[part 2 of 4: package /PATAC/MSM/ComponentTypes]
AUTOSAR XML (schema 4-0-3)
package /PATAC/MSM/ComponentTypes  (continued)
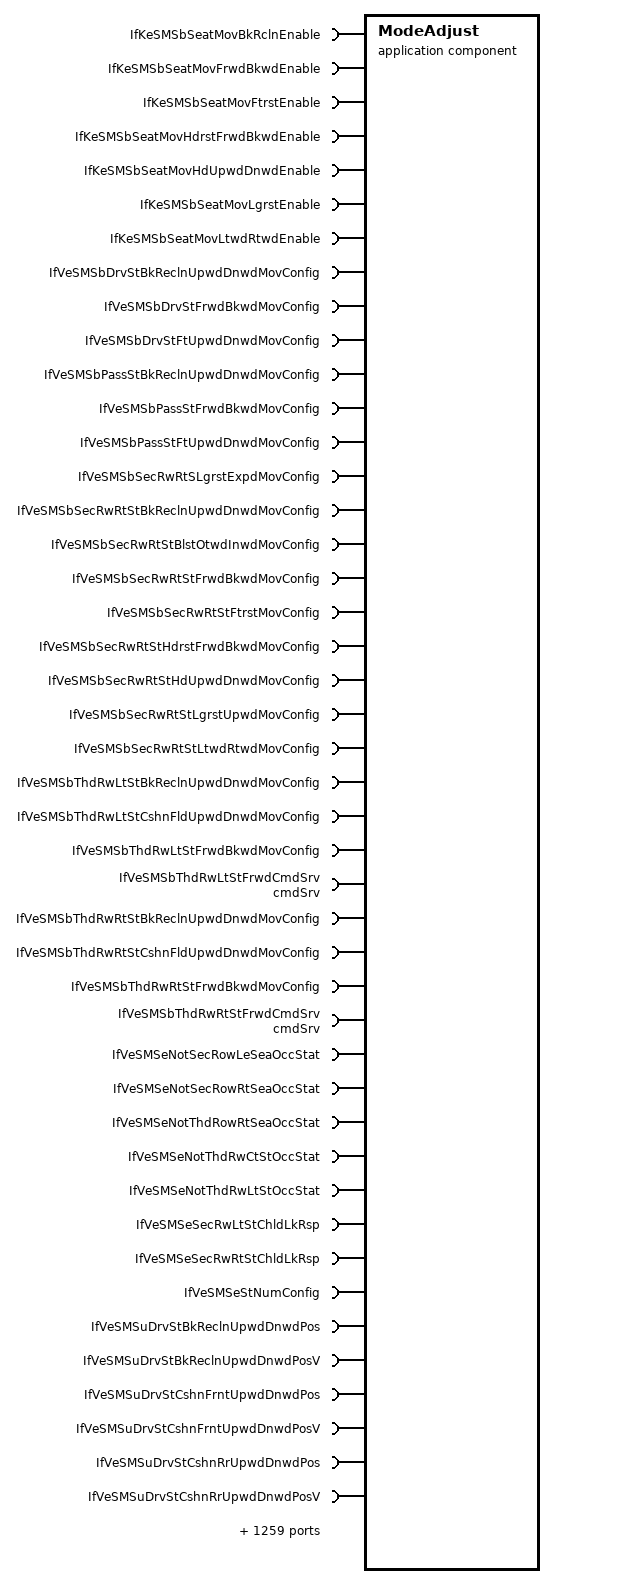
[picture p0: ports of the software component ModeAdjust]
  application sw component type ModeAdjust  (continued)
    1303 x require port:
      IfKeSMSbSeatMovBkRclnEnable: parameter-require-com-spec{init-value=1, parameter=IfKeSMSbSeatMovBkRclnEnable/Val}, required-interface=IfKeSMSbSeatMovBkRclnEnable
      IfKeSMSbSeatMovFrwdBkwdEnable: parameter-require-com-spec{init-value=1, parameter=IfKeSMSbSeatMovFrwdBkwdEnable/Val}, required-interface=IfKeSMSbSeatMovFrwdBkwdEnable
      IfKeSMSbSeatMovFtrstEnable: parameter-require-com-spec{init-value=1, parameter=IfKeSMSbSeatMovFtrstEnable/Val}, required-interface=IfKeSMSbSeatMovFtrstEnable
      IfKeSMSbSeatMovHdrstFrwdBkwdEnable: parameter-require-com-spec{init-value=1, parameter=IfKeSMSbSeatMovHdrstFrwdBkwdEnable/Val}, required-interface=IfKeSMSbSeatMovHdrstFrwdBkwdEnable
      IfKeSMSbSeatMovHdUpwdDnwdEnable: parameter-require-com-spec{init-value=1, parameter=IfKeSMSbSeatMovHdUpwdDnwdEnable/Val}, required-interface=IfKeSMSbSeatMovHdUpwdDnwdEnable
      IfKeSMSbSeatMovLgrstEnable: parameter-require-com-spec{init-value=1, parameter=IfKeSMSbSeatMovLgrstEnable/Val}, required-interface=IfKeSMSbSeatMovLgrstEnable
      IfKeSMSbSeatMovLtwdRtwdEnable: parameter-require-com-spec{init-value=1, parameter=IfKeSMSbSeatMovLtwdRtwdEnable/Val}, required-interface=IfKeSMSbSeatMovLtwdRtwdEnable
      IfVeSMSbDrvStBkReclnUpwdDnwdMovConfig: nonqueued-receiver-com-spec{data-element=IfVeSMSbDrvStBkReclnUpwdDnwdMovConfig/Val, filter=data-filter-type=ALWAYS, init-value=0}, required-interface=IfVeSMSbDrvStBkReclnUpwdDnwdMovConfig
      IfVeSMSbDrvStFrwdBkwdMovConfig: nonqueued-receiver-com-spec{data-element=IfVeSMSbDrvStFrwdBkwdMovConfig/Val, filter=data-filter-type=ALWAYS, init-value=0}, required-interface=IfVeSMSbDrvStFrwdBkwdMovConfig
      IfVeSMSbDrvStFtUpwdDnwdMovConfig: nonqueued-receiver-com-spec{data-element=IfVeSMSbDrvStFtUpwdDnwdMovConfig/Val, filter=data-filter-type=ALWAYS, init-value=0}, required-interface=IfVeSMSbDrvStFtUpwdDnwdMovConfig
      IfVeSMSbPassStBkReclnUpwdDnwdMovConfig: nonqueued-receiver-com-spec{data-element=IfVeSMSbPassStBkReclnUpwdDnwdMovConfig/Val, filter=data-filter-type=ALWAYS, init-value=0}, required-interface=IfVeSMSbPassStBkReclnUpwdDnwdMovConfig
      IfVeSMSbPassStFrwdBkwdMovConfig: nonqueued-receiver-com-spec{data-element=IfVeSMSbPassStFrwdBkwdMovConfig/Val, filter=data-filter-type=ALWAYS, init-value=0}, required-interface=IfVeSMSbPassStFrwdBkwdMovConfig
      IfVeSMSbPassStFtUpwdDnwdMovConfig: nonqueued-receiver-com-spec{data-element=IfVeSMSbPassStFtUpwdDnwdMovConfig/Val, filter=data-filter-type=ALWAYS, init-value=0}, required-interface=IfVeSMSbPassStFtUpwdDnwdMovConfig
      IfVeSMSbSecRwRtSLgrstExpdMovConfig: nonqueued-receiver-com-spec{data-element=IfVeSMSbSecRwRtSLgrstExpdMovConfig/Val, filter=data-filter-type=ALWAYS, init-value=0}, required-interface=IfVeSMSbSecRwRtSLgrstExpdMovConfig
      IfVeSMSbSecRwRtStBkReclnUpwdDnwdMovConfig: nonqueued-receiver-com-spec{data-element=IfVeSMSbSecRwRtStBkReclnUpwdDnwdMovConfig/Val, filter=data-filter-type=ALWAYS, init-value=0}, required-interface=IfVeSMSbSecRwRtStBkReclnUpwdDnwdMovConfig
      IfVeSMSbSecRwRtStBlstOtwdInwdMovConfig: nonqueued-receiver-com-spec{data-element=IfVeSMSbSecRwRtStBlstOtwdInwdMovConfig/Val, filter=data-filter-type=ALWAYS, init-value=0}, required-interface=IfVeSMSbSecRwRtStBlstOtwdInwdMovConfig
      IfVeSMSbSecRwRtStFrwdBkwdMovConfig: nonqueued-receiver-com-spec{data-element=IfVeSMSbSecRwRtStFrwdBkwdMovConfig/Val, filter=data-filter-type=ALWAYS, init-value=0}, required-interface=IfVeSMSbSecRwRtStFrwdBkwdMovConfig
      IfVeSMSbSecRwRtStFtrstMovConfig: nonqueued-receiver-com-spec{data-element=IfVeSMSbSecRwRtStFtrstMovConfig/Val, filter=data-filter-type=ALWAYS, init-value=0}, required-interface=IfVeSMSbSecRwRtStFtrstMovConfig
      IfVeSMSbSecRwRtStHdrstFrwdBkwdMovConfig: nonqueued-receiver-com-spec{data-element=IfVeSMSbSecRwRtStHdrstFrwdBkwdMovConfig/Val, filter=data-filter-type=ALWAYS, init-value=0}, required-interface=IfVeSMSbSecRwRtStHdrstFrwdBkwdMovConfig
      IfVeSMSbSecRwRtStHdUpwdDnwdMovConfig: nonqueued-receiver-com-spec{data-element=IfVeSMSbSecRwRtStHdUpwdDnwdMovConfig/Val, filter=data-filter-type=ALWAYS, init-value=0}, required-interface=IfVeSMSbSecRwRtStHdUpwdDnwdMovConfig
      IfVeSMSbSecRwRtStLgrstUpwdMovConfig: nonqueued-receiver-com-spec{data-element=IfVeSMSbSecRwRtStLgrstUpwdMovConfig/Val, filter=data-filter-type=ALWAYS, init-value=0}, required-interface=IfVeSMSbSecRwRtStLgrstUpwdMovConfig
      IfVeSMSbSecRwRtStLtwdRtwdMovConfig: nonqueued-receiver-com-spec{data-element=IfVeSMSbSecRwRtStLtwdRtwdMovConfig/Val, filter=data-filter-type=ALWAYS, init-value=0}, required-interface=IfVeSMSbSecRwRtStLtwdRtwdMovConfig
      IfVeSMSbThdRwLtStBkReclnUpwdDnwdMovConfig: nonqueued-receiver-com-spec{data-element=IfVeSMSbThdRwLtStBkReclnUpwdDnwdMovConfig/Val, filter=data-filter-type=ALWAYS, init-value=0}, required-interface=IfVeSMSbThdRwLtStBkReclnUpwdDnwdMovConfig
      IfVeSMSbThdRwLtStCshnFldUpwdDnwdMovConfig: nonqueued-receiver-com-spec{data-element=IfVeSMSbThdRwLtStCshnFldUpwdDnwdMovConfig/Val, filter=data-filter-type=ALWAYS, init-value=0}, required-interface=IfVeSMSbThdRwLtStCshnFldUpwdDnwdMovConfig
      IfVeSMSbThdRwLtStFrwdBkwdMovConfig: nonqueued-receiver-com-spec{data-element=IfVeSMSbThdRwLtStFrwdBkwdMovConfig/Val, filter=data-filter-type=ALWAYS, init-value=0}, required-interface=IfVeSMSbThdRwLtStFrwdBkwdMovConfig
      IfVeSMSbThdRwLtStFrwdCmdSrv: nonqueued-receiver-com-spec{data-element=cmdSrv/Val, filter=data-filter-type=ALWAYS, init-value=1}, required-interface=cmdSrv
      IfVeSMSbThdRwRtStBkReclnUpwdDnwdMovConfig: nonqueued-receiver-com-spec{data-element=IfVeSMSbThdRwRtStBkReclnUpwdDnwdMovConfig/Val, filter=data-filter-type=ALWAYS, init-value=0}, required-interface=IfVeSMSbThdRwRtStBkReclnUpwdDnwdMovConfig
      IfVeSMSbThdRwRtStCshnFldUpwdDnwdMovConfig: nonqueued-receiver-com-spec{data-element=IfVeSMSbThdRwRtStCshnFldUpwdDnwdMovConfig/Val, filter=data-filter-type=ALWAYS, init-value=0}, required-interface=IfVeSMSbThdRwRtStCshnFldUpwdDnwdMovConfig
      IfVeSMSbThdRwRtStFrwdBkwdMovConfig: nonqueued-receiver-com-spec{data-element=IfVeSMSbThdRwRtStFrwdBkwdMovConfig/Val, filter=data-filter-type=ALWAYS, init-value=0}, required-interface=IfVeSMSbThdRwRtStFrwdBkwdMovConfig
      IfVeSMSbThdRwRtStFrwdCmdSrv: nonqueued-receiver-com-spec{data-element=cmdSrv/Val, filter=data-filter-type=ALWAYS, init-value=1}, required-interface=cmdSrv
      IfVeSMSeNotSecRowLeSeaOccStat: nonqueued-receiver-com-spec{data-element=IfVeSMSeNotSecRowLeSeaOccStat/Val, filter=data-filter-type=ALWAYS, init-value=0}, required-interface=IfVeSMSeNotSecRowLeSeaOccStat
      IfVeSMSeNotSecRowRtSeaOccStat: nonqueued-receiver-com-spec{data-element=IfVeSMSeNotSecRowRtSeaOccStat/Val, filter=data-filter-type=ALWAYS, init-value=0}, required-interface=IfVeSMSeNotSecRowRtSeaOccStat
      IfVeSMSeNotThdRowRtSeaOccStat: nonqueued-receiver-com-spec{data-element=IfVeSMSeNotThdRowRtSeaOccStat/Val, filter=data-filter-type=ALWAYS, init-value=0}, required-interface=IfVeSMSeNotThdRowRtSeaOccStat
      IfVeSMSeNotThdRwCtStOccStat: nonqueued-receiver-com-spec{data-element=IfVeSMSeNotThdRwCtStOccStat/Val, filter=data-filter-type=ALWAYS, init-value=0}, required-interface=IfVeSMSeNotThdRwCtStOccStat
      IfVeSMSeNotThdRwLtStOccStat: nonqueued-receiver-com-spec{data-element=IfVeSMSeNotThdRwLtStOccStat/Val, filter=data-filter-type=ALWAYS, init-value=0}, required-interface=IfVeSMSeNotThdRwLtStOccStat
      IfVeSMSeSecRwLtStChldLkRsp: nonqueued-receiver-com-spec{data-element=IfVeSMSeSecRwLtStChldLkRsp/Val, filter=data-filter-type=ALWAYS, init-value=0}, required-interface=IfVeSMSeSecRwLtStChldLkRsp
      IfVeSMSeSecRwRtStChldLkRsp: nonqueued-receiver-com-spec{data-element=IfVeSMSeSecRwRtStChldLkRsp/Val, filter=data-filter-type=ALWAYS, init-value=0}, required-interface=IfVeSMSeSecRwRtStChldLkRsp
      IfVeSMSeStNumConfig: nonqueued-receiver-com-spec{data-element=IfVeSMSeStNumConfig/Val, filter=data-filter-type=ALWAYS, init-value=2}, required-interface=IfVeSMSeStNumConfig
      IfVeSMSuDrvStBkReclnUpwdDnwdPos: nonqueued-receiver-com-spec{data-element=IfVeSMSuDrvStBkReclnUpwdDnwdPos/Val, filter=data-filter-type=ALWAYS, init-value=0}, required-interface=IfVeSMSuDrvStBkReclnUpwdDnwdPos
      IfVeSMSuDrvStBkReclnUpwdDnwdPosV: nonqueued-receiver-com-spec{data-element=IfVeSMSuDrvStBkReclnUpwdDnwdPosV/Val, filter=data-filter-type=ALWAYS, init-value=0}, required-interface=IfVeSMSuDrvStBkReclnUpwdDnwdPosV
      IfVeSMSuDrvStCshnFrntUpwdDnwdPos: nonqueued-receiver-com-spec{data-element=IfVeSMSuDrvStCshnFrntUpwdDnwdPos/Val, filter=data-filter-type=ALWAYS, init-value=0}, required-interface=IfVeSMSuDrvStCshnFrntUpwdDnwdPos
      IfVeSMSuDrvStCshnFrntUpwdDnwdPosV: nonqueued-receiver-com-spec{data-element=IfVeSMSuDrvStCshnFrntUpwdDnwdPosV/Val, filter=data-filter-type=ALWAYS, init-value=0}, required-interface=IfVeSMSuDrvStCshnFrntUpwdDnwdPosV
      IfVeSMSuDrvStCshnRrUpwdDnwdPos: nonqueued-receiver-com-spec{data-element=IfVeSMSuDrvStCshnRrUpwdDnwdPos/Val, filter=data-filter-type=ALWAYS, init-value=0}, required-interface=IfVeSMSuDrvStCshnRrUpwdDnwdPos
      IfVeSMSuDrvStCshnRrUpwdDnwdPosV: nonqueued-receiver-com-spec{data-element=IfVeSMSuDrvStCshnRrUpwdDnwdPosV/Val, filter=data-filter-type=ALWAYS, init-value=0}, required-interface=IfVeSMSuDrvStCshnRrUpwdDnwdPosV
      IfVeSMSuDrvStFrwdBkwdPos: nonqueued-receiver-com-spec{data-element=IfVeSMSuDrvStFrwdBkwdPos/Val, filter=data-filter-type=ALWAYS, init-value=0}, required-interface=IfVeSMSuDrvStFrwdBkwdPos
      IfVeSMSuDrvStFrwdBkwdPosV: nonqueued-receiver-com-spec{data-element=IfVeSMSuDrvStFrwdBkwdPosV/Val, filter=data-filter-type=ALWAYS, init-value=0}, required-interface=IfVeSMSuDrvStFrwdBkwdPosV
      IfVeSMSuDrvStFtUpwdDnwdPos: nonqueued-receiver-com-spec{data-element=IfVeSMSuDrvStFtUpwdDnwdPos/Val, filter=data-filter-type=ALWAYS, init-value=0}, required-interface=IfVeSMSuDrvStFtUpwdDnwdPos
      IfVeSMSuDrvStFtUpwdDnwdPosV: nonqueued-receiver-com-spec{data-element=IfVeSMSuDrvStFtUpwdDnwdPosV/Val, filter=data-filter-type=ALWAYS, init-value=0}, required-interface=IfVeSMSuDrvStFtUpwdDnwdPosV
      IfVeSMSuPassStBkReclnUpwdDnwdPos: nonqueued-receiver-com-spec{data-element=IfVeSMSuPassStBkReclnUpwdDnwdPos/Val, filter=data-filter-type=ALWAYS, init-value=0}, required-interface=IfVeSMSuPassStBkReclnUpwdDnwdPos
      IfVeSMSuPassStBkReclnUpwdDnwdPosV: nonqueued-receiver-com-spec{data-element=IfVeSMSuPassStBkReclnUpwdDnwdPosV/Val, filter=data-filter-type=ALWAYS, init-value=0}, required-interface=IfVeSMSuPassStBkReclnUpwdDnwdPosV
      IfVeSMSuPassStCshnFrntUpwdDnwdPos: nonqueued-receiver-com-spec{data-element=IfVeSMSuPassStCshnFrntUpwdDnwdPos/Val, filter=data-filter-type=ALWAYS, init-value=0}, required-interface=IfVeSMSuPassStCshnFrntUpwdDnwdPos
      IfVeSMSuPassStCshnFrntUpwdDnwdPosV: nonqueued-receiver-com-spec{data-element=IfVeSMSuPassStCshnFrntUpwdDnwdPosV/Val, filter=data-filter-type=ALWAYS, init-value=0}, required-interface=IfVeSMSuPassStCshnFrntUpwdDnwdPosV
      IfVeSMSuPassStCshnRrUpwdDnwdPos: nonqueued-receiver-com-spec{data-element=IfVeSMSuPassStCshnRrUpwdDnwdPos/Val, filter=data-filter-type=ALWAYS, init-value=0}, required-interface=IfVeSMSuPassStCshnRrUpwdDnwdPos
      IfVeSMSuPassStCshnRrUpwdDnwdPosV: nonqueued-receiver-com-spec{data-element=IfVeSMSuPassStCshnRrUpwdDnwdPosV/Val, filter=data-filter-type=ALWAYS, init-value=0}, required-interface=IfVeSMSuPassStCshnRrUpwdDnwdPosV
      IfVeSMSuPassStFrwdBkwdPos: nonqueued-receiver-com-spec{data-element=IfVeSMSuPassStFrwdBkwdPos/Val, filter=data-filter-type=ALWAYS, init-value=0}, required-interface=IfVeSMSuPassStFrwdBkwdPos
      IfVeSMSuPassStFrwdBkwdPosV: nonqueued-receiver-com-spec{data-element=IfVeSMSuPassStFrwdBkwdPosV/Val, filter=data-filter-type=ALWAYS, init-value=0}, required-interface=IfVeSMSuPassStFrwdBkwdPosV
      IfVeSMSuPassStFtUpwdDnwdPos: nonqueued-receiver-com-spec{data-element=IfVeSMSuPassStFtUpwdDnwdPos/Val, filter=data-filter-type=ALWAYS, init-value=0}, required-interface=IfVeSMSuPassStFtUpwdDnwdPos
      IfVeSMSuPassStFtUpwdDnwdPosV: nonqueued-receiver-com-spec{data-element=IfVeSMSuPassStFtUpwdDnwdPosV/Val, filter=data-filter-type=ALWAYS, init-value=0}, required-interface=IfVeSMSuPassStFtUpwdDnwdPosV
      IfVeSMSuRrLtStFtUpwdDnwdPos: nonqueued-receiver-com-spec{data-element=IfVeSMSuRrLtStFtUpwdDnwdPos/Val, filter=data-filter-type=ALWAYS, init-value=0}, required-interface=IfVeSMSuRrLtStFtUpwdDnwdPos
      IfVeSMSuRrLtStFtUpwdDnwdPosV: nonqueued-receiver-com-spec{data-element=IfVeSMSuRrLtStFtUpwdDnwdPosV/Val, filter=data-filter-type=ALWAYS, init-value=0}, required-interface=IfVeSMSuRrLtStFtUpwdDnwdPosV
      IfVeSMSuRrRtStFtUpwdDnwdPos: nonqueued-receiver-com-spec{data-element=IfVeSMSuRrRtStFtUpwdDnwdPos/Val, filter=data-filter-type=ALWAYS, init-value=0}, required-interface=IfVeSMSuRrRtStFtUpwdDnwdPos
      IfVeSMSuRrRtStFtUpwdDnwdPosV: nonqueued-receiver-com-spec{data-element=IfVeSMSuRrRtStFtUpwdDnwdPosV/Val, filter=data-filter-type=ALWAYS, init-value=0}, required-interface=IfVeSMSuRrRtStFtUpwdDnwdPosV
      IfVeSMSuSecRwLtStArmScrnPos: nonqueued-receiver-com-spec{data-element=PercPos/Val, filter=data-filter-type=ALWAYS, init-value=0}, required-interface=PercPos
      IfVeSMSuSecRwLtStArmScrnPosV: nonqueued-receiver-com-spec{data-element=PercPosV/Val, filter=data-filter-type=ALWAYS, init-value=0}, required-interface=PercPosV
      IfVeSMSuSecRwLtStBkReclnUpwdDnwdPos: nonqueued-receiver-com-spec{data-element=IfVeSMSuSecRwLtStBkReclnUpwdDnwdPos/Val, filter=data-filter-type=ALWAYS, init-value=0}, required-interface=IfVeSMSuSecRwLtStBkReclnUpwdDnwdPos
      IfVeSMSuSecRwLtStBkReclnUpwdDnwdPosV: nonqueued-receiver-com-spec{data-element=IfVeSMSuSecRwLtStBkReclnUpwdDnwdPosV/Val, filter=data-filter-type=ALWAYS, init-value=0}, required-interface=IfVeSMSuSecRwLtStBkReclnUpwdDnwdPosV
      IfVeSMSuSecRwLtStFrwdBkwdPos: nonqueued-receiver-com-spec{data-element=IfVeSMSuSecRwLtStFrwdBkwdPos/Val, filter=data-filter-type=ALWAYS, init-value=0}, required-interface=IfVeSMSuSecRwLtStFrwdBkwdPos
      IfVeSMSuSecRwLtStFrwdBkwdPosV: nonqueued-receiver-com-spec{data-element=IfVeSMSuSecRwLtStFrwdBkwdPosV/Val, filter=data-filter-type=ALWAYS, init-value=0}, required-interface=IfVeSMSuSecRwLtStFrwdBkwdPosV
      IfVeSMSuSecRwLtStHdrstFrwdBkwdPos: nonqueued-receiver-com-spec{data-element=IfVeSMSuSecRwLtStHdrstFrwdBkwdPos/Val, filter=data-filter-type=ALWAYS, init-value=0}, required-interface=IfVeSMSuSecRwLtStHdrstFrwdBkwdPos
      IfVeSMSuSecRwLtStHdrstFrwdBkwdPosV: nonqueued-receiver-com-spec{data-element=IfVeSMSuSecRwLtStHdrstFrwdBkwdPosV/Val, filter=data-filter-type=ALWAYS, init-value=0}, required-interface=IfVeSMSuSecRwLtStHdrstFrwdBkwdPosV
      IfVeSMSuSecRwLtStHdrstUpwdDnwdPos: nonqueued-receiver-com-spec{data-element=IfVeSMSuSecRwLtStHdrstUpwdDnwdPos/Val, filter=data-filter-type=ALWAYS, init-value=0}, required-interface=IfVeSMSuSecRwLtStHdrstUpwdDnwdPos
      IfVeSMSuSecRwLtStHdrstUpwdDnwdPosV: nonqueued-receiver-com-spec{data-element=IfVeSMSuSecRwLtStHdrstUpwdDnwdPosV/Val, filter=data-filter-type=ALWAYS, init-value=0}, required-interface=IfVeSMSuSecRwLtStHdrstUpwdDnwdPosV
      IfVeSMSuSecRwLtStLgrstOtwdInwdPos: nonqueued-receiver-com-spec{data-element=IfVeSMSuSecRwLtStLgrstOtwdInwdPos/Val, filter=data-filter-type=ALWAYS, init-value=0}, required-interface=IfVeSMSuSecRwLtStLgrstOtwdInwdPos
      IfVeSMSuSecRwLtStLgrstOtwdInwdPosV: nonqueued-receiver-com-spec{data-element=IfVeSMSuSecRwLtStLgrstOtwdInwdPosV/Val, filter=data-filter-type=ALWAYS, init-value=0}, required-interface=IfVeSMSuSecRwLtStLgrstOtwdInwdPosV
      IfVeSMSuSecRwLtStLgrstUpwdDnwdPos: nonqueued-receiver-com-spec{data-element=IfVeSMSuSecRwLtStLgrstUpwdDnwdPos/Val, filter=data-filter-type=ALWAYS, init-value=0}, required-interface=IfVeSMSuSecRwLtStLgrstUpwdDnwdPos
      IfVeSMSuSecRwLtStLgrstUpwdDnwdPosV: nonqueued-receiver-com-spec{data-element=IfVeSMSuSecRwLtStLgrstUpwdDnwdPosV/Val, filter=data-filter-type=ALWAYS, init-value=0}, required-interface=IfVeSMSuSecRwLtStLgrstUpwdDnwdPosV
      IfVeSMSuSecRwLtStLtwdRtwdPos: nonqueued-receiver-com-spec{data-element=IfVeSMSuSecRwLtStLtwdRtwdPos/Val, filter=data-filter-type=ALWAYS, init-value=0}, required-interface=IfVeSMSuSecRwLtStLtwdRtwdPos
      IfVeSMSuSecRwLtStLtwdRtwdPosV: nonqueued-receiver-com-spec{data-element=IfVeSMSuSecRwLtStLtwdRtwdPosV/Val, filter=data-filter-type=ALWAYS, init-value=0}, required-interface=IfVeSMSuSecRwLtStLtwdRtwdPosV
      IfVeSMSuSecRwRtStArmScrnPos: nonqueued-receiver-com-spec{data-element=PercPos/Val, filter=data-filter-type=ALWAYS, init-value=0}, required-interface=PercPos
      IfVeSMSuSecRwRtStArmScrnPosV: nonqueued-receiver-com-spec{data-element=PercPosV/Val, filter=data-filter-type=ALWAYS, init-value=0}, required-interface=PercPosV
      IfVeSMSuSecRwRtStBkReclnUpwdDnwdPos: nonqueued-receiver-com-spec{data-element=IfVeSMSuSecRwRtStBkReclnUpwdDnwdPos/Val, filter=data-filter-type=ALWAYS, init-value=0}, required-interface=IfVeSMSuSecRwRtStBkReclnUpwdDnwdPos
      IfVeSMSuSecRwRtStBkReclnUpwdDnwdPosV: nonqueued-receiver-com-spec{data-element=IfVeSMSuSecRwRtStBkReclnUpwdDnwdPosV/Val, filter=data-filter-type=ALWAYS, init-value=0}, required-interface=IfVeSMSuSecRwRtStBkReclnUpwdDnwdPosV
      IfVeSMSuSecRwRtStFrwdBkwdPos: nonqueued-receiver-com-spec{data-element=PercPos/Val, filter=data-filter-type=ALWAYS, init-value=0}, required-interface=PercPos
      IfVeSMSuSecRwRtStFrwdBkwdPosV: nonqueued-receiver-com-spec{data-element=IfVeSMSuSecRwRtStFrwdBkwdPosV/Val, filter=data-filter-type=ALWAYS, init-value=0}, required-interface=IfVeSMSuSecRwRtStFrwdBkwdPosV
      IfVeSMSuSecRwRtStHdrstFrwdBkwdPos: nonqueued-receiver-com-spec{data-element=IfVeSMSuSecRwRtStHdrstFrwdBkwdPos/Val, filter=data-filter-type=ALWAYS, init-value=0}, required-interface=IfVeSMSuSecRwRtStHdrstFrwdBkwdPos
      IfVeSMSuSecRwRtStHdrstFrwdBkwdPosV: nonqueued-receiver-com-spec{data-element=IfVeSMSuSecRwRtStHdrstFrwdBkwdPosV/Val, filter=data-filter-type=ALWAYS, init-value=0}, required-interface=IfVeSMSuSecRwRtStHdrstFrwdBkwdPosV
      IfVeSMSuSecRwRtStHdrstUpwdDnwdPos: nonqueued-receiver-com-spec{data-element=IfVeSMSuSecRwRtStHdrstUpwdDnwdPos/Val, filter=data-filter-type=ALWAYS, init-value=0}, required-interface=IfVeSMSuSecRwRtStHdrstUpwdDnwdPos
      IfVeSMSuSecRwRtStHPassStUpwdDnwdPosV: nonqueued-receiver-com-spec{data-element=IfVeSMSuSecRwRtStHPassStUpwdDnwdPosV/Val, filter=data-filter-type=ALWAYS, init-value=0}, required-interface=IfVeSMSuSecRwRtStHPassStUpwdDnwdPosV
      IfVeSMSuSecRwRtStLgrstOtwdInwdPos: nonqueued-receiver-com-spec{data-element=IfVeSMSuSecRwRtStLgrstOtwdInwdPos/Val, filter=data-filter-type=ALWAYS, init-value=0}, required-interface=IfVeSMSuSecRwRtStLgrstOtwdInwdPos
      IfVeSMSuSecRwRtStLgrstOtwdInwdPosV: nonqueued-receiver-com-spec{data-element=IfVeSMSuSecRwRtStLgrstOtwdInwdPosV/Val, filter=data-filter-type=ALWAYS, init-value=0}, required-interface=IfVeSMSuSecRwRtStLgrstOtwdInwdPosV
      IfVeSMSuSecRwRtStLgrstUpwdDnwdPos: nonqueued-receiver-com-spec{data-element=IfVeSMSuSecRwRtStLgrstUpwdDnwdPos/Val, filter=data-filter-type=ALWAYS, init-value=0}, required-interface=IfVeSMSuSecRwRtStLgrstUpwdDnwdPos
      IfVeSMSuSecRwRtStLgrstUpwdDnwdPosV: nonqueued-receiver-com-spec{data-element=IfVeSMSuSecRwRtStLgrstUpwdDnwdPosV/Val, filter=data-filter-type=ALWAYS, init-value=0}, required-interface=IfVeSMSuSecRwRtStLgrstUpwdDnwdPosV
      IfVeSMSuSecRwRtStLtwdRtwdPos: nonqueued-receiver-com-spec{data-element=IfVeSMSuSecRwRtStLtwdRtwdPos/Val, filter=data-filter-type=ALWAYS, init-value=0}, required-interface=IfVeSMSuSecRwRtStLtwdRtwdPos
      IfVeSMSuSecRwRtStLtwdRtwdPosV: nonqueued-receiver-com-spec{data-element=IfVeSMSuSecRwRtStLtwdRtwdPosV/Val, filter=data-filter-type=ALWAYS, init-value=0}, required-interface=IfVeSMSuSecRwRtStLtwdRtwdPosV
      IfVeSMSuThdRwLtStBkReclnUpwdDnwdPos: nonqueued-receiver-com-spec{data-element=IfVeSMSuThdRwLtStBkReclnUpwdDnwdPos/Val, filter=data-filter-type=ALWAYS, init-value=0}, required-interface=IfVeSMSuThdRwLtStBkReclnUpwdDnwdPos
      IfVeSMSuThdRwLtStBkReclnUpwdDnwdPosV: nonqueued-receiver-com-spec{data-element=IfVeSMSuThdRwLtStBkReclnUpwdDnwdPosV/Val, filter=data-filter-type=ALWAYS, init-value=0}, required-interface=IfVeSMSuThdRwLtStBkReclnUpwdDnwdPosV
      IfVeSMSuThdRwLtStCshnFldUpwdDnwdPos: nonqueued-receiver-com-spec{data-element=IfVeSMSuThdRwLtStCshnFldUpwdDnwdPos/Val, filter=data-filter-type=ALWAYS, init-value=0}, required-interface=IfVeSMSuThdRwLtStCshnFldUpwdDnwdPos
      IfVeSMSuThdRwLtStCshnFldUpwdDnwdPosV: nonqueued-receiver-com-spec{data-element=IfVeSMSuThdRwLtStCshnFldUpwdDnwdPosV/Val, filter=data-filter-type=ALWAYS, init-value=0}, required-interface=IfVeSMSuThdRwLtStCshnFldUpwdDnwdPosV
      IfVeSMSuThdRwLtStFrwdBkwdPos: nonqueued-receiver-com-spec{data-element=IfVeSMSuThdRwLtStFrwdBkwdPos/Val, filter=data-filter-type=ALWAYS, init-value=0}, required-interface=IfVeSMSuThdRwLtStFrwdBkwdPos
      IfVeSMSuThdRwLtStFrwdBkwdPosV: nonqueued-receiver-com-spec{data-element=IfVeSMSuThdRwLtStFrwdBkwdPosV/Val, filter=data-filter-type=ALWAYS, init-value=0}, required-interface=IfVeSMSuThdRwLtStFrwdBkwdPosV
      IfVeSMSuThdRwRStFrwdBkwdPos: nonqueued-receiver-com-spec{data-element=IfVeSMSuThdRwRStFrwdBkwdPos/Val, filter=data-filter-type=ALWAYS, init-value=0}, required-interface=IfVeSMSuThdRwRStFrwdBkwdPos
      IfVeSMSuThdRwRtStBkReclnUpwdDnwdPos: nonqueued-receiver-com-spec{data-element=IfVeSMSuThdRwRtStBkReclnUpwdDnwdPos/Val, filter=data-filter-type=ALWAYS, init-value=0}, required-interface=IfVeSMSuThdRwRtStBkReclnUpwdDnwdPos
      IfVeSMSuThdRwRtStBkReclnUpwdDnwdPosV: nonqueued-receiver-com-spec{data-element=IfVeSMSuThdRwRtStBkReclnUpwdDnwdPosV/Val, filter=data-filter-type=ALWAYS, init-value=0}, required-interface=IfVeSMSuThdRwRtStBkReclnUpwdDnwdPosV
      IfVeSMSuThdRwRtStCshnFldUpwdDnwdPos: nonqueued-receiver-com-spec{data-element=IfVeSMSuThdRwRtStCshnFldUpwdDnwdPos/Val, filter=data-filter-type=ALWAYS, init-value=0}, required-interface=IfVeSMSuThdRwRtStCshnFldUpwdDnwdPos
      IfVeSMSuThdRwRtStCshnFldUpwdDnwdPosV: nonqueued-receiver-com-spec{data-element=IfVeSMSuThdRwRtStCshnFldUpwdDnwdPosV/Val, filter=data-filter-type=ALWAYS, init-value=0}, required-interface=IfVeSMSuThdRwRtStCshnFldUpwdDnwdPosV
      IfVeSMSuThdRwRtStFrwdBkwdPosV: nonqueued-receiver-com-spec{data-element=IfVeSMSuThdRwRtStFrwdBkwdPosV/Val, filter=data-filter-type=ALWAYS, init-value=0}, required-interface=IfVeSMSuThdRwRtStFrwdBkwdPosV
      KeSMSbArmscreenMovEnable: parameter-require-com-spec{init-value=1, parameter=KeSMSbArmscreenMovEnable/Val}, required-interface=KeSMSbArmscreenMovEnable
      KeSMSbSeatMovLgrstExpdEnable: parameter-require-com-spec{init-value=0, parameter=KeSMSbSeatMovLgrstExpdEnable/Val}, required-interface=KeSMSbSeatMovLgrstExpdEnable
      KeSMSuFirstRwStBackPosDelta: parameter-require-com-spec{init-value=150, parameter=MdPosDelta/Val}, required-interface=MdPosDelta
      KeSMSuFirstRwStBackPosTolr: parameter-require-com-spec{init-value=150, parameter=MdPosDelta/Val}, required-interface=MdPosDelta
      KeSMSuFirstRwStCushFrntPosDelta: parameter-require-com-spec{init-value=150, parameter=MdPosDelta/Val}, required-interface=MdPosDelta
      KeSMSuFirstRwStCushFrntPosTolr: parameter-require-com-spec{init-value=150, parameter=MdPosDelta/Val}, required-interface=MdPosDelta
      KeSMSuFirstRwStCushRePosDelta: parameter-require-com-spec{init-value=150, parameter=MdPosDelta/Val}, required-interface=MdPosDelta
      KeSMSuFirstRwStCushRePosTolr: parameter-require-com-spec{init-value=150, parameter=MdPosDelta/Val}, required-interface=MdPosDelta
      KeSMSuFirstRwStFootrestPosDelta: parameter-require-com-spec{init-value=150, parameter=MdPosDelta/Val}, required-interface=MdPosDelta
      KeSMSuFirstRwStFootrestPosTolr: parameter-require-com-spec{init-value=150, parameter=MdPosDelta/Val}, required-interface=MdPosDelta
      KeSMSuFirstRwStFwdBkwdPosDelta: parameter-require-com-spec{init-value=150, parameter=MdPosDelta/Val}, required-interface=MdPosDelta
      KeSMSuFirstRwStFwdBkwdPosTolr: parameter-require-com-spec{init-value=150, parameter=MdPosDelta/Val}, required-interface=MdPosDelta
      KeSMSuMdMotFinshdTm: parameter-require-com-spec{init-value=100, parameter=KeSMSuMdMotFinshdTm/Val}, required-interface=KeSMSuMdMotFinshdTm
      KeSMSuMdRetryTm1: parameter-require-com-spec{init-value=20, parameter=KeSMSuMdRetryTm1/Val}, required-interface=KeSMSuMdRetryTm1
      KeSMSuModeReqDurgTm: parameter-require-com-spec{init-value=300, parameter=KeSMSuModeReqDurgTm/Val}, required-interface=KeSMSuModeReqDurgTm
      KeSMSuSecRwStArmTochPosDelta: parameter-require-com-spec{init-value=150, parameter=MdPosDelta/Val}, required-interface=MdPosDelta
      KeSMSuSecRwStArmTochPosTolr: parameter-require-com-spec{init-value=150, parameter=MdPosDelta/Val}, required-interface=MdPosDelta
      KeSMSuSecRwStBackPosDelta: parameter-require-com-spec{init-value=150, parameter=MdPosDelta/Val}, required-interface=MdPosDelta
      KeSMSuSecRwStBackPosTolr: parameter-require-com-spec{init-value=150, parameter=MdPosDelta/Val}, required-interface=MdPosDelta
      KeSMSuSecRwStFtrstUpwdDnwdPosDelta: parameter-require-com-spec{init-value=150, parameter=MdPosDelta/Val}, required-interface=MdPosDelta
      KeSMSuSecRwStFtrstUpwdDnwdPosTolr: parameter-require-com-spec{init-value=150, parameter=MdPosDelta/Val}, required-interface=MdPosDelta
      KeSMSuSecRwStFwdBkwdPosDelta: parameter-require-com-spec{init-value=300, parameter=MdPosDelta/Val}, required-interface=MdPosDelta
      KeSMSuSecRwStFwdBkwdPosTolr: parameter-require-com-spec{init-value=300, parameter=MdPosDelta/Val}, required-interface=MdPosDelta
      KeSMSuSecRwStHeadrestFwdBkwdPosDelta: parameter-require-com-spec{init-value=150, parameter=MdPosDelta/Val}, required-interface=MdPosDelta
      KeSMSuSecRwStHeadrestFwdBkwdPosTolr: parameter-require-com-spec{init-value=150, parameter=MdPosDelta/Val}, required-interface=MdPosDelta
      KeSMSuSecRwStHeadrestUpwdDwnwdPosDelta: parameter-require-com-spec{init-value=150, parameter=MdPosDelta/Val}, required-interface=MdPosDelta
      KeSMSuSecRwStHeadrestUpwdDwnwdPosTolr: parameter-require-com-spec{init-value=150, parameter=MdPosDelta/Val}, required-interface=MdPosDelta
      KeSMSuSecRwStLegrestInOutPosDelta: parameter-require-com-spec{init-value=150, parameter=MdPosDelta/Val}, required-interface=MdPosDelta
      KeSMSuSecRwStLegrestInOutPosTolr: parameter-require-com-spec{init-value=150, parameter=MdPosDelta/Val}, required-interface=MdPosDelta
      KeSMSuSecRwStLegrestUpwdDwnwdPosDelta: parameter-require-com-spec{init-value=150, parameter=MdPosDelta/Val}, required-interface=MdPosDelta
      KeSMSuSecRwStLegrestUpwdDwnwdPosTolr: parameter-require-com-spec{init-value=150, parameter=MdPosDelta/Val}, required-interface=MdPosDelta
      KeSMSuSecRwStLwdRwdPosDelta: parameter-require-com-spec{init-value=150, parameter=MdPosDelta/Val}, required-interface=MdPosDelta
      KeSMSuSecRwStLwdRwdPosTolr: parameter-require-com-spec{init-value=150, parameter=MdPosDelta/Val}, required-interface=MdPosDelta
      KeSMSuSecRwStVIPFtrstRefAngle: parameter-require-com-spec{init-value=110, parameter=KeSMSuSecRwStVIPFtrstRefAngle/Val}, required-interface=KeSMSuSecRwStVIPFtrstRefAngle
      KeSMSuThirdRwStFwdBkwdPosDelta: parameter-require-com-spec{init-value=150, parameter=MdPosDelta/Val}, required-interface=MdPosDelta
      KeSMSuThirdRwStFwdBkwdPosTolr: parameter-require-com-spec{init-value=150, parameter=MdPosDelta/Val}, required-interface=MdPosDelta
      KeSMSuThrdRwCushFoldPosDelta: parameter-require-com-spec{init-value=150, parameter=MdPosDelta/Val}, required-interface=MdPosDelta
      KeSMSuThrdRwCushFoldPosTolr: parameter-require-com-spec{init-value=150, parameter=MdPosDelta/Val}, required-interface=MdPosDelta
      KeSMSuThrdRwStBackPosDelta: parameter-require-com-spec{init-value=150, parameter=MdPosDelta/Val}, required-interface=MdPosDelta
      KeSMSuThrdRwStBackPosTolr: parameter-require-com-spec{init-value=150, parameter=MdPosDelta/Val}, required-interface=MdPosDelta
      KeSMSw4SAdpnHdrstUpwdDnwdPos1: parameter-require-com-spec{init-value=[0, 2136, 2528, 2924, 3276, 3592, 3876], parameter=AdpnHdrstUpwdDnwdPosTable/Val}, required-interface=AdpnHdrstUpwdDnwdPosTable
      KeSMSw4SAdpnHdrstUpwdDnwdPos2: parameter-require-com-spec{init-value=[0, 1744, 2136, 2528, 2924, 3276, 3592], parameter=AdpnHdrstUpwdDnwdPosTable/Val}, required-interface=AdpnHdrstUpwdDnwdPosTable
      KeSMSw4SAdpnHdrstUpwdDnwdPos3: parameter-require-com-spec{init-value=[0, 1524, 1744, 2136, 2528, 2924, 3276], parameter=AdpnHdrstUpwdDnwdPosTable/Val}, required-interface=AdpnHdrstUpwdDnwdPosTable
      KeSMSw4SAdpnHdrstUpwdDnwdPos4: parameter-require-com-spec{init-value=[0, 1232, 1524, 1744, 2136, 2528, 2924], parameter=AdpnHdrstUpwdDnwdPosTable/Val}, required-interface=AdpnHdrstUpwdDnwdPosTable
      KeSMSw4SAdpnHdrstUpwdDnwdPos5: parameter-require-com-spec{init-value=[0, 926, 1232, 1524, 1744, 2136, 2528], parameter=AdpnHdrstUpwdDnwdPosTable/Val}, required-interface=AdpnHdrstUpwdDnwdPosTable
      KeSMSw4SAdpnHdrstUpwdDnwdPos6: parameter-require-com-spec{init-value=[0, 648, 964, 1232, 1524, 1744, 2136], parameter=AdpnHdrstUpwdDnwdPosTable/Val}, required-interface=AdpnHdrstUpwdDnwdPosTable
      KeSMSw4SAdpnHdrstUpwdDnwdPos7: parameter-require-com-spec{init-value=[0, 80, 160, 240, 320, 400, 600], parameter=AdpnHdrstUpwdDnwdPosTable/Val}, required-interface=AdpnHdrstUpwdDnwdPosTable
      KeSMSw4SAdpnReclnUpwdDnwdPos: parameter-require-com-spec{init-value=[1360, 1640, 1916, 2196, 2472, 2752, 3280], parameter=AdpnReclnUpwdDnwdPosTable/Val}, required-interface=AdpnReclnUpwdDnwdPosTable
      KeSMSw4SLegrstCloseMdSecRwLtStFtrstUpwdDnwdPos: parameter-require-com-spec{init-value=0, parameter=Pos/Val}, required-interface=Pos
      KeSMSw4SLegrstCloseMdSecRwLtStFtrstUpwdDnwdPosMax: parameter-require-com-spec{init-value=0, parameter=Pos/Val}, required-interface=Pos
      KeSMSw4SLegrstCloseMdSecRwLtStFtrstUpwdDnwdPosMin: parameter-require-com-spec{init-value=0, parameter=Pos/Val}, required-interface=Pos
      KeSMSw4SLegrstCloseMdSecRwLtStLgrstOtwdInwdPos: parameter-require-com-spec{init-value=0, parameter=Pos/Val}, required-interface=Pos
      KeSMSw4SLegrstCloseMdSecRwLtStLgrstOtwdInwdPosMax: parameter-require-com-spec{init-value=0, parameter=Pos/Val}, required-interface=Pos
      KeSMSw4SLegrstCloseMdSecRwLtStLgrstOtwdInwdPosMin: parameter-require-com-spec{init-value=0, parameter=Pos/Val}, required-interface=Pos
      KeSMSw4SLegrstCloseMdSecRwLtStLgrstUpwdDnwdPos: parameter-require-com-spec{init-value=0, parameter=Pos/Val}, required-interface=Pos
      KeSMSw4SLegrstCloseMdSecRwLtStLgrstUpwdDnwdPosMax: parameter-require-com-spec{init-value=0, parameter=Pos/Val}, required-interface=Pos
      KeSMSw4SLegrstCloseMdSecRwLtStLgrstUpwdDnwdPosMin: parameter-require-com-spec{init-value=0, parameter=Pos/Val}, required-interface=Pos
      KeSMSw4SLegrstCloseMdSecRwRtStFtrstUpwdDnwdPos: parameter-require-com-spec{init-value=0, parameter=Pos/Val}, required-interface=Pos
      KeSMSw4SLegrstCloseMdSecRwRtStFtrstUpwdDnwdPosMax: parameter-require-com-spec{init-value=0, parameter=Pos/Val}, required-interface=Pos
      KeSMSw4SLegrstCloseMdSecRwRtStFtrstUpwdDnwdPosMin: parameter-require-com-spec{init-value=0, parameter=Pos/Val}, required-interface=Pos
      KeSMSw4SLegrstCloseMdSecRwRtStLgrstOtwdInwdPos: parameter-require-com-spec{init-value=0, parameter=Pos/Val}, required-interface=Pos
      KeSMSw4SLegrstCloseMdSecRwRtStLgrstOtwdInwdPosMax: parameter-require-com-spec{init-value=0, parameter=Pos/Val}, required-interface=Pos
      KeSMSw4SLegrstCloseMdSecRwRtStLgrstOtwdInwdPosMin: parameter-require-com-spec{init-value=0, parameter=Pos/Val}, required-interface=Pos
      KeSMSw4SLegrstCloseMdSecRwRtStLgrstUpwdDnwdPos: parameter-require-com-spec{init-value=0, parameter=Pos/Val}, required-interface=Pos
      KeSMSw4SLegrstCloseMdSecRwRtStLgrstUpwdDnwdPosMax: parameter-require-com-spec{init-value=0, parameter=Pos/Val}, required-interface=Pos
      KeSMSw4SLegrstCloseMdSecRwRtStLgrstUpwdDnwdPosMin: parameter-require-com-spec{init-value=0, parameter=Pos/Val}, required-interface=Pos
      KeSMSw4SLegrstOpenMdSecRwLtStFtrstUpwdDnwdPos: parameter-require-com-spec{init-value=0, parameter=Pos/Val}, required-interface=Pos
      KeSMSw4SLegrstOpenMdSecRwLtStFtrstUpwdDnwdPosMax: parameter-require-com-spec{init-value=0, parameter=Pos/Val}, required-interface=Pos
      KeSMSw4SLegrstOpenMdSecRwLtStFtrstUpwdDnwdPosMin: parameter-require-com-spec{init-value=0, parameter=Pos/Val}, required-interface=Pos
      KeSMSw4SLegrstOpenMdSecRwLtStLgrstOtwdInwdPos: parameter-require-com-spec{init-value=0, parameter=Pos/Val}, required-interface=Pos
      KeSMSw4SLegrstOpenMdSecRwLtStLgrstOtwdInwdPosMax: parameter-require-com-spec{init-value=0, parameter=Pos/Val}, required-interface=Pos
      KeSMSw4SLegrstOpenMdSecRwLtStLgrstOtwdInwdPosMin: parameter-require-com-spec{init-value=0, parameter=Pos/Val}, required-interface=Pos
      KeSMSw4SLegrstOpenMdSecRwLtStLgrstUpwdDnwdPos: parameter-require-com-spec{init-value=0, parameter=Pos/Val}, required-interface=Pos
      KeSMSw4SLegrstOpenMdSecRwLtStLgrstUpwdDnwdPosMax: parameter-require-com-spec{init-value=0, parameter=Pos/Val}, required-interface=Pos
      KeSMSw4SLegrstOpenMdSecRwLtStLgrstUpwdDnwdPosMin: parameter-require-com-spec{init-value=0, parameter=Pos/Val}, required-interface=Pos
      KeSMSw4SLegrstOpenMdSecRwRtStFtrstUpwdDnwdPos: parameter-require-com-spec{init-value=0, parameter=Pos/Val}, required-interface=Pos
      KeSMSw4SLegrstOpenMdSecRwRtStFtrstUpwdDnwdPosMax: parameter-require-com-spec{init-value=0, parameter=Pos/Val}, required-interface=Pos
      KeSMSw4SLegrstOpenMdSecRwRtStFtrstUpwdDnwdPosMin: parameter-require-com-spec{init-value=0, parameter=Pos/Val}, required-interface=Pos
      KeSMSw4SLegrstOpenMdSecRwRtStLgrstOtwdInwdPos: parameter-require-com-spec{init-value=0, parameter=Pos/Val}, required-interface=Pos
      KeSMSw4SLegrstOpenMdSecRwRtStLgrstOtwdInwdPosMax: parameter-require-com-spec{init-value=0, parameter=Pos/Val}, required-interface=Pos
      KeSMSw4SLegrstOpenMdSecRwRtStLgrstOtwdInwdPosMin: parameter-require-com-spec{init-value=0, parameter=Pos/Val}, required-interface=Pos
      KeSMSw4SLegrstOpenMdSecRwRtStLgrstUpwdDnwdPos: parameter-require-com-spec{init-value=0, parameter=Pos/Val}, required-interface=Pos
      KeSMSw4SLegrstOpenMdSecRwRtStLgrstUpwdDnwdPosMax: parameter-require-com-spec{init-value=0, parameter=Pos/Val}, required-interface=Pos
      KeSMSw4SLegrstOpenMdSecRwRtStLgrstUpwdDnwdPosMin: parameter-require-com-spec{init-value=0, parameter=Pos/Val}, required-interface=Pos
      KeSMSw4sLyingMDSecRwLtStBkReclnUpwdDnwdPos: parameter-require-com-spec{init-value=0, parameter=Pos/Val}, required-interface=Pos
      KeSMSw4sLyingMDSecRwLtStBkReclnUpwdDnwdPosMax: parameter-require-com-spec{init-value=0, parameter=Pos/Val}, required-interface=Pos
      KeSMSw4sLyingMDSecRwLtStBkReclnUpwdDnwdPosMin: parameter-require-com-spec{init-value=0, parameter=Pos/Val}, required-interface=Pos
      KeSMSw4sLyingMDSecRwLtStFtrstUpwdDnwdPos: parameter-require-com-spec{init-value=0, parameter=Pos/Val}, required-interface=Pos
      KeSMSw4sLyingMDSecRwLtStFtrstUpwdDnwdPosMax: parameter-require-com-spec{init-value=0, parameter=Pos/Val}, required-interface=Pos
      KeSMSw4sLyingMDSecRwLtStFtrstUpwdDnwdPosMin: parameter-require-com-spec{init-value=0, parameter=Pos/Val}, required-interface=Pos
      KeSMSw4sLyingMDSecRwLtStHdrstFrwdBkwdnwdPos: parameter-require-com-spec{init-value=0, parameter=Pos/Val}, required-interface=Pos
      KeSMSw4sLyingMDSecRwLtStHdrstFrwdBkwdnwdPos_160: parameter-require-com-spec{init-value=0, parameter=Pos/Val}, required-interface=Pos
      KeSMSw4sLyingMDSecRwLtStHdrstFrwdBkwdnwdPos_165: parameter-require-com-spec{init-value=0, parameter=Pos/Val}, required-interface=Pos
      KeSMSw4sLyingMDSecRwLtStHdrstFrwdBkwdnwdPos_170: parameter-require-com-spec{init-value=0, parameter=Pos/Val}, required-interface=Pos
      KeSMSw4sLyingMDSecRwLtStHdrstFrwdBkwdnwdPos_175: parameter-require-com-spec{init-value=0, parameter=Pos/Val}, required-interface=Pos
      KeSMSw4sLyingMDSecRwLtStHdrstFrwdBkwdnwdPos_180: parameter-require-com-spec{init-value=0, parameter=Pos/Val}, required-interface=Pos
      KeSMSw4sLyingMDSecRwLtStHdrstFrwdBkwdnwdPos_Below160: parameter-require-com-spec{init-value=0, parameter=Pos/Val}, required-interface=Pos
      KeSMSw4sLyingMDSecRwLtStHdrstFrwdBkwdnwdPos_Over180: parameter-require-com-spec{init-value=0, parameter=Pos/Val}, required-interface=Pos
      KeSMSw4sLyingMDSecRwLtStHdrstFrwdBkwdnwdPosMax: parameter-require-com-spec{init-value=0, parameter=Pos/Val}, required-interface=Pos
      KeSMSw4sLyingMDSecRwLtStHdrstFrwdBkwdnwdPosMax_160: parameter-require-com-spec{init-value=0, parameter=Pos/Val}, required-interface=Pos
      KeSMSw4sLyingMDSecRwLtStHdrstFrwdBkwdnwdPosMax_165: parameter-require-com-spec{init-value=0, parameter=Pos/Val}, required-interface=Pos
      KeSMSw4sLyingMDSecRwLtStHdrstFrwdBkwdnwdPosMax_170: parameter-require-com-spec{init-value=0, parameter=Pos/Val}, required-interface=Pos
      KeSMSw4sLyingMDSecRwLtStHdrstFrwdBkwdnwdPosMax_175: parameter-require-com-spec{init-value=0, parameter=Pos/Val}, required-interface=Pos
      KeSMSw4sLyingMDSecRwLtStHdrstFrwdBkwdnwdPosMax_180: parameter-require-com-spec{init-value=0, parameter=Pos/Val}, required-interface=Pos
      KeSMSw4sLyingMDSecRwLtStHdrstFrwdBkwdnwdPosMax_Below160: parameter-require-com-spec{init-value=0, parameter=Pos/Val}, required-interface=Pos
      KeSMSw4sLyingMDSecRwLtStHdrstFrwdBkwdnwdPosMax_Over180: parameter-require-com-spec{init-value=0, parameter=Pos/Val}, required-interface=Pos
      KeSMSw4sLyingMDSecRwLtStHdrstFrwdBkwdnwdPosMin: parameter-require-com-spec{init-value=0, parameter=Pos/Val}, required-interface=Pos
      KeSMSw4sLyingMDSecRwLtStHdrstFrwdBkwdnwdPosMin_160: parameter-require-com-spec{init-value=0, parameter=Pos/Val}, required-interface=Pos
      KeSMSw4sLyingMDSecRwLtStHdrstFrwdBkwdnwdPosMin_165: parameter-require-com-spec{init-value=0, parameter=Pos/Val}, required-interface=Pos
      KeSMSw4sLyingMDSecRwLtStHdrstFrwdBkwdnwdPosMin_170: parameter-require-com-spec{init-value=0, parameter=Pos/Val}, required-interface=Pos
      KeSMSw4sLyingMDSecRwLtStHdrstFrwdBkwdnwdPosMin_175: parameter-require-com-spec{init-value=0, parameter=Pos/Val}, required-interface=Pos
      KeSMSw4sLyingMDSecRwLtStHdrstFrwdBkwdnwdPosMin_180: parameter-require-com-spec{init-value=0, parameter=Pos/Val}, required-interface=Pos
      KeSMSw4sLyingMDSecRwLtStHdrstFrwdBkwdnwdPosMin_Below160: parameter-require-com-spec{init-value=0, parameter=Pos/Val}, required-interface=Pos
      KeSMSw4sLyingMDSecRwLtStHdrstFrwdBkwdnwdPosMin_Over180: parameter-require-com-spec{init-value=0, parameter=Pos/Val}, required-interface=Pos
      KeSMSw4sLyingMDSecRwLtStHdrstUpwdDnwdPos: parameter-require-com-spec{init-value=0, parameter=Pos/Val}, required-interface=Pos
      KeSMSw4sLyingMDSecRwLtStHdrstUpwdDnwdPos_160: parameter-require-com-spec{init-value=0, parameter=Pos/Val}, required-interface=Pos
      KeSMSw4sLyingMDSecRwLtStHdrstUpwdDnwdPos_165: parameter-require-com-spec{init-value=0, parameter=Pos/Val}, required-interface=Pos
      KeSMSw4sLyingMDSecRwLtStHdrstUpwdDnwdPos_170: parameter-require-com-spec{init-value=0, parameter=Pos/Val}, required-interface=Pos
      KeSMSw4sLyingMDSecRwLtStHdrstUpwdDnwdPos_175: parameter-require-com-spec{init-value=0, parameter=Pos/Val}, required-interface=Pos
      KeSMSw4sLyingMDSecRwLtStHdrstUpwdDnwdPos_180: parameter-require-com-spec{init-value=0, parameter=Pos/Val}, required-interface=Pos
      KeSMSw4sLyingMDSecRwLtStHdrstUpwdDnwdPos_Below160: parameter-require-com-spec{init-value=0, parameter=Pos/Val}, required-interface=Pos
      KeSMSw4sLyingMDSecRwLtStHdrstUpwdDnwdPos_Over180: parameter-require-com-spec{init-value=0, parameter=Pos/Val}, required-interface=Pos
      KeSMSw4sLyingMDSecRwLtStHdrstUpwdDnwdPosMax: parameter-require-com-spec{init-value=0, parameter=Pos/Val}, required-interface=Pos
      KeSMSw4sLyingMDSecRwLtStHdrstUpwdDnwdPosMax_160: parameter-require-com-spec{init-value=0, parameter=Pos/Val}, required-interface=Pos
      KeSMSw4sLyingMDSecRwLtStHdrstUpwdDnwdPosMax_165: parameter-require-com-spec{init-value=0, parameter=Pos/Val}, required-interface=Pos
      KeSMSw4sLyingMDSecRwLtStHdrstUpwdDnwdPosMax_170: parameter-require-com-spec{init-value=0, parameter=Pos/Val}, required-interface=Pos
      KeSMSw4sLyingMDSecRwLtStHdrstUpwdDnwdPosMax_175: parameter-require-com-spec{init-value=0, parameter=Pos/Val}, required-interface=Pos
      KeSMSw4sLyingMDSecRwLtStHdrstUpwdDnwdPosMax_180: parameter-require-com-spec{init-value=0, parameter=Pos/Val}, required-interface=Pos
      KeSMSw4sLyingMDSecRwLtStHdrstUpwdDnwdPosMax_Below160: parameter-require-com-spec{init-value=0, parameter=Pos/Val}, required-interface=Pos
      KeSMSw4sLyingMDSecRwLtStHdrstUpwdDnwdPosMax_Over180: parameter-require-com-spec{init-value=0, parameter=Pos/Val}, required-interface=Pos
      KeSMSw4sLyingMDSecRwLtStHdrstUpwdDnwdPosMin: parameter-require-com-spec{init-value=0, parameter=Pos/Val}, required-interface=Pos
      KeSMSw4sLyingMDSecRwLtStHdrstUpwdDnwdPosMin_160: parameter-require-com-spec{init-value=0, parameter=Pos/Val}, required-interface=Pos
      KeSMSw4sLyingMDSecRwLtStHdrstUpwdDnwdPosMin_165: parameter-require-com-spec{init-value=0, parameter=Pos/Val}, required-interface=Pos
      KeSMSw4sLyingMDSecRwLtStHdrstUpwdDnwdPosMin_170: parameter-require-com-spec{init-value=0, parameter=Pos/Val}, required-interface=Pos
      KeSMSw4sLyingMDSecRwLtStHdrstUpwdDnwdPosMin_175: parameter-require-com-spec{init-value=0, parameter=Pos/Val}, required-interface=Pos
      KeSMSw4sLyingMDSecRwLtStHdrstUpwdDnwdPosMin_180: parameter-require-com-spec{init-value=0, parameter=Pos/Val}, required-interface=Pos
      KeSMSw4sLyingMDSecRwLtStHdrstUpwdDnwdPosMin_Below160: parameter-require-com-spec{init-value=0, parameter=Pos/Val}, required-interface=Pos
      KeSMSw4sLyingMDSecRwLtStHdrstUpwdDnwdPosMin_Over180: parameter-require-com-spec{init-value=0, parameter=Pos/Val}, required-interface=Pos
      KeSMSw4sLyingMDSecRwLtStLgrstOtwdInwdPos: parameter-require-com-spec{init-value=0, parameter=Pos/Val}, required-interface=Pos
      KeSMSw4sLyingMDSecRwLtStLgrstOtwdInwdPos_160: parameter-require-com-spec{init-value=0, parameter=Pos/Val}, required-interface=Pos
      KeSMSw4sLyingMDSecRwLtStLgrstOtwdInwdPos_165: parameter-require-com-spec{init-value=0, parameter=Pos/Val}, required-interface=Pos
      KeSMSw4sLyingMDSecRwLtStLgrstOtwdInwdPos_170: parameter-require-com-spec{init-value=0, parameter=Pos/Val}, required-interface=Pos
      KeSMSw4sLyingMDSecRwLtStLgrstOtwdInwdPos_175: parameter-require-com-spec{init-value=0, parameter=Pos/Val}, required-interface=Pos
      KeSMSw4sLyingMDSecRwLtStLgrstOtwdInwdPos_180: parameter-require-com-spec{init-value=0, parameter=Pos/Val}, required-interface=Pos
      KeSMSw4sLyingMDSecRwLtStLgrstOtwdInwdPos_Below160: parameter-require-com-spec{init-value=0, parameter=Pos/Val}, required-interface=Pos
      KeSMSw4sLyingMDSecRwLtStLgrstOtwdInwdPos_Over180: parameter-require-com-spec{init-value=0, parameter=Pos/Val}, required-interface=Pos
      KeSMSw4sLyingMDSecRwLtStLgrstOtwdInwdPosMax: parameter-require-com-spec{init-value=0, parameter=Pos/Val}, required-interface=Pos
      KeSMSw4sLyingMDSecRwLtStLgrstOtwdInwdPosMax_160: parameter-require-com-spec{init-value=0, parameter=Pos/Val}, required-interface=Pos
      KeSMSw4sLyingMDSecRwLtStLgrstOtwdInwdPosMax_165: parameter-require-com-spec{init-value=0, parameter=Pos/Val}, required-interface=Pos
      KeSMSw4sLyingMDSecRwLtStLgrstOtwdInwdPosMax_170: parameter-require-com-spec{init-value=0, parameter=Pos/Val}, required-interface=Pos
      KeSMSw4sLyingMDSecRwLtStLgrstOtwdInwdPosMax_175: parameter-require-com-spec{init-value=0, parameter=Pos/Val}, required-interface=Pos
      KeSMSw4sLyingMDSecRwLtStLgrstOtwdInwdPosMax_180: parameter-require-com-spec{init-value=0, parameter=Pos/Val}, required-interface=Pos
      KeSMSw4sLyingMDSecRwLtStLgrstOtwdInwdPosMax_Below160: parameter-require-com-spec{init-value=0, parameter=Pos/Val}, required-interface=Pos
      KeSMSw4sLyingMDSecRwLtStLgrstOtwdInwdPosMax_Over180: parameter-require-com-spec{init-value=0, parameter=Pos/Val}, required-interface=Pos
      KeSMSw4sLyingMDSecRwLtStLgrstOtwdInwdPosMin: parameter-require-com-spec{init-value=0, parameter=Pos/Val}, required-interface=Pos
      KeSMSw4sLyingMDSecRwLtStLgrstOtwdInwdPosMin_160: parameter-require-com-spec{init-value=0, parameter=Pos/Val}, required-interface=Pos
      KeSMSw4sLyingMDSecRwLtStLgrstOtwdInwdPosMin_165: parameter-require-com-spec{init-value=0, parameter=Pos/Val}, required-interface=Pos
      KeSMSw4sLyingMDSecRwLtStLgrstOtwdInwdPosMin_170: parameter-require-com-spec{init-value=0, parameter=Pos/Val}, required-interface=Pos
      KeSMSw4sLyingMDSecRwLtStLgrstOtwdInwdPosMin_175: parameter-require-com-spec{init-value=0, parameter=Pos/Val}, required-interface=Pos
      KeSMSw4sLyingMDSecRwLtStLgrstOtwdInwdPosMin_180: parameter-require-com-spec{init-value=0, parameter=Pos/Val}, required-interface=Pos
      KeSMSw4sLyingMDSecRwLtStLgrstOtwdInwdPosMin_Below160: parameter-require-com-spec{init-value=0, parameter=Pos/Val}, required-interface=Pos
      KeSMSw4sLyingMDSecRwLtStLgrstOtwdInwdPosMin_Over180: parameter-require-com-spec{init-value=0, parameter=Pos/Val}, required-interface=Pos
      KeSMSw4sLyingMDSecRwLtStLgrstUpwdDnwdPos: parameter-require-com-spec{init-value=0, parameter=Pos/Val}, required-interface=Pos
      KeSMSw4sLyingMDSecRwLtStLgrstUpwdDnwdPosMax: parameter-require-com-spec{init-value=0, parameter=Pos/Val}, required-interface=Pos
      KeSMSw4sLyingMDSecRwLtStLgrstUpwdDnwdPosMin: parameter-require-com-spec{init-value=0, parameter=Pos/Val}, required-interface=Pos
      KeSMSw4sLyingMDSecRwRtStBkReclnUpwdDnwdPos: parameter-require-com-spec{init-value=0, parameter=Pos/Val}, required-interface=Pos
      KeSMSw4sLyingMDSecRwRtStBkReclnUpwdDnwdPosMax: parameter-require-com-spec{init-value=0, parameter=Pos/Val}, required-interface=Pos
      KeSMSw4sLyingMDSecRwRtStBkReclnUpwdDnwdPosMin: parameter-require-com-spec{init-value=0, parameter=Pos/Val}, required-interface=Pos
      KeSMSw4sLyingMDSecRwRtStFtrstUpwdDnwdPos: parameter-require-com-spec{init-value=0, parameter=Pos/Val}, required-interface=Pos
      KeSMSw4sLyingMDSecRwRtStFtrstUpwdDnwdPosMax: parameter-require-com-spec{init-value=0, parameter=Pos/Val}, required-interface=Pos
      KeSMSw4sLyingMDSecRwRtStFtrstUpwdDnwdPosMin: parameter-require-com-spec{init-value=0, parameter=Pos/Val}, required-interface=Pos
      KeSMSw4sLyingMDSecRwRtStHdrstFrwdBkwdnwdPos: parameter-require-com-spec{init-value=0, parameter=Pos/Val}, required-interface=Pos
      KeSMSw4sLyingMDSecRwRtStHdrstFrwdBkwdnwdPos_160: parameter-require-com-spec{init-value=0, parameter=Pos/Val}, required-interface=Pos
      KeSMSw4sLyingMDSecRwRtStHdrstFrwdBkwdnwdPos_165: parameter-require-com-spec{init-value=0, parameter=Pos/Val}, required-interface=Pos
      KeSMSw4sLyingMDSecRwRtStHdrstFrwdBkwdnwdPos_170: parameter-require-com-spec{init-value=0, parameter=Pos/Val}, required-interface=Pos
      KeSMSw4sLyingMDSecRwRtStHdrstFrwdBkwdnwdPos_175: parameter-require-com-spec{init-value=0, parameter=Pos/Val}, required-interface=Pos
      KeSMSw4sLyingMDSecRwRtStHdrstFrwdBkwdnwdPos_180: parameter-require-com-spec{init-value=0, parameter=Pos/Val}, required-interface=Pos
      KeSMSw4sLyingMDSecRwRtStHdrstFrwdBkwdnwdPos_Below160: parameter-require-com-spec{init-value=0, parameter=Pos/Val}, required-interface=Pos
      KeSMSw4sLyingMDSecRwRtStHdrstFrwdBkwdnwdPos_Over180: parameter-require-com-spec{init-value=0, parameter=Pos/Val}, required-interface=Pos
      KeSMSw4sLyingMDSecRwRtStHdrstFrwdBkwdnwdPosMax: parameter-require-com-spec{init-value=0, parameter=Pos/Val}, required-interface=Pos
      KeSMSw4sLyingMDSecRwRtStHdrstFrwdBkwdnwdPosMax_160: parameter-require-com-spec{init-value=0, parameter=Pos/Val}, required-interface=Pos
      KeSMSw4sLyingMDSecRwRtStHdrstFrwdBkwdnwdPosMax_165: parameter-require-com-spec{init-value=0, parameter=Pos/Val}, required-interface=Pos
      KeSMSw4sLyingMDSecRwRtStHdrstFrwdBkwdnwdPosMax_170: parameter-require-com-spec{init-value=0, parameter=Pos/Val}, required-interface=Pos
      KeSMSw4sLyingMDSecRwRtStHdrstFrwdBkwdnwdPosMax_175: parameter-require-com-spec{init-value=0, parameter=Pos/Val}, required-interface=Pos
      KeSMSw4sLyingMDSecRwRtStHdrstFrwdBkwdnwdPosMax_180: parameter-require-com-spec{init-value=0, parameter=Pos/Val}, required-interface=Pos
      KeSMSw4sLyingMDSecRwRtStHdrstFrwdBkwdnwdPosMax_Below160: parameter-require-com-spec{init-value=0, parameter=Pos/Val}, required-interface=Pos
      KeSMSw4sLyingMDSecRwRtStHdrstFrwdBkwdnwdPosMax_Over180: parameter-require-com-spec{init-value=0, parameter=Pos/Val}, required-interface=Pos
      KeSMSw4sLyingMDSecRwRtStHdrstFrwdBkwdnwdPosMin: parameter-require-com-spec{init-value=0, parameter=Pos/Val}, required-interface=Pos
      KeSMSw4sLyingMDSecRwRtStHdrstFrwdBkwdnwdPosMin_160: parameter-require-com-spec{init-value=0, parameter=Pos/Val}, required-interface=Pos
      KeSMSw4sLyingMDSecRwRtStHdrstFrwdBkwdnwdPosMin_165: parameter-require-com-spec{init-value=0, parameter=Pos/Val}, required-interface=Pos
      KeSMSw4sLyingMDSecRwRtStHdrstFrwdBkwdnwdPosMin_170: parameter-require-com-spec{init-value=0, parameter=Pos/Val}, required-interface=Pos
      KeSMSw4sLyingMDSecRwRtStHdrstFrwdBkwdnwdPosMin_175: parameter-require-com-spec{init-value=0, parameter=Pos/Val}, required-interface=Pos
      KeSMSw4sLyingMDSecRwRtStHdrstFrwdBkwdnwdPosMin_180: parameter-require-com-spec{init-value=0, parameter=Pos/Val}, required-interface=Pos
      KeSMSw4sLyingMDSecRwRtStHdrstFrwdBkwdnwdPosMin_Below160: parameter-require-com-spec{init-value=0, parameter=Pos/Val}, required-interface=Pos
      KeSMSw4sLyingMDSecRwRtStHdrstFrwdBkwdnwdPosMin_Over180: parameter-require-com-spec{init-value=0, parameter=Pos/Val}, required-interface=Pos
      KeSMSw4sLyingMDSecRwRtStHdrstUpwdPos: parameter-require-com-spec{init-value=0, parameter=Pos/Val}, required-interface=Pos
      KeSMSw4sLyingMDSecRwRtStHdrstUpwdPos_160: parameter-require-com-spec{init-value=0, parameter=Pos/Val}, required-interface=Pos
      KeSMSw4sLyingMDSecRwRtStHdrstUpwdPos_165: parameter-require-com-spec{init-value=0, parameter=Pos/Val}, required-interface=Pos
      KeSMSw4sLyingMDSecRwRtStHdrstUpwdPos_170: parameter-require-com-spec{init-value=0, parameter=Pos/Val}, required-interface=Pos
      KeSMSw4sLyingMDSecRwRtStHdrstUpwdPos_175: parameter-require-com-spec{init-value=0, parameter=Pos/Val}, required-interface=Pos
      KeSMSw4sLyingMDSecRwRtStHdrstUpwdPos_180: parameter-require-com-spec{init-value=0, parameter=Pos/Val}, required-interface=Pos
      KeSMSw4sLyingMDSecRwRtStHdrstUpwdPos_Below160: parameter-require-com-spec{init-value=0, parameter=Pos/Val}, required-interface=Pos
      KeSMSw4sLyingMDSecRwRtStHdrstUpwdPos_Over180: parameter-require-com-spec{init-value=0, parameter=Pos/Val}, required-interface=Pos
      KeSMSw4sLyingMDSecRwRtStHdrstUpwdPosMax: parameter-require-com-spec{init-value=0, parameter=Pos/Val}, required-interface=Pos
      KeSMSw4sLyingMDSecRwRtStHdrstUpwdPosMax_160: parameter-require-com-spec{init-value=0, parameter=Pos/Val}, required-interface=Pos
      KeSMSw4sLyingMDSecRwRtStHdrstUpwdPosMax_165: parameter-require-com-spec{init-value=0, parameter=Pos/Val}, required-interface=Pos
      KeSMSw4sLyingMDSecRwRtStHdrstUpwdPosMax_170: parameter-require-com-spec{init-value=0, parameter=Pos/Val}, required-interface=Pos
      KeSMSw4sLyingMDSecRwRtStHdrstUpwdPosMax_175: parameter-require-com-spec{init-value=0, parameter=Pos/Val}, required-interface=Pos
      KeSMSw4sLyingMDSecRwRtStHdrstUpwdPosMax_180: parameter-require-com-spec{init-value=0, parameter=Pos/Val}, required-interface=Pos
      KeSMSw4sLyingMDSecRwRtStHdrstUpwdPosMax_Below160: parameter-require-com-spec{init-value=0, parameter=Pos/Val}, required-interface=Pos
      KeSMSw4sLyingMDSecRwRtStHdrstUpwdPosMax_Over180: parameter-require-com-spec{init-value=0, parameter=Pos/Val}, required-interface=Pos
      KeSMSw4sLyingMDSecRwRtStHdrstUpwdPosMin: parameter-require-com-spec{init-value=0, parameter=Pos/Val}, required-interface=Pos
      KeSMSw4sLyingMDSecRwRtStHdrstUpwdPosMin_160: parameter-require-com-spec{init-value=0, parameter=Pos/Val}, required-interface=Pos
      KeSMSw4sLyingMDSecRwRtStHdrstUpwdPosMin_165: parameter-require-com-spec{init-value=0, parameter=Pos/Val}, required-interface=Pos
      KeSMSw4sLyingMDSecRwRtStHdrstUpwdPosMin_170: parameter-require-com-spec{init-value=0, parameter=Pos/Val}, required-interface=Pos
      KeSMSw4sLyingMDSecRwRtStHdrstUpwdPosMin_175: parameter-require-com-spec{init-value=0, parameter=Pos/Val}, required-interface=Pos
      KeSMSw4sLyingMDSecRwRtStHdrstUpwdPosMin_180: parameter-require-com-spec{init-value=0, parameter=Pos/Val}, required-interface=Pos
      KeSMSw4sLyingMDSecRwRtStHdrstUpwdPosMin_Below160: parameter-require-com-spec{init-value=0, parameter=Pos/Val}, required-interface=Pos
      KeSMSw4sLyingMDSecRwRtStHdrstUpwdPosMin_Over180: parameter-require-com-spec{init-value=0, parameter=Pos/Val}, required-interface=Pos
      KeSMSw4sLyingMDSecRwRtStLgrstOtwdInwdPos: parameter-require-com-spec{init-value=0, parameter=Pos/Val}, required-interface=Pos
      KeSMSw4sLyingMDSecRwRtStLgrstOtwdInwdPos_160: parameter-require-com-spec{init-value=0, parameter=Pos/Val}, required-interface=Pos
      KeSMSw4sLyingMDSecRwRtStLgrstOtwdInwdPos_165: parameter-require-com-spec{init-value=0, parameter=Pos/Val}, required-interface=Pos
      KeSMSw4sLyingMDSecRwRtStLgrstOtwdInwdPos_170: parameter-require-com-spec{init-value=0, parameter=Pos/Val}, required-interface=Pos
      KeSMSw4sLyingMDSecRwRtStLgrstOtwdInwdPos_175: parameter-require-com-spec{init-value=0, parameter=Pos/Val}, required-interface=Pos
      KeSMSw4sLyingMDSecRwRtStLgrstOtwdInwdPos_180: parameter-require-com-spec{init-value=0, parameter=Pos/Val}, required-interface=Pos
      KeSMSw4sLyingMDSecRwRtStLgrstOtwdInwdPos_Below160: parameter-require-com-spec{init-value=0, parameter=Pos/Val}, required-interface=Pos
      KeSMSw4sLyingMDSecRwRtStLgrstOtwdInwdPos_Over180: parameter-require-com-spec{init-value=0, parameter=Pos/Val}, required-interface=Pos
      KeSMSw4sLyingMDSecRwRtStLgrstOtwdInwdPosMax: parameter-require-com-spec{init-value=0, parameter=Pos/Val}, required-interface=Pos
      KeSMSw4sLyingMDSecRwRtStLgrstOtwdInwdPosMax_160: parameter-require-com-spec{init-value=0, parameter=Pos/Val}, required-interface=Pos
      KeSMSw4sLyingMDSecRwRtStLgrstOtwdInwdPosMax_165: parameter-require-com-spec{init-value=0, parameter=Pos/Val}, required-interface=Pos
      KeSMSw4sLyingMDSecRwRtStLgrstOtwdInwdPosMax_170: parameter-require-com-spec{init-value=0, parameter=Pos/Val}, required-interface=Pos
      KeSMSw4sLyingMDSecRwRtStLgrstOtwdInwdPosMax_175: parameter-require-com-spec{init-value=0, parameter=Pos/Val}, required-interface=Pos
      KeSMSw4sLyingMDSecRwRtStLgrstOtwdInwdPosMax_180: parameter-require-com-spec{init-value=0, parameter=Pos/Val}, required-interface=Pos
      KeSMSw4sLyingMDSecRwRtStLgrstOtwdInwdPosMax_Below160: parameter-require-com-spec{init-value=0, parameter=Pos/Val}, required-interface=Pos
      KeSMSw4sLyingMDSecRwRtStLgrstOtwdInwdPosMax_Over180: parameter-require-com-spec{init-value=0, parameter=Pos/Val}, required-interface=Pos
      KeSMSw4sLyingMDSecRwRtStLgrstOtwdInwdPosMin: parameter-require-com-spec{init-value=0, parameter=Pos/Val}, required-interface=Pos
      KeSMSw4sLyingMDSecRwRtStLgrstOtwdInwdPosMin_160: parameter-require-com-spec{init-value=0, parameter=Pos/Val}, required-interface=Pos
      KeSMSw4sLyingMDSecRwRtStLgrstOtwdInwdPosMin_165: parameter-require-com-spec{init-value=0, parameter=Pos/Val}, required-interface=Pos
      KeSMSw4sLyingMDSecRwRtStLgrstOtwdInwdPosMin_170: parameter-require-com-spec{init-value=0, parameter=Pos/Val}, required-interface=Pos
      KeSMSw4sLyingMDSecRwRtStLgrstOtwdInwdPosMin_175: parameter-require-com-spec{init-value=0, parameter=Pos/Val}, required-interface=Pos
      KeSMSw4sLyingMDSecRwRtStLgrstOtwdInwdPosMin_180: parameter-require-com-spec{init-value=0, parameter=Pos/Val}, required-interface=Pos
      KeSMSw4sLyingMDSecRwRtStLgrstOtwdInwdPosMin_Below160: parameter-require-com-spec{init-value=0, parameter=Pos/Val}, required-interface=Pos
      KeSMSw4sLyingMDSecRwRtStLgrstOtwdInwdPosMin_Over180: parameter-require-com-spec{init-value=0, parameter=Pos/Val}, required-interface=Pos
      KeSMSw4sLyingMDSecRwRtStLgrstUpwdPos: parameter-require-com-spec{init-value=0, parameter=Pos/Val}, required-interface=Pos
      KeSMSw4sLyingMDSecRwRtStLgrstUpwdPosMax: parameter-require-com-spec{init-value=0, parameter=Pos/Val}, required-interface=Pos
      KeSMSw4sLyingMDSecRwRtStLgrstUpwdPosMin: parameter-require-com-spec{init-value=0, parameter=Pos/Val}, required-interface=Pos
      KeSMSw4sRecoveryMDSecRwLtStBkReclnUpwdDnwdPos: parameter-require-com-spec{init-value=0, parameter=Pos/Val}, required-interface=Pos
      KeSMSw4sRecoveryMDSecRwLtStBkReclnUpwdDnwdPosMax: parameter-require-com-spec{init-value=0, parameter=Pos/Val}, required-interface=Pos
      KeSMSw4sRecoveryMDSecRwLtStBkReclnUpwdDnwdPosMin: parameter-require-com-spec{init-value=0, parameter=Pos/Val}, required-interface=Pos
      KeSMSw4sRecoveryMDSecRwLtStFtrstUpwdDnwdPos: parameter-require-com-spec{init-value=0, parameter=Pos/Val}, required-interface=Pos
      KeSMSw4sRecoveryMDSecRwLtStFtrstUpwdDnwdPosMax: parameter-require-com-spec{init-value=0, parameter=Pos/Val}, required-interface=Pos
      KeSMSw4sRecoveryMDSecRwLtStFtrstUpwdDnwdPosMin: parameter-require-com-spec{init-value=0, parameter=Pos/Val}, required-interface=Pos
      KeSMSw4sRecoveryMDSecRwLtStHdrstFrwdBkwdPos: parameter-require-com-spec{init-value=0, parameter=Pos/Val}, required-interface=Pos
      KeSMSw4sRecoveryMDSecRwLtStHdrstFrwdBkwdPos_160: parameter-require-com-spec{init-value=0, parameter=Pos/Val}, required-interface=Pos
      KeSMSw4sRecoveryMDSecRwLtStHdrstFrwdBkwdPos_165: parameter-require-com-spec{init-value=0, parameter=Pos/Val}, required-interface=Pos
      KeSMSw4sRecoveryMDSecRwLtStHdrstFrwdBkwdPos_170: parameter-require-com-spec{init-value=0, parameter=Pos/Val}, required-interface=Pos
      KeSMSw4sRecoveryMDSecRwLtStHdrstFrwdBkwdPos_175: parameter-require-com-spec{init-value=0, parameter=Pos/Val}, required-interface=Pos
      KeSMSw4sRecoveryMDSecRwLtStHdrstFrwdBkwdPos_180: parameter-require-com-spec{init-value=0, parameter=Pos/Val}, required-interface=Pos
      KeSMSw4sRecoveryMDSecRwLtStHdrstFrwdBkwdPos_Below160: parameter-require-com-spec{init-value=0, parameter=Pos/Val}, required-interface=Pos
      KeSMSw4sRecoveryMDSecRwLtStHdrstFrwdBkwdPos_Over180: parameter-require-com-spec{init-value=0, parameter=Pos/Val}, required-interface=Pos
      KeSMSw4sRecoveryMDSecRwLtStHdrstFrwdBkwdPosMax: parameter-require-com-spec{init-value=0, parameter=Pos/Val}, required-interface=Pos
      KeSMSw4sRecoveryMDSecRwLtStHdrstFrwdBkwdPosMax_160: parameter-require-com-spec{init-value=0, parameter=Pos/Val}, required-interface=Pos
      KeSMSw4sRecoveryMDSecRwLtStHdrstFrwdBkwdPosMax_165: parameter-require-com-spec{init-value=0, parameter=Pos/Val}, required-interface=Pos
      KeSMSw4sRecoveryMDSecRwLtStHdrstFrwdBkwdPosMax_170: parameter-require-com-spec{init-value=0, parameter=Pos/Val}, required-interface=Pos
      KeSMSw4sRecoveryMDSecRwLtStHdrstFrwdBkwdPosMax_175: parameter-require-com-spec{init-value=0, parameter=Pos/Val}, required-interface=Pos
      KeSMSw4sRecoveryMDSecRwLtStHdrstFrwdBkwdPosMax_180: parameter-require-com-spec{init-value=0, parameter=Pos/Val}, required-interface=Pos
      KeSMSw4sRecoveryMDSecRwLtStHdrstFrwdBkwdPosMax_Below160: parameter-require-com-spec{init-value=0, parameter=Pos/Val}, required-interface=Pos
      KeSMSw4sRecoveryMDSecRwLtStHdrstFrwdBkwdPosMax_Over180: parameter-require-com-spec{init-value=0, parameter=Pos/Val}, required-interface=Pos
      KeSMSw4sRecoveryMDSecRwLtStHdrstFrwdBkwdPosMin: parameter-require-com-spec{init-value=0, parameter=Pos/Val}, required-interface=Pos
      KeSMSw4sRecoveryMDSecRwLtStHdrstFrwdBkwdPosMin_160: parameter-require-com-spec{init-value=0, parameter=Pos/Val}, required-interface=Pos
      KeSMSw4sRecoveryMDSecRwLtStHdrstFrwdBkwdPosMin_165: parameter-require-com-spec{init-value=0, parameter=Pos/Val}, required-interface=Pos
      KeSMSw4sRecoveryMDSecRwLtStHdrstFrwdBkwdPosMin_170: parameter-require-com-spec{init-value=0, parameter=Pos/Val}, required-interface=Pos
      KeSMSw4sRecoveryMDSecRwLtStHdrstFrwdBkwdPosMin_175: parameter-require-com-spec{init-value=0, parameter=Pos/Val}, required-interface=Pos
      KeSMSw4sRecoveryMDSecRwLtStHdrstFrwdBkwdPosMin_180: parameter-require-com-spec{init-value=0, parameter=Pos/Val}, required-interface=Pos
      KeSMSw4sRecoveryMDSecRwLtStHdrstFrwdBkwdPosMin_Below160: parameter-require-com-spec{init-value=0, parameter=Pos/Val}, required-interface=Pos
      KeSMSw4sRecoveryMDSecRwLtStHdrstFrwdBkwdPosMin_Over180: parameter-require-com-spec{init-value=0, parameter=Pos/Val}, required-interface=Pos
      KeSMSw4sRecoveryMDSecRwLtStHdrstUpwdDnwdPos: parameter-require-com-spec{init-value=0, parameter=Pos/Val}, required-interface=Pos
      KeSMSw4sRecoveryMDSecRwLtStHdrstUpwdDnwdPos_160: parameter-require-com-spec{init-value=0, parameter=Pos/Val}, required-interface=Pos
      KeSMSw4sRecoveryMDSecRwLtStHdrstUpwdDnwdPos_165: parameter-require-com-spec{init-value=0, parameter=Pos/Val}, required-interface=Pos
      KeSMSw4sRecoveryMDSecRwLtStHdrstUpwdDnwdPos_170: parameter-require-com-spec{init-value=0, parameter=Pos/Val}, required-interface=Pos
      KeSMSw4sRecoveryMDSecRwLtStHdrstUpwdDnwdPos_175: parameter-require-com-spec{init-value=0, parameter=Pos/Val}, required-interface=Pos
      KeSMSw4sRecoveryMDSecRwLtStHdrstUpwdDnwdPos_180: parameter-require-com-spec{init-value=0, parameter=Pos/Val}, required-interface=Pos
      KeSMSw4sRecoveryMDSecRwLtStHdrstUpwdDnwdPos_Below160: parameter-require-com-spec{init-value=0, parameter=Pos/Val}, required-interface=Pos
      KeSMSw4sRecoveryMDSecRwLtStHdrstUpwdDnwdPos_Over180: parameter-require-com-spec{init-value=0, parameter=Pos/Val}, required-interface=Pos
      KeSMSw4sRecoveryMDSecRwLtStHdrstUpwdDnwdPosMax: parameter-require-com-spec{init-value=0, parameter=Pos/Val}, required-interface=Pos
      KeSMSw4sRecoveryMDSecRwLtStHdrstUpwdDnwdPosMax_160: parameter-require-com-spec{init-value=0, parameter=Pos/Val}, required-interface=Pos
      KeSMSw4sRecoveryMDSecRwLtStHdrstUpwdDnwdPosMax_165: parameter-require-com-spec{init-value=0, parameter=Pos/Val}, required-interface=Pos
      KeSMSw4sRecoveryMDSecRwLtStHdrstUpwdDnwdPosMax_170: parameter-require-com-spec{init-value=0, parameter=Pos/Val}, required-interface=Pos
      KeSMSw4sRecoveryMDSecRwLtStHdrstUpwdDnwdPosMax_175: parameter-require-com-spec{init-value=0, parameter=Pos/Val}, required-interface=Pos
      KeSMSw4sRecoveryMDSecRwLtStHdrstUpwdDnwdPosMax_180: parameter-require-com-spec{init-value=0, parameter=Pos/Val}, required-interface=Pos
      KeSMSw4sRecoveryMDSecRwLtStHdrstUpwdDnwdPosMax_Below160: parameter-require-com-spec{init-value=0, parameter=Pos/Val}, required-interface=Pos
      KeSMSw4sRecoveryMDSecRwLtStHdrstUpwdDnwdPosMax_Over180: parameter-require-com-spec{init-value=0, parameter=Pos/Val}, required-interface=Pos
      KeSMSw4sRecoveryMDSecRwLtStHdrstUpwdDnwdPosMin: parameter-require-com-spec{init-value=0, parameter=Pos/Val}, required-interface=Pos
      KeSMSw4sRecoveryMDSecRwLtStHdrstUpwdDnwdPosMin_160: parameter-require-com-spec{init-value=0, parameter=Pos/Val}, required-interface=Pos
      KeSMSw4sRecoveryMDSecRwLtStHdrstUpwdDnwdPosMin_165: parameter-require-com-spec{init-value=0, parameter=Pos/Val}, required-interface=Pos
      KeSMSw4sRecoveryMDSecRwLtStHdrstUpwdDnwdPosMin_170: parameter-require-com-spec{init-value=0, parameter=Pos/Val}, required-interface=Pos
      KeSMSw4sRecoveryMDSecRwLtStHdrstUpwdDnwdPosMin_175: parameter-require-com-spec{init-value=0, parameter=Pos/Val}, required-interface=Pos
      KeSMSw4sRecoveryMDSecRwLtStHdrstUpwdDnwdPosMin_180: parameter-require-com-spec{init-value=0, parameter=Pos/Val}, required-interface=Pos
      KeSMSw4sRecoveryMDSecRwLtStHdrstUpwdDnwdPosMin_Below160: parameter-require-com-spec{init-value=0, parameter=Pos/Val}, required-interface=Pos
      KeSMSw4sRecoveryMDSecRwLtStHdrstUpwdDnwdPosMin_Over180: parameter-require-com-spec{init-value=0, parameter=Pos/Val}, required-interface=Pos
      KeSMSw4sRecoveryMDSecRwLtStLgrstOtwdInwdPos: parameter-require-com-spec{init-value=0, parameter=Pos/Val}, required-interface=Pos
      KeSMSw4sRecoveryMDSecRwLtStLgrstOtwdInwdPos_160: parameter-require-com-spec{init-value=0, parameter=Pos/Val}, required-interface=Pos
      KeSMSw4sRecoveryMDSecRwLtStLgrstOtwdInwdPos_165: parameter-require-com-spec{init-value=0, parameter=Pos/Val}, required-interface=Pos
      KeSMSw4sRecoveryMDSecRwLtStLgrstOtwdInwdPos_170: parameter-require-com-spec{init-value=0, parameter=Pos/Val}, required-interface=Pos
      KeSMSw4sRecoveryMDSecRwLtStLgrstOtwdInwdPos_175: parameter-require-com-spec{init-value=0, parameter=Pos/Val}, required-interface=Pos
      KeSMSw4sRecoveryMDSecRwLtStLgrstOtwdInwdPos_180: parameter-require-com-spec{init-value=0, parameter=Pos/Val}, required-interface=Pos
      KeSMSw4sRecoveryMDSecRwLtStLgrstOtwdInwdPos_Below160: parameter-require-com-spec{init-value=0, parameter=Pos/Val}, required-interface=Pos
      KeSMSw4sRecoveryMDSecRwLtStLgrstOtwdInwdPos_Over180: parameter-require-com-spec{init-value=0, parameter=Pos/Val}, required-interface=Pos
      KeSMSw4sRecoveryMDSecRwLtStLgrstOtwdInwdPosMax: parameter-require-com-spec{init-value=0, parameter=Pos/Val}, required-interface=Pos
      KeSMSw4sRecoveryMDSecRwLtStLgrstOtwdInwdPosMax_160: parameter-require-com-spec{init-value=0, parameter=Pos/Val}, required-interface=Pos
      KeSMSw4sRecoveryMDSecRwLtStLgrstOtwdInwdPosMax_165: parameter-require-com-spec{init-value=0, parameter=Pos/Val}, required-interface=Pos
      KeSMSw4sRecoveryMDSecRwLtStLgrstOtwdInwdPosMax_170: parameter-require-com-spec{init-value=0, parameter=Pos/Val}, required-interface=Pos
      KeSMSw4sRecoveryMDSecRwLtStLgrstOtwdInwdPosMax_175: parameter-require-com-spec{init-value=0, parameter=Pos/Val}, required-interface=Pos
      KeSMSw4sRecoveryMDSecRwLtStLgrstOtwdInwdPosMax_180: parameter-require-com-spec{init-value=0, parameter=Pos/Val}, required-interface=Pos
      KeSMSw4sRecoveryMDSecRwLtStLgrstOtwdInwdPosMax_Below160: parameter-require-com-spec{init-value=0, parameter=Pos/Val}, required-interface=Pos
      KeSMSw4sRecoveryMDSecRwLtStLgrstOtwdInwdPosMax_Over180: parameter-require-com-spec{init-value=0, parameter=Pos/Val}, required-interface=Pos
      KeSMSw4sRecoveryMDSecRwLtStLgrstOtwdInwdPosMin: parameter-require-com-spec{init-value=0, parameter=Pos/Val}, required-interface=Pos
      KeSMSw4sRecoveryMDSecRwLtStLgrstOtwdInwdPosMin_160: parameter-require-com-spec{init-value=0, parameter=Pos/Val}, required-interface=Pos
      KeSMSw4sRecoveryMDSecRwLtStLgrstOtwdInwdPosMin_165: parameter-require-com-spec{init-value=0, parameter=Pos/Val}, required-interface=Pos
      KeSMSw4sRecoveryMDSecRwLtStLgrstOtwdInwdPosMin_170: parameter-require-com-spec{init-value=0, parameter=Pos/Val}, required-interface=Pos
      KeSMSw4sRecoveryMDSecRwLtStLgrstOtwdInwdPosMin_175: parameter-require-com-spec{init-value=0, parameter=Pos/Val}, required-interface=Pos
      KeSMSw4sRecoveryMDSecRwLtStLgrstOtwdInwdPosMin_180: parameter-require-com-spec{init-value=0, parameter=Pos/Val}, required-interface=Pos
      KeSMSw4sRecoveryMDSecRwLtStLgrstOtwdInwdPosMin_Below160: parameter-require-com-spec{init-value=0, parameter=Pos/Val}, required-interface=Pos
      KeSMSw4sRecoveryMDSecRwLtStLgrstOtwdInwdPosMin_Over180: parameter-require-com-spec{init-value=0, parameter=Pos/Val}, required-interface=Pos
      KeSMSw4sRecoveryMDSecRwLtStLgrstUpwdDnwdPos: parameter-require-com-spec{init-value=0, parameter=Pos/Val}, required-interface=Pos
      KeSMSw4sRecoveryMDSecRwLtStLgrstUpwdDnwdPosMax: parameter-require-com-spec{init-value=0, parameter=Pos/Val}, required-interface=Pos
      KeSMSw4sRecoveryMDSecRwLtStLgrstUpwdDnwdPosMin: parameter-require-com-spec{init-value=0, parameter=Pos/Val}, required-interface=Pos
      KeSMSw4sRecoveryMDSecRwRtStBkReclnUpwdDnwdPos: parameter-require-com-spec{init-value=0, parameter=Pos/Val}, required-interface=Pos
      KeSMSw4sRecoveryMDSecRwRtStBkReclnUpwdDnwdPosMax: parameter-require-com-spec{init-value=0, parameter=Pos/Val}, required-interface=Pos
      KeSMSw4sRecoveryMDSecRwRtStBkReclnUpwdDnwdPosMin: parameter-require-com-spec{init-value=0, parameter=Pos/Val}, required-interface=Pos
      KeSMSw4sRecoveryMDSecRwRtStFtrstUpwdDnwdPos: parameter-require-com-spec{init-value=0, parameter=Pos/Val}, required-interface=Pos
      KeSMSw4sRecoveryMDSecRwRtStFtrstUpwdDnwdPosMax: parameter-require-com-spec{init-value=0, parameter=Pos/Val}, required-interface=Pos
      KeSMSw4sRecoveryMDSecRwRtStFtrstUpwdDnwdPosMin: parameter-require-com-spec{init-value=0, parameter=Pos/Val}, required-interface=Pos
      KeSMSw4sRecoveryMDSecRwRtStHdrstFrwdBkwdPos: parameter-require-com-spec{init-value=0, parameter=Pos/Val}, required-interface=Pos
      KeSMSw4sRecoveryMDSecRwRtStHdrstFrwdBkwdPos_160: parameter-require-com-spec{init-value=0, parameter=Pos/Val}, required-interface=Pos
      KeSMSw4sRecoveryMDSecRwRtStHdrstFrwdBkwdPos_165: parameter-require-com-spec{init-value=0, parameter=Pos/Val}, required-interface=Pos
      KeSMSw4sRecoveryMDSecRwRtStHdrstFrwdBkwdPos_170: parameter-require-com-spec{init-value=0, parameter=Pos/Val}, required-interface=Pos
      KeSMSw4sRecoveryMDSecRwRtStHdrstFrwdBkwdPos_175: parameter-require-com-spec{init-value=0, parameter=Pos/Val}, required-interface=Pos
      KeSMSw4sRecoveryMDSecRwRtStHdrstFrwdBkwdPos_180: parameter-require-com-spec{init-value=0, parameter=Pos/Val}, required-interface=Pos
      KeSMSw4sRecoveryMDSecRwRtStHdrstFrwdBkwdPos_Below160: parameter-require-com-spec{init-value=0, parameter=Pos/Val}, required-interface=Pos
      KeSMSw4sRecoveryMDSecRwRtStHdrstFrwdBkwdPos_Over180: parameter-require-com-spec{init-value=0, parameter=Pos/Val}, required-interface=Pos
      KeSMSw4sRecoveryMDSecRwRtStHdrstFrwdBkwdPosMax: parameter-require-com-spec{init-value=0, parameter=Pos/Val}, required-interface=Pos
      KeSMSw4sRecoveryMDSecRwRtStHdrstFrwdBkwdPosMax_160: parameter-require-com-spec{init-value=0, parameter=Pos/Val}, required-interface=Pos
      KeSMSw4sRecoveryMDSecRwRtStHdrstFrwdBkwdPosMax_165: parameter-require-com-spec{init-value=0, parameter=Pos/Val}, required-interface=Pos
      KeSMSw4sRecoveryMDSecRwRtStHdrstFrwdBkwdPosMax_170: parameter-require-com-spec{init-value=0, parameter=Pos/Val}, required-interface=Pos
      KeSMSw4sRecoveryMDSecRwRtStHdrstFrwdBkwdPosMax_175: parameter-require-com-spec{init-value=0, parameter=Pos/Val}, required-interface=Pos
      KeSMSw4sRecoveryMDSecRwRtStHdrstFrwdBkwdPosMax_180: parameter-require-com-spec{init-value=0, parameter=Pos/Val}, required-interface=Pos
      KeSMSw4sRecoveryMDSecRwRtStHdrstFrwdBkwdPosMax_Below160: parameter-require-com-spec{init-value=0, parameter=Pos/Val}, required-interface=Pos
      KeSMSw4sRecoveryMDSecRwRtStHdrstFrwdBkwdPosMax_Over180: parameter-require-com-spec{init-value=0, parameter=Pos/Val}, required-interface=Pos
      KeSMSw4sRecoveryMDSecRwRtStHdrstFrwdBkwdPosMin: parameter-require-com-spec{init-value=0, parameter=Pos/Val}, required-interface=Pos
      KeSMSw4sRecoveryMDSecRwRtStHdrstFrwdBkwdPosMin_160: parameter-require-com-spec{init-value=0, parameter=Pos/Val}, required-interface=Pos
      KeSMSw4sRecoveryMDSecRwRtStHdrstFrwdBkwdPosMin_165: parameter-require-com-spec{init-value=0, parameter=Pos/Val}, required-interface=Pos
      KeSMSw4sRecoveryMDSecRwRtStHdrstFrwdBkwdPosMin_170: parameter-require-com-spec{init-value=0, parameter=Pos/Val}, required-interface=Pos
      KeSMSw4sRecoveryMDSecRwRtStHdrstFrwdBkwdPosMin_175: parameter-require-com-spec{init-value=0, parameter=Pos/Val}, required-interface=Pos
      KeSMSw4sRecoveryMDSecRwRtStHdrstFrwdBkwdPosMin_180: parameter-require-com-spec{init-value=0, parameter=Pos/Val}, required-interface=Pos
      KeSMSw4sRecoveryMDSecRwRtStHdrstFrwdBkwdPosMin_Below160: parameter-require-com-spec{init-value=0, parameter=Pos/Val}, required-interface=Pos
      KeSMSw4sRecoveryMDSecRwRtStHdrstFrwdBkwdPosMin_Over180: parameter-require-com-spec{init-value=0, parameter=Pos/Val}, required-interface=Pos
      KeSMSw4sRecoveryMDSecRwRtStHdrstUpwdPos: parameter-require-com-spec{init-value=0, parameter=Pos/Val}, required-interface=Pos
      KeSMSw4sRecoveryMDSecRwRtStHdrstUpwdPos_160: parameter-require-com-spec{init-value=0, parameter=Pos/Val}, required-interface=Pos
      KeSMSw4sRecoveryMDSecRwRtStHdrstUpwdPos_165: parameter-require-com-spec{init-value=0, parameter=Pos/Val}, required-interface=Pos
      KeSMSw4sRecoveryMDSecRwRtStHdrstUpwdPos_170: parameter-require-com-spec{init-value=0, parameter=Pos/Val}, required-interface=Pos
      KeSMSw4sRecoveryMDSecRwRtStHdrstUpwdPos_175: parameter-require-com-spec{init-value=0, parameter=Pos/Val}, required-interface=Pos
      KeSMSw4sRecoveryMDSecRwRtStHdrstUpwdPos_180: parameter-require-com-spec{init-value=0, parameter=Pos/Val}, required-interface=Pos
      KeSMSw4sRecoveryMDSecRwRtStHdrstUpwdPos_Below160: parameter-require-com-spec{init-value=0, parameter=Pos/Val}, required-interface=Pos
      KeSMSw4sRecoveryMDSecRwRtStHdrstUpwdPos_Over180: parameter-require-com-spec{init-value=0, parameter=Pos/Val}, required-interface=Pos
      KeSMSw4sRecoveryMDSecRwRtStHdrstUpwdPosMax: parameter-require-com-spec{init-value=0, parameter=Pos/Val}, required-interface=Pos
      KeSMSw4sRecoveryMDSecRwRtStHdrstUpwdPosMax_160: parameter-require-com-spec{init-value=0, parameter=Pos/Val}, required-interface=Pos
      KeSMSw4sRecoveryMDSecRwRtStHdrstUpwdPosMax_165: parameter-require-com-spec{init-value=0, parameter=Pos/Val}, required-interface=Pos
      KeSMSw4sRecoveryMDSecRwRtStHdrstUpwdPosMax_170: parameter-require-com-spec{init-value=0, parameter=Pos/Val}, required-interface=Pos
      KeSMSw4sRecoveryMDSecRwRtStHdrstUpwdPosMax_175: parameter-require-com-spec{init-value=0, parameter=Pos/Val}, required-interface=Pos
      KeSMSw4sRecoveryMDSecRwRtStHdrstUpwdPosMax_180: parameter-require-com-spec{init-value=0, parameter=Pos/Val}, required-interface=Pos
      KeSMSw4sRecoveryMDSecRwRtStHdrstUpwdPosMax_Below160: parameter-require-com-spec{init-value=0, parameter=Pos/Val}, required-interface=Pos
      KeSMSw4sRecoveryMDSecRwRtStHdrstUpwdPosMax_Over180: parameter-require-com-spec{init-value=0, parameter=Pos/Val}, required-interface=Pos
      KeSMSw4sRecoveryMDSecRwRtStHdrstUpwdPosMin: parameter-require-com-spec{init-value=0, parameter=Pos/Val}, required-interface=Pos
      KeSMSw4sRecoveryMDSecRwRtStHdrstUpwdPosMin_160: parameter-require-com-spec{init-value=0, parameter=Pos/Val}, required-interface=Pos
      KeSMSw4sRecoveryMDSecRwRtStHdrstUpwdPosMin_165: parameter-require-com-spec{init-value=0, parameter=Pos/Val}, required-interface=Pos
      KeSMSw4sRecoveryMDSecRwRtStHdrstUpwdPosMin_170: parameter-require-com-spec{init-value=0, parameter=Pos/Val}, required-interface=Pos
      KeSMSw4sRecoveryMDSecRwRtStHdrstUpwdPosMin_175: parameter-require-com-spec{init-value=0, parameter=Pos/Val}, required-interface=Pos
      KeSMSw4sRecoveryMDSecRwRtStHdrstUpwdPosMin_180: parameter-require-com-spec{init-value=0, parameter=Pos/Val}, required-interface=Pos
      KeSMSw4sRecoveryMDSecRwRtStHdrstUpwdPosMin_Below160: parameter-require-com-spec{init-value=0, parameter=Pos/Val}, required-interface=Pos
      KeSMSw4sRecoveryMDSecRwRtStHdrstUpwdPosMin_Over180: parameter-require-com-spec{init-value=0, parameter=Pos/Val}, required-interface=Pos
      KeSMSw4sRecoveryMDSecRwRtStLgrstOtwdInwdPos: parameter-require-com-spec{init-value=0, parameter=Pos/Val}, required-interface=Pos
      KeSMSw4sRecoveryMDSecRwRtStLgrstOtwdInwdPos_160: parameter-require-com-spec{init-value=0, parameter=Pos/Val}, required-interface=Pos
      KeSMSw4sRecoveryMDSecRwRtStLgrstOtwdInwdPos_165: parameter-require-com-spec{init-value=0, parameter=Pos/Val}, required-interface=Pos
      KeSMSw4sRecoveryMDSecRwRtStLgrstOtwdInwdPos_170: parameter-require-com-spec{init-value=0, parameter=Pos/Val}, required-interface=Pos
      KeSMSw4sRecoveryMDSecRwRtStLgrstOtwdInwdPos_175: parameter-require-com-spec{init-value=0, parameter=Pos/Val}, required-interface=Pos
      KeSMSw4sRecoveryMDSecRwRtStLgrstOtwdInwdPos_180: parameter-require-com-spec{init-value=0, parameter=Pos/Val}, required-interface=Pos
      KeSMSw4sRecoveryMDSecRwRtStLgrstOtwdInwdPos_Below160: parameter-require-com-spec{init-value=0, parameter=Pos/Val}, required-interface=Pos
      KeSMSw4sRecoveryMDSecRwRtStLgrstOtwdInwdPos_Over180: parameter-require-com-spec{init-value=0, parameter=Pos/Val}, required-interface=Pos
      KeSMSw4sRecoveryMDSecRwRtStLgrstOtwdInwdPosMax: parameter-require-com-spec{init-value=0, parameter=Pos/Val}, required-interface=Pos
      KeSMSw4sRecoveryMDSecRwRtStLgrstOtwdInwdPosMax_160: parameter-require-com-spec{init-value=0, parameter=Pos/Val}, required-interface=Pos
      KeSMSw4sRecoveryMDSecRwRtStLgrstOtwdInwdPosMax_165: parameter-require-com-spec{init-value=0, parameter=Pos/Val}, required-interface=Pos
      KeSMSw4sRecoveryMDSecRwRtStLgrstOtwdInwdPosMax_170: parameter-require-com-spec{init-value=0, parameter=Pos/Val}, required-interface=Pos
      KeSMSw4sRecoveryMDSecRwRtStLgrstOtwdInwdPosMax_175: parameter-require-com-spec{init-value=0, parameter=Pos/Val}, required-interface=Pos
      KeSMSw4sRecoveryMDSecRwRtStLgrstOtwdInwdPosMax_180: parameter-require-com-spec{init-value=0, parameter=Pos/Val}, required-interface=Pos
      KeSMSw4sRecoveryMDSecRwRtStLgrstOtwdInwdPosMax_Below160: parameter-require-com-spec{init-value=0, parameter=Pos/Val}, required-interface=Pos
      KeSMSw4sRecoveryMDSecRwRtStLgrstOtwdInwdPosMax_Over180: parameter-require-com-spec{init-value=0, parameter=Pos/Val}, required-interface=Pos
      KeSMSw4sRecoveryMDSecRwRtStLgrstOtwdInwdPosMin: parameter-require-com-spec{init-value=0, parameter=Pos/Val}, required-interface=Pos
      KeSMSw4sRecoveryMDSecRwRtStLgrstOtwdInwdPosMin_160: parameter-require-com-spec{init-value=0, parameter=Pos/Val}, required-interface=Pos
      KeSMSw4sRecoveryMDSecRwRtStLgrstOtwdInwdPosMin_165: parameter-require-com-spec{init-value=0, parameter=Pos/Val}, required-interface=Pos
      KeSMSw4sRecoveryMDSecRwRtStLgrstOtwdInwdPosMin_170: parameter-require-com-spec{init-value=0, parameter=Pos/Val}, required-interface=Pos
      KeSMSw4sRecoveryMDSecRwRtStLgrstOtwdInwdPosMin_175: parameter-require-com-spec{init-value=0, parameter=Pos/Val}, required-interface=Pos
      KeSMSw4sRecoveryMDSecRwRtStLgrstOtwdInwdPosMin_180: parameter-require-com-spec{init-value=0, parameter=Pos/Val}, required-interface=Pos
      KeSMSw4sRecoveryMDSecRwRtStLgrstOtwdInwdPosMin_Below160: parameter-require-com-spec{init-value=0, parameter=Pos/Val}, required-interface=Pos
      KeSMSw4sRecoveryMDSecRwRtStLgrstOtwdInwdPosMin_Over180: parameter-require-com-spec{init-value=0, parameter=Pos/Val}, required-interface=Pos
      KeSMSw4sRecoveryMDSecRwRtStLgrstUpwdPos: parameter-require-com-spec{init-value=0, parameter=Pos/Val}, required-interface=Pos
      KeSMSw4sRecoveryMDSecRwRtStLgrstUpwdPosMax: parameter-require-com-spec{init-value=0, parameter=Pos/Val}, required-interface=Pos
      KeSMSw4sRecoveryMDSecRwRtStLgrstUpwdPosMin: parameter-require-com-spec{init-value=0, parameter=Pos/Val}, required-interface=Pos
      KeSMSw4SSecRwLtStLgrstOtwdInwdClosePos1: parameter-require-com-spec{init-value=0, parameter=Pos/Val}, required-interface=Pos
      KeSMSw4SSecRwLtStLgrstUpwdDnwdClosePos1: parameter-require-com-spec{init-value=0, parameter=Pos/Val}, required-interface=Pos
      KeSMSw4SSecRwLtStLgrstUpwdDnwdClosePos2: parameter-require-com-spec{init-value=0, parameter=Pos/Val}, required-interface=Pos
      KeSMSw4SSecRwLtStLgrstUpwdDnwdOpenPos1: parameter-require-com-spec{init-value=0, parameter=Pos/Val}, required-interface=Pos
      KeSMSw4SSecRwRtStLgrstOtwdInwdClosePos1: parameter-require-com-spec{init-value=0, parameter=Pos/Val}, required-interface=Pos
      KeSMSw4SSecRwRtStLgrstUpwdDnwdClosePos1: parameter-require-com-spec{init-value=0, parameter=Pos/Val}, required-interface=Pos
      KeSMSw4SSecRwRtStLgrstUpwdDnwdClosePos2: parameter-require-com-spec{init-value=0, parameter=Pos/Val}, required-interface=Pos
      KeSMSw4SSecRwRtStLgrstUpwdDnwdOpenPos1: parameter-require-com-spec{init-value=0, parameter=Pos/Val}, required-interface=Pos
      KeSMSw4sVIPMDSecRwLtStBkReclnUpwdDnwdPos: parameter-require-com-spec{init-value=0, parameter=Pos/Val}, required-interface=Pos
      KeSMSw4sVIPMDSecRwLtStBkReclnUpwdDnwdPosMax: parameter-require-com-spec{init-value=0, parameter=Pos/Val}, required-interface=Pos
      KeSMSw4sVIPMDSecRwLtStBkReclnUpwdDnwdPosMin: parameter-require-com-spec{init-value=0, parameter=Pos/Val}, required-interface=Pos
      KeSMSw4sVIPMDSecRwLtStFtrstUpwdDnwdPos: parameter-require-com-spec{init-value=0, parameter=Pos/Val}, required-interface=Pos
      KeSMSw4sVIPMDSecRwLtStFtrstUpwdDnwdPosMax: parameter-require-com-spec{init-value=0, parameter=Pos/Val}, required-interface=Pos
      KeSMSw4sVIPMDSecRwLtStFtrstUpwdDnwdPosMin: parameter-require-com-spec{init-value=0, parameter=Pos/Val}, required-interface=Pos
      KeSMSw4sVIPMDSecRwLtStHdrstFrwdBkwdPos: parameter-require-com-spec{init-value=0, parameter=Pos/Val}, required-interface=Pos
      KeSMSw4sVIPMDSecRwLtStHdrstFrwdBkwdPos_160: parameter-require-com-spec{init-value=0, parameter=Pos/Val}, required-interface=Pos
      KeSMSw4sVIPMDSecRwLtStHdrstFrwdBkwdPos_165: parameter-require-com-spec{init-value=0, parameter=Pos/Val}, required-interface=Pos
      KeSMSw4sVIPMDSecRwLtStHdrstFrwdBkwdPos_170: parameter-require-com-spec{init-value=0, parameter=Pos/Val}, required-interface=Pos
      KeSMSw4sVIPMDSecRwLtStHdrstFrwdBkwdPos_175: parameter-require-com-spec{init-value=0, parameter=Pos/Val}, required-interface=Pos
      KeSMSw4sVIPMDSecRwLtStHdrstFrwdBkwdPos_180: parameter-require-com-spec{init-value=0, parameter=Pos/Val}, required-interface=Pos
      KeSMSw4sVIPMDSecRwLtStHdrstFrwdBkwdPos_Below160: parameter-require-com-spec{init-value=0, parameter=Pos/Val}, required-interface=Pos
      KeSMSw4sVIPMDSecRwLtStHdrstFrwdBkwdPos_Over180: parameter-require-com-spec{init-value=0, parameter=Pos/Val}, required-interface=Pos
      KeSMSw4sVIPMDSecRwLtStHdrstFrwdBkwdPosMax: parameter-require-com-spec{init-value=0, parameter=Pos/Val}, required-interface=Pos
      KeSMSw4sVIPMDSecRwLtStHdrstFrwdBkwdPosMax_160: parameter-require-com-spec{init-value=0, parameter=Pos/Val}, required-interface=Pos
      KeSMSw4sVIPMDSecRwLtStHdrstFrwdBkwdPosMax_165: parameter-require-com-spec{init-value=0, parameter=Pos/Val}, required-interface=Pos
      KeSMSw4sVIPMDSecRwLtStHdrstFrwdBkwdPosMax_170: parameter-require-com-spec{init-value=0, parameter=Pos/Val}, required-interface=Pos
      KeSMSw4sVIPMDSecRwLtStHdrstFrwdBkwdPosMax_175: parameter-require-com-spec{init-value=0, parameter=Pos/Val}, required-interface=Pos
      KeSMSw4sVIPMDSecRwLtStHdrstFrwdBkwdPosMax_180: parameter-require-com-spec{init-value=0, parameter=Pos/Val}, required-interface=Pos
      KeSMSw4sVIPMDSecRwLtStHdrstFrwdBkwdPosMax_Below160: parameter-require-com-spec{init-value=0, parameter=Pos/Val}, required-interface=Pos
      KeSMSw4sVIPMDSecRwLtStHdrstFrwdBkwdPosMax_Over180: parameter-require-com-spec{init-value=0, parameter=Pos/Val}, required-interface=Pos
      KeSMSw4sVIPMDSecRwLtStHdrstFrwdBkwdPosMin: parameter-require-com-spec{init-value=0, parameter=Pos/Val}, required-interface=Pos
      KeSMSw4sVIPMDSecRwLtStHdrstFrwdBkwdPosMin_160: parameter-require-com-spec{init-value=0, parameter=Pos/Val}, required-interface=Pos
      KeSMSw4sVIPMDSecRwLtStHdrstFrwdBkwdPosMin_165: parameter-require-com-spec{init-value=0, parameter=Pos/Val}, required-interface=Pos
      KeSMSw4sVIPMDSecRwLtStHdrstFrwdBkwdPosMin_170: parameter-require-com-spec{init-value=0, parameter=Pos/Val}, required-interface=Pos
      KeSMSw4sVIPMDSecRwLtStHdrstFrwdBkwdPosMin_175: parameter-require-com-spec{init-value=0, parameter=Pos/Val}, required-interface=Pos
      KeSMSw4sVIPMDSecRwLtStHdrstFrwdBkwdPosMin_180: parameter-require-com-spec{init-value=0, parameter=Pos/Val}, required-interface=Pos
      KeSMSw4sVIPMDSecRwLtStHdrstFrwdBkwdPosMin_Below160: parameter-require-com-spec{init-value=0, parameter=Pos/Val}, required-interface=Pos
      KeSMSw4sVIPMDSecRwLtStHdrstFrwdBkwdPosMin_Over180: parameter-require-com-spec{init-value=0, parameter=Pos/Val}, required-interface=Pos
      KeSMSw4sVIPMDSecRwLtStHdrstUpwdDnwdPos: parameter-require-com-spec{init-value=0, parameter=Pos/Val}, required-interface=Pos
      KeSMSw4sVIPMDSecRwLtStHdrstUpwdDnwdPos_160: parameter-require-com-spec{init-value=0, parameter=Pos/Val}, required-interface=Pos
      KeSMSw4sVIPMDSecRwLtStHdrstUpwdDnwdPos_165: parameter-require-com-spec{init-value=0, parameter=Pos/Val}, required-interface=Pos
      KeSMSw4sVIPMDSecRwLtStHdrstUpwdDnwdPos_170: parameter-require-com-spec{init-value=0, parameter=Pos/Val}, required-interface=Pos
      KeSMSw4sVIPMDSecRwLtStHdrstUpwdDnwdPos_175: parameter-require-com-spec{init-value=0, parameter=Pos/Val}, required-interface=Pos
      KeSMSw4sVIPMDSecRwLtStHdrstUpwdDnwdPos_180: parameter-require-com-spec{init-value=0, parameter=Pos/Val}, required-interface=Pos
      KeSMSw4sVIPMDSecRwLtStHdrstUpwdDnwdPos_Below160: parameter-require-com-spec{init-value=0, parameter=Pos/Val}, required-interface=Pos
      KeSMSw4sVIPMDSecRwLtStHdrstUpwdDnwdPos_Over180: parameter-require-com-spec{init-value=0, parameter=Pos/Val}, required-interface=Pos
      KeSMSw4sVIPMDSecRwLtStHdrstUpwdDnwdPosMax: parameter-require-com-spec{init-value=0, parameter=Pos/Val}, required-interface=Pos
      KeSMSw4sVIPMDSecRwLtStHdrstUpwdDnwdPosMax_160: parameter-require-com-spec{init-value=0, parameter=Pos/Val}, required-interface=Pos
      KeSMSw4sVIPMDSecRwLtStHdrstUpwdDnwdPosMax_165: parameter-require-com-spec{init-value=0, parameter=Pos/Val}, required-interface=Pos
      KeSMSw4sVIPMDSecRwLtStHdrstUpwdDnwdPosMax_170: parameter-require-com-spec{init-value=0, parameter=Pos/Val}, required-interface=Pos
      KeSMSw4sVIPMDSecRwLtStHdrstUpwdDnwdPosMax_175: parameter-require-com-spec{init-value=0, parameter=Pos/Val}, required-interface=Pos
      KeSMSw4sVIPMDSecRwLtStHdrstUpwdDnwdPosMax_180: parameter-require-com-spec{init-value=0, parameter=Pos/Val}, required-interface=Pos
      KeSMSw4sVIPMDSecRwLtStHdrstUpwdDnwdPosMax_Below160: parameter-require-com-spec{init-value=0, parameter=Pos/Val}, required-interface=Pos
      KeSMSw4sVIPMDSecRwLtStHdrstUpwdDnwdPosMax_Over180: parameter-require-com-spec{init-value=0, parameter=Pos/Val}, required-interface=Pos
      KeSMSw4sVIPMDSecRwLtStHdrstUpwdDnwdPosMin: parameter-require-com-spec{init-value=0, parameter=Pos/Val}, required-interface=Pos
      KeSMSw4sVIPMDSecRwLtStHdrstUpwdDnwdPosMin_160: parameter-require-com-spec{init-value=0, parameter=Pos/Val}, required-interface=Pos
      KeSMSw4sVIPMDSecRwLtStHdrstUpwdDnwdPosMin_165: parameter-require-com-spec{init-value=0, parameter=Pos/Val}, required-interface=Pos
      KeSMSw4sVIPMDSecRwLtStHdrstUpwdDnwdPosMin_170: parameter-require-com-spec{init-value=0, parameter=Pos/Val}, required-interface=Pos
      KeSMSw4sVIPMDSecRwLtStHdrstUpwdDnwdPosMin_175: parameter-require-com-spec{init-value=0, parameter=Pos/Val}, required-interface=Pos
      KeSMSw4sVIPMDSecRwLtStHdrstUpwdDnwdPosMin_180: parameter-require-com-spec{init-value=0, parameter=Pos/Val}, required-interface=Pos
      KeSMSw4sVIPMDSecRwLtStHdrstUpwdDnwdPosMin_Below160: parameter-require-com-spec{init-value=0, parameter=Pos/Val}, required-interface=Pos
      KeSMSw4sVIPMDSecRwLtStHdrstUpwdDnwdPosMin_Over180: parameter-require-com-spec{init-value=0, parameter=Pos/Val}, required-interface=Pos
      KeSMSw4sVIPMDSecRwLtStLgrstOtwdInwdPos: parameter-require-com-spec{init-value=0, parameter=Pos/Val}, required-interface=Pos
      KeSMSw4sVIPMDSecRwLtStLgrstOtwdInwdPos_160: parameter-require-com-spec{init-value=0, parameter=Pos/Val}, required-interface=Pos
      KeSMSw4sVIPMDSecRwLtStLgrstOtwdInwdPos_165: parameter-require-com-spec{init-value=0, parameter=Pos/Val}, required-interface=Pos
      KeSMSw4sVIPMDSecRwLtStLgrstOtwdInwdPos_170: parameter-require-com-spec{init-value=0, parameter=Pos/Val}, required-interface=Pos
      KeSMSw4sVIPMDSecRwLtStLgrstOtwdInwdPos_175: parameter-require-com-spec{init-value=0, parameter=Pos/Val}, required-interface=Pos
      KeSMSw4sVIPMDSecRwLtStLgrstOtwdInwdPos_180: parameter-require-com-spec{init-value=0, parameter=Pos/Val}, required-interface=Pos
      KeSMSw4sVIPMDSecRwLtStLgrstOtwdInwdPos_Below160: parameter-require-com-spec{init-value=0, parameter=Pos/Val}, required-interface=Pos
      KeSMSw4sVIPMDSecRwLtStLgrstOtwdInwdPos_Over180: parameter-require-com-spec{init-value=0, parameter=Pos/Val}, required-interface=Pos
      KeSMSw4sVIPMDSecRwLtStLgrstOtwdInwdPosMax: parameter-require-com-spec{init-value=0, parameter=Pos/Val}, required-interface=Pos
      KeSMSw4sVIPMDSecRwLtStLgrstOtwdInwdPosMax_160: parameter-require-com-spec{init-value=0, parameter=Pos/Val}, required-interface=Pos
      KeSMSw4sVIPMDSecRwLtStLgrstOtwdInwdPosMax_165: parameter-require-com-spec{init-value=0, parameter=Pos/Val}, required-interface=Pos
      KeSMSw4sVIPMDSecRwLtStLgrstOtwdInwdPosMax_170: parameter-require-com-spec{init-value=0, parameter=Pos/Val}, required-interface=Pos
      KeSMSw4sVIPMDSecRwLtStLgrstOtwdInwdPosMax_175: parameter-require-com-spec{init-value=0, parameter=Pos/Val}, required-interface=Pos
      KeSMSw4sVIPMDSecRwLtStLgrstOtwdInwdPosMax_180: parameter-require-com-spec{init-value=0, parameter=Pos/Val}, required-interface=Pos
      KeSMSw4sVIPMDSecRwLtStLgrstOtwdInwdPosMax_Below160: parameter-require-com-spec{init-value=0, parameter=Pos/Val}, required-interface=Pos
      KeSMSw4sVIPMDSecRwLtStLgrstOtwdInwdPosMax_Over180: parameter-require-com-spec{init-value=0, parameter=Pos/Val}, required-interface=Pos
      KeSMSw4sVIPMDSecRwLtStLgrstOtwdInwdPosMin: parameter-require-com-spec{init-value=0, parameter=Pos/Val}, required-interface=Pos
      KeSMSw4sVIPMDSecRwLtStLgrstOtwdInwdPosMin_160: parameter-require-com-spec{init-value=0, parameter=Pos/Val}, required-interface=Pos
      KeSMSw4sVIPMDSecRwLtStLgrstOtwdInwdPosMin_165: parameter-require-com-spec{init-value=0, parameter=Pos/Val}, required-interface=Pos
      KeSMSw4sVIPMDSecRwLtStLgrstOtwdInwdPosMin_170: parameter-require-com-spec{init-value=0, parameter=Pos/Val}, required-interface=Pos
      KeSMSw4sVIPMDSecRwLtStLgrstOtwdInwdPosMin_175: parameter-require-com-spec{init-value=0, parameter=Pos/Val}, required-interface=Pos
      KeSMSw4sVIPMDSecRwLtStLgrstOtwdInwdPosMin_180: parameter-require-com-spec{init-value=0, parameter=Pos/Val}, required-interface=Pos
      KeSMSw4sVIPMDSecRwLtStLgrstOtwdInwdPosMin_Below160: parameter-require-com-spec{init-value=0, parameter=Pos/Val}, required-interface=Pos
      KeSMSw4sVIPMDSecRwLtStLgrstOtwdInwdPosMin_Over180: parameter-require-com-spec{init-value=0, parameter=Pos/Val}, required-interface=Pos
      KeSMSw4sVIPMDSecRwLtStLgrstUpwdDnwdPos: parameter-require-com-spec{init-value=0, parameter=Pos/Val}, required-interface=Pos
      KeSMSw4sVIPMDSecRwLtStLgrstUpwdDnwdPosMax: parameter-require-com-spec{init-value=0, parameter=Pos/Val}, required-interface=Pos
      KeSMSw4sVIPMDSecRwLtStLgrstUpwdDnwdPosMin: parameter-require-com-spec{init-value=0, parameter=Pos/Val}, required-interface=Pos
      KeSMSw4sVIPMDSecRwRtStBkReclnUpwdDnwdPos: parameter-require-com-spec{init-value=0, parameter=Pos/Val}, required-interface=Pos
      KeSMSw4sVIPMDSecRwRtStBkReclnUpwdDnwdPosMax: parameter-require-com-spec{init-value=0, parameter=Pos/Val}, required-interface=Pos
      KeSMSw4sVIPMDSecRwRtStBkReclnUpwdDnwdPosMin: parameter-require-com-spec{init-value=0, parameter=Pos/Val}, required-interface=Pos
      KeSMSw4sVIPMDSecRwRtStFtrstUpwdDnwdPos: parameter-require-com-spec{init-value=0, parameter=Pos/Val}, required-interface=Pos
      KeSMSw4sVIPMDSecRwRtStFtrstUpwdDnwdPosMax: parameter-require-com-spec{init-value=0, parameter=Pos/Val}, required-interface=Pos
      KeSMSw4sVIPMDSecRwRtStFtrstUpwdDnwdPosMin: parameter-require-com-spec{init-value=0, parameter=Pos/Val}, required-interface=Pos
      KeSMSw4sVIPMDSecRwRtStHdrstFrwdBkwdPos: parameter-require-com-spec{init-value=0, parameter=Pos/Val}, required-interface=Pos
      KeSMSw4sVIPMDSecRwRtStHdrstFrwdBkwdPos_160: parameter-require-com-spec{init-value=0, parameter=Pos/Val}, required-interface=Pos
      KeSMSw4sVIPMDSecRwRtStHdrstFrwdBkwdPos_165: parameter-require-com-spec{init-value=0, parameter=Pos/Val}, required-interface=Pos
      KeSMSw4sVIPMDSecRwRtStHdrstFrwdBkwdPos_170: parameter-require-com-spec{init-value=0, parameter=Pos/Val}, required-interface=Pos
      KeSMSw4sVIPMDSecRwRtStHdrstFrwdBkwdPos_175: parameter-require-com-spec{init-value=0, parameter=Pos/Val}, required-interface=Pos
      KeSMSw4sVIPMDSecRwRtStHdrstFrwdBkwdPos_180: parameter-require-com-spec{init-value=0, parameter=Pos/Val}, required-interface=Pos
      KeSMSw4sVIPMDSecRwRtStHdrstFrwdBkwdPos_Below160: parameter-require-com-spec{init-value=0, parameter=Pos/Val}, required-interface=Pos
      KeSMSw4sVIPMDSecRwRtStHdrstFrwdBkwdPos_Over180: parameter-require-com-spec{init-value=0, parameter=Pos/Val}, required-interface=Pos
      KeSMSw4sVIPMDSecRwRtStHdrstFrwdBkwdPosMax: parameter-require-com-spec{init-value=0, parameter=Pos/Val}, required-interface=Pos
      KeSMSw4sVIPMDSecRwRtStHdrstFrwdBkwdPosMax_160: parameter-require-com-spec{init-value=0, parameter=Pos/Val}, required-interface=Pos
      KeSMSw4sVIPMDSecRwRtStHdrstFrwdBkwdPosMax_165: parameter-require-com-spec{init-value=0, parameter=Pos/Val}, required-interface=Pos
      KeSMSw4sVIPMDSecRwRtStHdrstFrwdBkwdPosMax_170: parameter-require-com-spec{init-value=0, parameter=Pos/Val}, required-interface=Pos
      KeSMSw4sVIPMDSecRwRtStHdrstFrwdBkwdPosMax_175: parameter-require-com-spec{init-value=0, parameter=Pos/Val}, required-interface=Pos
      KeSMSw4sVIPMDSecRwRtStHdrstFrwdBkwdPosMax_180: parameter-require-com-spec{init-value=0, parameter=Pos/Val}, required-interface=Pos
      KeSMSw4sVIPMDSecRwRtStHdrstFrwdBkwdPosMax_Below160: parameter-require-com-spec{init-value=0, parameter=Pos/Val}, required-interface=Pos
      KeSMSw4sVIPMDSecRwRtStHdrstFrwdBkwdPosMax_Over180: parameter-require-com-spec{init-value=0, parameter=Pos/Val}, required-interface=Pos
      KeSMSw4sVIPMDSecRwRtStHdrstFrwdBkwdPosMin: parameter-require-com-spec{init-value=0, parameter=Pos/Val}, required-interface=Pos
      KeSMSw4sVIPMDSecRwRtStHdrstFrwdBkwdPosMin_160: parameter-require-com-spec{init-value=0, parameter=Pos/Val}, required-interface=Pos
      KeSMSw4sVIPMDSecRwRtStHdrstFrwdBkwdPosMin_165: parameter-require-com-spec{init-value=0, parameter=Pos/Val}, required-interface=Pos
      KeSMSw4sVIPMDSecRwRtStHdrstFrwdBkwdPosMin_170: parameter-require-com-spec{init-value=0, parameter=Pos/Val}, required-interface=Pos
      KeSMSw4sVIPMDSecRwRtStHdrstFrwdBkwdPosMin_175: parameter-require-com-spec{init-value=0, parameter=Pos/Val}, required-interface=Pos
      KeSMSw4sVIPMDSecRwRtStHdrstFrwdBkwdPosMin_180: parameter-require-com-spec{init-value=0, parameter=Pos/Val}, required-interface=Pos
      KeSMSw4sVIPMDSecRwRtStHdrstFrwdBkwdPosMin_Below160: parameter-require-com-spec{init-value=0, parameter=Pos/Val}, required-interface=Pos
      KeSMSw4sVIPMDSecRwRtStHdrstFrwdBkwdPosMin_Over180: parameter-require-com-spec{init-value=0, parameter=Pos/Val}, required-interface=Pos
      KeSMSw4sVIPMDSecRwRtStHdrstUpwdPos: parameter-require-com-spec{init-value=0, parameter=Pos/Val}, required-interface=Pos
      KeSMSw4sVIPMDSecRwRtStHdrstUpwdPos_160: parameter-require-com-spec{init-value=0, parameter=Pos/Val}, required-interface=Pos
      KeSMSw4sVIPMDSecRwRtStHdrstUpwdPos_165: parameter-require-com-spec{init-value=0, parameter=Pos/Val}, required-interface=Pos
      KeSMSw4sVIPMDSecRwRtStHdrstUpwdPos_170: parameter-require-com-spec{init-value=0, parameter=Pos/Val}, required-interface=Pos
      KeSMSw4sVIPMDSecRwRtStHdrstUpwdPos_175: parameter-require-com-spec{init-value=0, parameter=Pos/Val}, required-interface=Pos
      KeSMSw4sVIPMDSecRwRtStHdrstUpwdPos_180: parameter-require-com-spec{init-value=0, parameter=Pos/Val}, required-interface=Pos
      KeSMSw4sVIPMDSecRwRtStHdrstUpwdPos_Below160: parameter-require-com-spec{init-value=0, parameter=Pos/Val}, required-interface=Pos
      KeSMSw4sVIPMDSecRwRtStHdrstUpwdPos_Over180: parameter-require-com-spec{init-value=0, parameter=Pos/Val}, required-interface=Pos
      KeSMSw4sVIPMDSecRwRtStHdrstUpwdPosMax: parameter-require-com-spec{init-value=0, parameter=Pos/Val}, required-interface=Pos
      KeSMSw4sVIPMDSecRwRtStHdrstUpwdPosMax_160: parameter-require-com-spec{init-value=0, parameter=Pos/Val}, required-interface=Pos
      KeSMSw4sVIPMDSecRwRtStHdrstUpwdPosMax_165: parameter-require-com-spec{init-value=0, parameter=Pos/Val}, required-interface=Pos
      KeSMSw4sVIPMDSecRwRtStHdrstUpwdPosMax_170: parameter-require-com-spec{init-value=0, parameter=Pos/Val}, required-interface=Pos
      KeSMSw4sVIPMDSecRwRtStHdrstUpwdPosMax_175: parameter-require-com-spec{init-value=0, parameter=Pos/Val}, required-interface=Pos
      KeSMSw4sVIPMDSecRwRtStHdrstUpwdPosMax_180: parameter-require-com-spec{init-value=0, parameter=Pos/Val}, required-interface=Pos
      KeSMSw4sVIPMDSecRwRtStHdrstUpwdPosMax_Below160: parameter-require-com-spec{init-value=0, parameter=Pos/Val}, required-interface=Pos
      KeSMSw4sVIPMDSecRwRtStHdrstUpwdPosMax_Over180: parameter-require-com-spec{init-value=0, parameter=Pos/Val}, required-interface=Pos
      KeSMSw4sVIPMDSecRwRtStHdrstUpwdPosMin: parameter-require-com-spec{init-value=0, parameter=Pos/Val}, required-interface=Pos
      KeSMSw4sVIPMDSecRwRtStHdrstUpwdPosMin_160: parameter-require-com-spec{init-value=0, parameter=Pos/Val}, required-interface=Pos
      KeSMSw4sVIPMDSecRwRtStHdrstUpwdPosMin_165: parameter-require-com-spec{init-value=0, parameter=Pos/Val}, required-interface=Pos
      KeSMSw4sVIPMDSecRwRtStHdrstUpwdPosMin_170: parameter-require-com-spec{init-value=0, parameter=Pos/Val}, required-interface=Pos
      KeSMSw4sVIPMDSecRwRtStHdrstUpwdPosMin_175: parameter-require-com-spec{init-value=0, parameter=Pos/Val}, required-interface=Pos
      KeSMSw4sVIPMDSecRwRtStHdrstUpwdPosMin_180: parameter-require-com-spec{init-value=0, parameter=Pos/Val}, required-interface=Pos
      KeSMSw4sVIPMDSecRwRtStHdrstUpwdPosMin_Below160: parameter-require-com-spec{init-value=0, parameter=Pos/Val}, required-interface=Pos
      KeSMSw4sVIPMDSecRwRtStHdrstUpwdPosMin_Over180: parameter-require-com-spec{init-value=0, parameter=Pos/Val}, required-interface=Pos
      KeSMSw4sVIPMDSecRwRtStLgrstOtwdInwdPos: parameter-require-com-spec{init-value=0, parameter=Pos/Val}, required-interface=Pos
      KeSMSw4sVIPMDSecRwRtStLgrstOtwdInwdPos_160: parameter-require-com-spec{init-value=0, parameter=Pos/Val}, required-interface=Pos
      KeSMSw4sVIPMDSecRwRtStLgrstOtwdInwdPos_165: parameter-require-com-spec{init-value=0, parameter=Pos/Val}, required-interface=Pos
      KeSMSw4sVIPMDSecRwRtStLgrstOtwdInwdPos_170: parameter-require-com-spec{init-value=0, parameter=Pos/Val}, required-interface=Pos
      KeSMSw4sVIPMDSecRwRtStLgrstOtwdInwdPos_175: parameter-require-com-spec{init-value=0, parameter=Pos/Val}, required-interface=Pos
      KeSMSw4sVIPMDSecRwRtStLgrstOtwdInwdPos_180: parameter-require-com-spec{init-value=0, parameter=Pos/Val}, required-interface=Pos
      KeSMSw4sVIPMDSecRwRtStLgrstOtwdInwdPos_Below160: parameter-require-com-spec{init-value=0, parameter=Pos/Val}, required-interface=Pos
      KeSMSw4sVIPMDSecRwRtStLgrstOtwdInwdPos_Over180: parameter-require-com-spec{init-value=0, parameter=Pos/Val}, required-interface=Pos
      KeSMSw4sVIPMDSecRwRtStLgrstOtwdInwdPosMax: parameter-require-com-spec{init-value=0, parameter=Pos/Val}, required-interface=Pos
      KeSMSw4sVIPMDSecRwRtStLgrstOtwdInwdPosMax_160: parameter-require-com-spec{init-value=0, parameter=Pos/Val}, required-interface=Pos
      KeSMSw4sVIPMDSecRwRtStLgrstOtwdInwdPosMax_165: parameter-require-com-spec{init-value=0, parameter=Pos/Val}, required-interface=Pos
      KeSMSw4sVIPMDSecRwRtStLgrstOtwdInwdPosMax_170: parameter-require-com-spec{init-value=0, parameter=Pos/Val}, required-interface=Pos
      KeSMSw4sVIPMDSecRwRtStLgrstOtwdInwdPosMax_175: parameter-require-com-spec{init-value=0, parameter=Pos/Val}, required-interface=Pos
      KeSMSw4sVIPMDSecRwRtStLgrstOtwdInwdPosMax_180: parameter-require-com-spec{init-value=0, parameter=Pos/Val}, required-interface=Pos
      KeSMSw4sVIPMDSecRwRtStLgrstOtwdInwdPosMax_Below160: parameter-require-com-spec{init-value=0, parameter=Pos/Val}, required-interface=Pos
      KeSMSw4sVIPMDSecRwRtStLgrstOtwdInwdPosMax_Over180: parameter-require-com-spec{init-value=0, parameter=Pos/Val}, required-interface=Pos
      KeSMSw4sVIPMDSecRwRtStLgrstOtwdInwdPosMin: parameter-require-com-spec{init-value=0, parameter=Pos/Val}, required-interface=Pos
      KeSMSw4sVIPMDSecRwRtStLgrstOtwdInwdPosMin_160: parameter-require-com-spec{init-value=0, parameter=Pos/Val}, required-interface=Pos
      KeSMSw4sVIPMDSecRwRtStLgrstOtwdInwdPosMin_165: parameter-require-com-spec{init-value=0, parameter=Pos/Val}, required-interface=Pos
      KeSMSw4sVIPMDSecRwRtStLgrstOtwdInwdPosMin_170: parameter-require-com-spec{init-value=0, parameter=Pos/Val}, required-interface=Pos
      KeSMSw4sVIPMDSecRwRtStLgrstOtwdInwdPosMin_175: parameter-require-com-spec{init-value=0, parameter=Pos/Val}, required-interface=Pos
      KeSMSw4sVIPMDSecRwRtStLgrstOtwdInwdPosMin_180: parameter-require-com-spec{init-value=0, parameter=Pos/Val}, required-interface=Pos
      KeSMSw4sVIPMDSecRwRtStLgrstOtwdInwdPosMin_Below160: parameter-require-com-spec{init-value=0, parameter=Pos/Val}, required-interface=Pos
      KeSMSw4sVIPMDSecRwRtStLgrstOtwdInwdPosMin_Over180: parameter-require-com-spec{init-value=0, parameter=Pos/Val}, required-interface=Pos
      KeSMSw4sVIPMDSecRwRtStLgrstUpwdPos: parameter-require-com-spec{init-value=0, parameter=Pos/Val}, required-interface=Pos
      KeSMSw4sVIPMDSecRwRtStLgrstUpwdPosMax: parameter-require-com-spec{init-value=0, parameter=Pos/Val}, required-interface=Pos
      KeSMSw4sVIPMDSecRwRtStLgrstUpwdPosMin: parameter-require-com-spec{init-value=0, parameter=Pos/Val}, required-interface=Pos
      KeSMSw6sAcsEntryDrvStBkReclnUpwdDnwdPos: parameter-require-com-spec{init-value=1840, parameter=Pos/Val}, required-interface=Pos
      KeSMSw6sAcsEntryDrvStBkReclnUpwdDnwdPosMax: parameter-require-com-spec{init-value=1840, parameter=Pos/Val}, required-interface=Pos
      KeSMSw6sAcsEntryDrvStBkReclnUpwdDnwdPosMin: parameter-require-com-spec{init-value=0, parameter=Pos/Val}, required-interface=Pos
      KeSMSw6sAcsEntryDrvStFrwdBkwdPos: parameter-require-com-spec{init-value=2880, parameter=Pos/Val}, required-interface=Pos
      KeSMSw6sAcsEntryDrvStFrwdBkwdPosMax: parameter-require-com-spec{init-value=2880, parameter=Pos/Val}, required-interface=Pos
      KeSMSw6sAcsEntryDrvStFrwdBkwdPosMin: parameter-require-com-spec{init-value=0, parameter=Pos/Val}, required-interface=Pos
      KeSMSw6sAcsEntryDrvStFtUpwdDnwdPos: parameter-require-com-spec{init-value=0, parameter=Pos/Val}, required-interface=Pos
      KeSMSw6sAcsEntryDrvStFtUpwdDnwdPosMax: parameter-require-com-spec{init-value=0, parameter=Pos/Val}, required-interface=Pos
      KeSMSw6sAcsEntryDrvStFtUpwdDnwdPosMin: parameter-require-com-spec{init-value=0, parameter=Pos/Val}, required-interface=Pos
      KeSMSw6sAcsEntryPassStBkReclnUpwdDnwdPos: parameter-require-com-spec{init-value=1840, parameter=Pos/Val}, required-interface=Pos
      KeSMSw6sAcsEntryPassStBkReclnUpwdDnwdPosMax: parameter-require-com-spec{init-value=1840, parameter=Pos/Val}, required-interface=Pos
      KeSMSw6sAcsEntryPassStBkReclnUpwdDnwdPosMin: parameter-require-com-spec{init-value=0, parameter=Pos/Val}, required-interface=Pos
      KeSMSw6sAcsEntryPassStFrwdBkwdPos: parameter-require-com-spec{init-value=3000, parameter=Pos/Val}, required-interface=Pos
      KeSMSw6sAcsEntryPassStFrwdBkwdPosMax: parameter-require-com-spec{init-value=3167, parameter=Pos/Val}, required-interface=Pos
      KeSMSw6sAcsEntryPassStFrwdBkwdPosMin: parameter-require-com-spec{init-value=0, parameter=Pos/Val}, required-interface=Pos
      KeSMSw6sAcsEntryPassStFtUpwdDnwdPos: parameter-require-com-spec{init-value=0, parameter=Pos/Val}, required-interface=Pos
      KeSMSw6sAcsEntryPassStFtUpwdDnwdPosMiax: parameter-require-com-spec{init-value=0, parameter=Pos/Val}, required-interface=Pos
      KeSMSw6sAcsEntryPassStFtUpwdDnwdPosMin: parameter-require-com-spec{init-value=0, parameter=Pos/Val}, required-interface=Pos
      KeSMSw6sAcsEntrySecRwLtStArmScrnPos: parameter-require-com-spec{init-value=0, parameter=Pos/Val}, required-interface=Pos
      KeSMSw6sAcsEntrySecRwLtStArmScrnPosMax: parameter-require-com-spec{init-value=0, parameter=Pos/Val}, required-interface=Pos
      KeSMSw6sAcsEntrySecRwLtStArmScrnPosMin: parameter-require-com-spec{init-value=0, parameter=Pos/Val}, required-interface=Pos
      KeSMSw6sAcsEntrySecRwLtStBkReclnUpwdDnwdPos: parameter-require-com-spec{init-value=1280, parameter=Pos/Val}, required-interface=Pos
      KeSMSw6sAcsEntrySecRwLtStBkReclnUpwdDnwdPosMax: parameter-require-com-spec{init-value=1280, parameter=Pos/Val}, required-interface=Pos
      KeSMSw6sAcsEntrySecRwLtStBkReclnUpwdDnwdPosMin: parameter-require-com-spec{init-value=0, parameter=Pos/Val}, required-interface=Pos
      KeSMSw6sAcsEntrySecRwLtStFrwdBkwdPos: parameter-require-com-spec{init-value=727, parameter=Pos/Val}, required-interface=Pos
      KeSMSw6sAcsEntrySecRwLtStFrwdBkwdPosMax: parameter-require-com-spec{init-value=727, parameter=Pos/Val}, required-interface=Pos
      KeSMSw6sAcsEntrySecRwLtStFrwdBkwdPosMin: parameter-require-com-spec{init-value=727, parameter=Pos/Val}, required-interface=Pos
      KeSMSw6sAcsEntrySecRwLtStHdrstUpwdPos: parameter-require-com-spec{init-value=30, parameter=Pos/Val}, required-interface=Pos
      KeSMSw6sAcsEntrySecRwLtStHdrstUpwdPosMax: parameter-require-com-spec{init-value=4095, parameter=Pos/Val}, required-interface=Pos
      KeSMSw6sAcsEntrySecRwLtStHdrstUpwdPosMin: parameter-require-com-spec{init-value=4095, parameter=Pos/Val}, required-interface=Pos
      KeSMSw6sAcsEntrySecRwLtStLgrstUpwdPos: parameter-require-com-spec{init-value=4095, parameter=Pos/Val}, required-interface=Pos
      KeSMSw6sAcsEntrySecRwLtStLgrstUpwdPosMax: parameter-require-com-spec{init-value=40, parameter=Pos/Val}, required-interface=Pos
      KeSMSw6sAcsEntrySecRwLtStLgrstUpwdPosMin: parameter-require-com-spec{init-value=20, parameter=Pos/Val}, required-interface=Pos
      KeSMSw6sAcsEntrySecRwLtStLtwdRtwdPos: parameter-require-com-spec{init-value=0, parameter=Pos/Val}, required-interface=Pos
      KeSMSw6sAcsEntrySecRwLtStLtwdRtwdPosMax: parameter-require-com-spec{init-value=0, parameter=Pos/Val}, required-interface=Pos
      KeSMSw6sAcsEntrySecRwLtStLtwdRtwdPosMin: parameter-require-com-spec{init-value=0, parameter=Pos/Val}, required-interface=Pos
      KeSMSw6sAcsEntrySecRwRtStArmScrnPos: parameter-require-com-spec{init-value=0, parameter=Pos/Val}, required-interface=Pos
      KeSMSw6sAcsEntrySecRwRtStArmScrnPosMax: parameter-require-com-spec{init-value=0, parameter=Pos/Val}, required-interface=Pos
      KeSMSw6sAcsEntrySecRwRtStArmScrnPosMin: parameter-require-com-spec{init-value=0, parameter=Pos/Val}, required-interface=Pos
      KeSMSw6sAcsEntrySecRwRtStBkReclnUpwdDnwdPos: parameter-require-com-spec{init-value=1280, parameter=Pos/Val}, required-interface=Pos
      KeSMSw6sAcsEntrySecRwRtStBkReclnUpwdDnwdPosMax: parameter-require-com-spec{init-value=1280, parameter=Pos/Val}, required-interface=Pos
      KeSMSw6sAcsEntrySecRwRtStBkReclnUpwdDnwdPosMin: parameter-require-com-spec{init-value=0, parameter=Pos/Val}, required-interface=Pos
      KeSMSw6sAcsEntrySecRwRtStFrwdBkwdPos: parameter-require-com-spec{init-value=727, parameter=Pos/Val}, required-interface=Pos
      KeSMSw6sAcsEntrySecRwRtStFrwdBkwdPosMax: parameter-require-com-spec{init-value=727, parameter=Pos/Val}, required-interface=Pos
      KeSMSw6sAcsEntrySecRwRtStFrwdBkwdPosMin: parameter-require-com-spec{init-value=727, parameter=Pos/Val}, required-interface=Pos
      KeSMSw6sAcsEntrySecRwRtStHdrstUpwdPos: parameter-require-com-spec{init-value=4095, parameter=Pos/Val}, required-interface=Pos
      KeSMSw6sAcsEntrySecRwRtStHdrstUpwdPosMax: parameter-require-com-spec{init-value=4095, parameter=Pos/Val}, required-interface=Pos
      KeSMSw6sAcsEntrySecRwRtStHdrstUpwdPosMin: parameter-require-com-spec{init-value=4095, parameter=Pos/Val}, required-interface=Pos
      KeSMSw6sAcsEntrySecRwRtStLgrstUpwdPos: parameter-require-com-spec{init-value=0, parameter=Pos/Val}, required-interface=Pos
      KeSMSw6sAcsEntrySecRwRtStLgrstUpwdPosMax: parameter-require-com-spec{init-value=0, parameter=Pos/Val}, required-interface=Pos
      KeSMSw6sAcsEntrySecRwRtStLgrstUpwdPosMin: parameter-require-com-spec{init-value=0, parameter=Pos/Val}, required-interface=Pos
      KeSMSw6sAcsEntrySecRwRtStLtwdRtwdPos: parameter-require-com-spec{init-value=4000, parameter=Pos/Val}, required-interface=Pos
      KeSMSw6sAcsEntrySecRwRtStLtwdRtwdPosMax: parameter-require-com-spec{init-value=4000, parameter=Pos/Val}, required-interface=Pos
      KeSMSw6sAcsEntrySecRwRtStLtwdRtwdPosMin: parameter-require-com-spec{init-value=4000, parameter=Pos/Val}, required-interface=Pos
      KeSMSw6sAcsEntryThdRwLtStBkReclnUpwdDnwdPos: parameter-require-com-spec{init-value=2080, parameter=Pos/Val}, required-interface=Pos
      KeSMSw6sAcsEntryThdRwLtStBkReclnUpwdDnwdPosMax: parameter-require-com-spec{init-value=2095, parameter=Pos/Val}, required-interface=Pos
      KeSMSw6sAcsEntryThdRwLtStBkReclnUpwdDnwdPosMin: parameter-require-com-spec{init-value=0, parameter=Pos/Val}, required-interface=Pos
      KeSMSw6sAcsEntryThdRwLtStCshnFldUpwdDnwdPos: parameter-require-com-spec{init-value=0, parameter=Pos/Val}, required-interface=Pos
      KeSMSw6sAcsEntryThdRwLtStCshnFldUpwdDnwdPosMax: parameter-require-com-spec{init-value=0, parameter=Pos/Val}, required-interface=Pos
      KeSMSw6sAcsEntryThdRwLtStCshnFldUpwdDnwdPosMin: parameter-require-com-spec{init-value=0, parameter=Pos/Val}, required-interface=Pos
      KeSMSw6sAcsEntryThdRwLtStFrwdBkwdPos: parameter-require-com-spec{init-value=2760, parameter=Pos/Val}, required-interface=Pos
      KeSMSw6sAcsEntryThdRwLtStFrwdBkwdPosMax: parameter-require-com-spec{init-value=4000, parameter=Pos/Val}, required-interface=Pos
      KeSMSw6sAcsEntryThdRwLtStFrwdBkwdPosMin: parameter-require-com-spec{init-value=2760, parameter=Pos/Val}, required-interface=Pos
      KeSMSw6sAcsEntryThdRwRtStBkReclnUpwdDnwdPos: parameter-require-com-spec{init-value=2080, parameter=Pos/Val}, required-interface=Pos
      KeSMSw6sAcsEntryThdRwRtStBkReclnUpwdDnwdPosMax: parameter-require-com-spec{init-value=2095, parameter=Pos/Val}, required-interface=Pos
      KeSMSw6sAcsEntryThdRwRtStBkReclnUpwdDnwdPosMin: parameter-require-com-spec{init-value=2080, parameter=Pos/Val}, required-interface=Pos
      KeSMSw6sAcsEntryThdRwRtStCshnFldUpwdDnwdPos: parameter-require-com-spec{init-value=0, parameter=Pos/Val}, required-interface=Pos
      KeSMSw6sAcsEntryThdRwRtStCshnFldUpwdDnwdPosMax: parameter-require-com-spec{init-value=0, parameter=Pos/Val}, required-interface=Pos
      KeSMSw6sAcsEntryThdRwRtStCshnFldUpwdDnwdPosMin: parameter-require-com-spec{init-value=0, parameter=Pos/Val}, required-interface=Pos
      KeSMSw6sAcsEntryThdRwRtStFrwdBkwdPos: parameter-require-com-spec{init-value=2760, parameter=Pos/Val}, required-interface=Pos
      KeSMSw6sAcsEntryThdRwRtStFrwdBkwdPosMax: parameter-require-com-spec{init-value=4000, parameter=Pos/Val}, required-interface=Pos
      KeSMSw6sAcsEntryThdRwRtStFrwdBkwdPosMin: parameter-require-com-spec{init-value=2760, parameter=Pos/Val}, required-interface=Pos
      KeSMSw6sAcsExtDrvStBkReclnUpwdDnwdPos: parameter-require-com-spec{init-value=1840, parameter=Pos/Val}, required-interface=Pos
      KeSMSw6sAcsExtDrvStBkReclnUpwdDnwdPosMax: parameter-require-com-spec{init-value=1840, parameter=Pos/Val}, required-interface=Pos
      KeSMSw6sAcsExtDrvStBkReclnUpwdDnwdPosMin: parameter-require-com-spec{init-value=0, parameter=Pos/Val}, required-interface=Pos
      KeSMSw6sAcsExtDrvStFrwdBkwdPos: parameter-require-com-spec{init-value=2880, parameter=Pos/Val}, required-interface=Pos
      KeSMSw6sAcsExtDrvStFrwdBkwdPosMax: parameter-require-com-spec{init-value=2880, parameter=Pos/Val}, required-interface=Pos
      KeSMSw6sAcsExtDrvStFrwdBkwdPosMin: parameter-require-com-spec{init-value=0, parameter=Pos/Val}, required-interface=Pos
      KeSMSw6sAcsExtDrvStFtUpwdDnwdPos: parameter-require-com-spec{init-value=0, parameter=Pos/Val}, required-interface=Pos
      KeSMSw6sAcsExtDrvStFtUpwdDnwdPosMax: parameter-require-com-spec{init-value=0, parameter=Pos/Val}, required-interface=Pos
      KeSMSw6sAcsExtDrvStFtUpwdDnwdPosMin: parameter-require-com-spec{init-value=0, parameter=Pos/Val}, required-interface=Pos
      KeSMSw6sAcsExtPassStBkReclnUpwdDnwdPos: parameter-require-com-spec{init-value=1840, parameter=Pos/Val}, required-interface=Pos
      KeSMSw6sAcsExtPassStBkReclnUpwdDnwdPosMax: parameter-require-com-spec{init-value=1840, parameter=Pos/Val}, required-interface=Pos
      KeSMSw6sAcsExtPassStBkReclnUpwdDnwdPosMin: parameter-require-com-spec{init-value=0, parameter=Pos/Val}, required-interface=Pos
      KeSMSw6sAcsExtPassStFrwdBkwdPos: parameter-require-com-spec{init-value=3000, parameter=Pos/Val}, required-interface=Pos
      KeSMSw6sAcsExtPassStFrwdBkwdPosMax: parameter-require-com-spec{init-value=3167, parameter=Pos/Val}, required-interface=Pos
      KeSMSw6sAcsExtPassStFrwdBkwdPosMin: parameter-require-com-spec{init-value=0, parameter=Pos/Val}, required-interface=Pos
      KeSMSw6sAcsExtPassStFtUpwdDnwdPos: parameter-require-com-spec{init-value=0, parameter=Pos/Val}, required-interface=Pos
      KeSMSw6sAcsExtPassStFtUpwdDnwdPosMax: parameter-require-com-spec{init-value=0, parameter=Pos/Val}, required-interface=Pos
      KeSMSw6sAcsExtPassStFtUpwdDnwdPosMin: parameter-require-com-spec{init-value=0, parameter=Pos/Val}, required-interface=Pos
      KeSMSw6sAcsExtSecRwLtStArmScrnPos: parameter-require-com-spec{init-value=30, parameter=Pos/Val}, required-interface=Pos
      KeSMSw6sAcsExtSecRwLtStArmScrnPosMax: parameter-require-com-spec{init-value=40, parameter=Pos/Val}, required-interface=Pos
      KeSMSw6sAcsExtSecRwLtStArmScrnPosMin: parameter-require-com-spec{init-value=20, parameter=Pos/Val}, required-interface=Pos
      KeSMSw6sAcsExtSecRwLtStBkReclnUpwdDnwdPos: parameter-require-com-spec{init-value=1280, parameter=Pos/Val}, required-interface=Pos
      KeSMSw6sAcsExtSecRwLtStBkReclnUpwdDnwdPosMax: parameter-require-com-spec{init-value=1280, parameter=Pos/Val}, required-interface=Pos
      KeSMSw6sAcsExtSecRwLtStBkReclnUpwdDnwdPosMin: parameter-require-com-spec{init-value=0, parameter=Pos/Val}, required-interface=Pos
      KeSMSw6sAcsExtSecRwLtStFrwdBkwdPos: parameter-require-com-spec{init-value=727, parameter=Pos/Val}, required-interface=Pos
      KeSMSw6sAcsExtSecRwLtStFrwdBkwdPosMax: parameter-require-com-spec{init-value=727, parameter=Pos/Val}, required-interface=Pos
      KeSMSw6sAcsExtSecRwLtStFrwdBkwdPosMin: parameter-require-com-spec{init-value=727, parameter=Pos/Val}, required-interface=Pos
      KeSMSw6sAcsExtSecRwLtStLgrstUpwdDnwdPos: parameter-require-com-spec{init-value=0, parameter=Pos/Val}, required-interface=Pos
      KeSMSw6sAcsExtSecRwLtStLgrstUpwdDnwdPosMax: parameter-require-com-spec{init-value=0, parameter=Pos/Val}, required-interface=Pos
      KeSMSw6sAcsExtSecRwLtStLgrstUpwdDnwdPosMin: parameter-require-com-spec{init-value=0, parameter=Pos/Val}, required-interface=Pos
      KeSMSw6sAcsExtSecRwLtStLtwdRtwdPos: parameter-require-com-spec{init-value=0, parameter=Pos/Val}, required-interface=Pos
      KeSMSw6sAcsExtSecRwLtStLtwdRtwdPosMax: parameter-require-com-spec{init-value=0, parameter=Pos/Val}, required-interface=Pos
      KeSMSw6sAcsExtSecRwLtStLtwdRtwdPosMin: parameter-require-com-spec{init-value=0, parameter=Pos/Val}, required-interface=Pos
      KeSMSw6sAcsExtSecRwRtStArmScrnPos: parameter-require-com-spec{init-value=0, parameter=Pos/Val}, required-interface=Pos
      KeSMSw6sAcsExtSecRwRtStArmScrnPosMax: parameter-require-com-spec{init-value=0, parameter=Pos/Val}, required-interface=Pos
      KeSMSw6sAcsExtSecRwRtStArmScrnPosMin: parameter-require-com-spec{init-value=0, parameter=Pos/Val}, required-interface=Pos
      KeSMSw6sAcsExtSecRwRtStBkReclnUpwdDnwdPos: parameter-require-com-spec{init-value=1280, parameter=Pos/Val}, required-interface=Pos
      KeSMSw6sAcsExtSecRwRtStBkReclnUpwdDnwdPosMax: parameter-require-com-spec{init-value=1280, parameter=Pos/Val}, required-interface=Pos
      KeSMSw6sAcsExtSecRwRtStBkReclnUpwdDnwdPosMin: parameter-require-com-spec{init-value=0, parameter=Pos/Val}, required-interface=Pos
      KeSMSw6sAcsExtSecRwRtStFrwdBkwdPos: parameter-require-com-spec{init-value=727, parameter=Pos/Val}, required-interface=Pos
      KeSMSw6sAcsExtSecRwRtStFrwdBkwdPosMax: parameter-require-com-spec{init-value=727, parameter=Pos/Val}, required-interface=Pos
      KeSMSw6sAcsExtSecRwRtStFrwdBkwdPosMin: parameter-require-com-spec{init-value=727, parameter=Pos/Val}, required-interface=Pos
      KeSMSw6sAcsExtSecRwRtStLgrstUpwdDnwdPos: parameter-require-com-spec{init-value=0, parameter=Pos/Val}, required-interface=Pos
      KeSMSw6sAcsExtSecRwRtStLgrstUpwdDnwdPosMax: parameter-require-com-spec{init-value=0, parameter=Pos/Val}, required-interface=Pos
      KeSMSw6sAcsExtSecRwRtStLgrstUpwdDnwdPosMin: parameter-require-com-spec{init-value=0, parameter=Pos/Val}, required-interface=Pos
      KeSMSw6sAcsExtSecRwRtStLtwdRtwdPos: parameter-require-com-spec{init-value=4000, parameter=Pos/Val}, required-interface=Pos
      KeSMSw6sAcsExtSecRwRtStLtwdRtwdPosMax: parameter-require-com-spec{init-value=4000, parameter=Pos/Val}, required-interface=Pos
      KeSMSw6sAcsExtSecRwRtStLtwdRtwdPosMin: parameter-require-com-spec{init-value=4000, parameter=Pos/Val}, required-interface=Pos
      KeSMSw6sAcsExtThdRwLtStBkReclnUpwdDnwdPos: parameter-require-com-spec{init-value=30, parameter=Pos/Val}, required-interface=Pos
      KeSMSw6sAcsExtThdRwLtStBkReclnUpwdDnwdPosMax: parameter-require-com-spec{init-value=40, parameter=Pos/Val}, required-interface=Pos
      KeSMSw6sAcsExtThdRwLtStBkReclnUpwdDnwdPosMin: parameter-require-com-spec{init-value=20, parameter=Pos/Val}, required-interface=Pos
      KeSMSw6sAcsExtThdRwLtStCshnFldUpwdDnwdPos: parameter-require-com-spec{init-value=30, parameter=Pos/Val}, required-interface=Pos
      KeSMSw6sAcsExtThdRwLtStCshnFldUpwdDnwdPosMax: parameter-require-com-spec{init-value=40, parameter=Pos/Val}, required-interface=Pos
      KeSMSw6sAcsExtThdRwLtStCshnFldUpwdDnwdPosMin: parameter-require-com-spec{init-value=20, parameter=Pos/Val}, required-interface=Pos
      KeSMSw6sAcsExtThdRwLtStFrwdBkwdPos: parameter-require-com-spec{init-value=30, parameter=Pos/Val}, required-interface=Pos
      KeSMSw6sAcsExtThdRwLtStFrwdBkwdPosMax: parameter-require-com-spec{init-value=40, parameter=Pos/Val}, required-interface=Pos
      KeSMSw6sAcsExtThdRwLtStFrwdBkwdPosMin: parameter-require-com-spec{init-value=20, parameter=Pos/Val}, required-interface=Pos
      KeSMSw6sAcsExtThdRwRtStBkReclnUpwdDnwdPos: parameter-require-com-spec{init-value=30, parameter=Pos/Val}, required-interface=Pos
      KeSMSw6sAcsExtThdRwRtStBkReclnUpwdDnwdPosMax: parameter-require-com-spec{init-value=40, parameter=Pos/Val}, required-interface=Pos
      KeSMSw6sAcsExtThdRwRtStBkReclnUpwdDnwdPosMin: parameter-require-com-spec{init-value=20, parameter=Pos/Val}, required-interface=Pos
      KeSMSw6sAcsExtThdRwRtStCshnFldUpwdDnwdPos: parameter-require-com-spec{init-value=4000, parameter=Pos/Val}, required-interface=Pos
      KeSMSw6sAcsExtThdRwRtStCshnFldUpwdDnwdPosMax: parameter-require-com-spec{init-value=4000, parameter=Pos/Val}, required-interface=Pos
      KeSMSw6sAcsExtThdRwRtStCshnFldUpwdDnwdPosMin: parameter-require-com-spec{init-value=4000, parameter=Pos/Val}, required-interface=Pos
      KeSMSw6sAcsExtThdRwRtStFrwdBkwdPos: parameter-require-com-spec{init-value=0, parameter=Pos/Val}, required-interface=Pos
      KeSMSw6sAcsExtThdRwRtStFrwdBkwdPosMax: parameter-require-com-spec{init-value=0, parameter=Pos/Val}, required-interface=Pos
      KeSMSw6sAcsExtThdRwRtStFrwdBkwdPosMin: parameter-require-com-spec{init-value=0, parameter=Pos/Val}, required-interface=Pos
      KeSMSw6sFamilyLMdThdRwLtStFrwdBkwdPos: parameter-require-com-spec{init-value=0, parameter=Pos/Val}, required-interface=Pos
      KeSMSw6sFamilyLMdThdRwLtStFrwdBkwdPosMax: parameter-require-com-spec{init-value=0, parameter=Pos/Val}, required-interface=Pos
      KeSMSw6sFamilyLMdThdRwLtStFrwdBkwdPosMin: parameter-require-com-spec{init-value=0, parameter=Pos/Val}, required-interface=Pos
      KeSMSw6sFamilyMdSecRwLtStFrwdBkwdPos: parameter-require-com-spec{init-value=0, parameter=Pos/Val}, required-interface=Pos
      KeSMSw6sFamilyMdSecRwLtStFrwdBkwdPosMax: parameter-require-com-spec{init-value=0, parameter=Pos/Val}, required-interface=Pos
      KeSMSw6sFamilyMdSecRwLtStFrwdBkwdPosMin: parameter-require-com-spec{init-value=0, parameter=Pos/Val}, required-interface=Pos
      KeSMSw6sFamilyMdSecRwLtStLtwdRtwdPos: parameter-require-com-spec{init-value=0, parameter=Pos/Val}, required-interface=Pos
      KeSMSw6sFamilyMdSecRwLtStLtwdRtwdPosMax: parameter-require-com-spec{init-value=0, parameter=Pos/Val}, required-interface=Pos
      KeSMSw6sFamilyMdSecRwLtStLtwdRtwdPosMin: parameter-require-com-spec{init-value=0, parameter=Pos/Val}, required-interface=Pos
      KeSMSw6sFamilyMdSecRwRtStFrwdBkwdPos: parameter-require-com-spec{init-value=0, parameter=Pos/Val}, required-interface=Pos
      KeSMSw6sFamilyMdSecRwRtStFrwdBkwdPosMax: parameter-require-com-spec{init-value=0, parameter=Pos/Val}, required-interface=Pos
      KeSMSw6sFamilyMdSecRwRtStFrwdBkwdPosMin: parameter-require-com-spec{init-value=0, parameter=Pos/Val}, required-interface=Pos
      KeSMSw6sFamilyMdSecRwRtStLtwdRtwdPos: parameter-require-com-spec{init-value=0, parameter=Pos/Val}, required-interface=Pos
      KeSMSw6sFamilyMdSecRwRtStLtwdRtwdPosMax: parameter-require-com-spec{init-value=0, parameter=Pos/Val}, required-interface=Pos
      KeSMSw6sFamilyMdSecRwRtStLtwdRtwdPosMin: parameter-require-com-spec{init-value=0, parameter=Pos/Val}, required-interface=Pos
      KeSMSw6sFamilyMdThdRwLtStFrwdBkwdPos: parameter-require-com-spec{init-value=0, parameter=Pos/Val}, required-interface=Pos
      KeSMSw6sFamilyMdThdRwLtStFrwdBkwdPosMax: parameter-require-com-spec{init-value=0, parameter=Pos/Val}, required-interface=Pos
      KeSMSw6sFamilyMdThdRwLtStFrwdBkwdPosMin: parameter-require-com-spec{init-value=0, parameter=Pos/Val}, required-interface=Pos
      KeSMSw6sFamilyMdThdRwRtStFrwdBkwdPos: parameter-require-com-spec{init-value=0, parameter=Pos/Val}, required-interface=Pos
      KeSMSw6sFamilyMdThdRwRtStFrwdBkwdPosMax: parameter-require-com-spec{init-value=0, parameter=Pos/Val}, required-interface=Pos
      KeSMSw6sFamilyMdThdRwRtStFrwdBkwdPosMin: parameter-require-com-spec{init-value=0, parameter=Pos/Val}, required-interface=Pos
      KeSMSw6sFamilyRMdSecRwLtStFrwdBkwdPos: parameter-require-com-spec{init-value=0, parameter=Pos/Val}, required-interface=Pos
      KeSMSw6sFamilyRMdSecRwLtStFrwdBkwdPosMax: parameter-require-com-spec{init-value=0, parameter=Pos/Val}, required-interface=Pos
      KeSMSw6sFamilyRMdSecRwLtStFrwdBkwdPosMin: parameter-require-com-spec{init-value=0, parameter=Pos/Val}, required-interface=Pos
      KeSMSw6sFamilyRMdSecRwLtStLtwdRtwdPos: parameter-require-com-spec{init-value=0, parameter=Pos/Val}, required-interface=Pos
      KeSMSw6sFamilyRMdSecRwLtStLtwdRtwdPosMax: parameter-require-com-spec{init-value=0, parameter=Pos/Val}, required-interface=Pos
      KeSMSw6sFamilyRMdSecRwLtStLtwdRtwdPosMin: parameter-require-com-spec{init-value=0, parameter=Pos/Val}, required-interface=Pos
      KeSMSw6sFamilyRMdSecRwRtStFrwdBkwdPos: parameter-require-com-spec{init-value=0, parameter=Pos/Val}, required-interface=Pos
      KeSMSw6sFamilyRMdSecRwRtStFrwdBkwdPosMax: parameter-require-com-spec{init-value=0, parameter=Pos/Val}, required-interface=Pos
      KeSMSw6sFamilyRMdSecRwRtStFrwdBkwdPosMin: parameter-require-com-spec{init-value=0, parameter=Pos/Val}, required-interface=Pos
      KeSMSw6sFamilyRMdSecRwRtStLtwdRtwdPos: parameter-require-com-spec{init-value=0, parameter=Pos/Val}, required-interface=Pos
      KeSMSw6sFamilyRMdSecRwRtStLtwdRtwdPosMax: parameter-require-com-spec{init-value=0, parameter=Pos/Val}, required-interface=Pos
      KeSMSw6sFamilyRMdSecRwRtStLtwdRtwdPosMin: parameter-require-com-spec{init-value=0, parameter=Pos/Val}, required-interface=Pos
      KeSMSw6sFamilyRMdThdRwRtStFrwdBkwdPos: parameter-require-com-spec{init-value=0, parameter=Pos/Val}, required-interface=Pos
      KeSMSw6sFamilyRMdThdRwRtStFrwdBkwdPosMax: parameter-require-com-spec{init-value=0, parameter=Pos/Val}, required-interface=Pos
      KeSMSw6sFamilyRMdThdRwRtStFrwdBkwdPosMin: parameter-require-com-spec{init-value=0, parameter=Pos/Val}, required-interface=Pos
      KeSMSw6sIntimacyMdSecRwLtStLtwdRtwdPos: parameter-require-com-spec{init-value=0, parameter=Pos/Val}, required-interface=Pos
      KeSMSw6sIntimacyMdSecRwLtStLtwdRtwdPosMax: parameter-require-com-spec{init-value=0, parameter=Pos/Val}, required-interface=Pos
      KeSMSw6sIntimacyMdSecRwLtStLtwdRtwdPosMin: parameter-require-com-spec{init-value=0, parameter=Pos/Val}, required-interface=Pos
      KeSMSw6sIntimacyMdSecRwRtStLtwdRtwdPos: parameter-require-com-spec{init-value=0, parameter=Pos/Val}, required-interface=Pos
      KeSMSw6sIntimacyMdSecRwRtStLtwdRtwdPosMax: parameter-require-com-spec{init-value=0, parameter=Pos/Val}, required-interface=Pos
      KeSMSw6sIntimacyMdSecRwRtStLtwdRtwdPosMin: parameter-require-com-spec{init-value=0, parameter=Pos/Val}, required-interface=Pos
      KeSMSw6sIntimacyRMdSecRwLtStLtwdRtwdPos: parameter-require-com-spec{init-value=0, parameter=Pos/Val}, required-interface=Pos
      KeSMSw6sIntimacyRMdSecRwLtStLtwdRtwdPosMax: parameter-require-com-spec{init-value=0, parameter=Pos/Val}, required-interface=Pos
      KeSMSw6sIntimacyRMdSecRwLtStLtwdRtwdPosMin: parameter-require-com-spec{init-value=0, parameter=Pos/Val}, required-interface=Pos
      KeSMSw6sIntimacyRMdSecRwRtStLtwdRtwdPos: parameter-require-com-spec{init-value=0, parameter=Pos/Val}, required-interface=Pos
      KeSMSw6sIntimacyRMdSecRwRtStLtwdRtwdPosMax: parameter-require-com-spec{init-value=0, parameter=Pos/Val}, required-interface=Pos
      KeSMSw6sIntimacyRMdSecRwRtStLtwdRtwdPosMin: parameter-require-com-spec{init-value=0, parameter=Pos/Val}, required-interface=Pos
      KeSMSw6sLugThdRwLtStBkReclnUpwdDnwdPos: parameter-require-com-spec{init-value=0, parameter=Pos/Val}, required-interface=Pos
      KeSMSw6sLugThdRwLtStBkReclnUpwdDnwdPosMax: parameter-require-com-spec{init-value=0, parameter=Pos/Val}, required-interface=Pos
      KeSMSw6sLugThdRwLtStBkReclnUpwdDnwdPosMin: parameter-require-com-spec{init-value=0, parameter=Pos/Val}, required-interface=Pos
      KeSMSw6sLugThdRwLtStCshnFldUpwdDnwdPos: parameter-require-com-spec{init-value=30, parameter=Pos/Val}, required-interface=Pos
      KeSMSw6sLugThdRwLtStCshnFldUpwdDnwdPosMax: parameter-require-com-spec{init-value=40, parameter=Pos/Val}, required-interface=Pos
      KeSMSw6sLugThdRwLtStCshnFldUpwdDnwdPosMin: parameter-require-com-spec{init-value=20, parameter=Pos/Val}, required-interface=Pos
      KeSMSw6sLugThdRwLtStFrwdBkwdPos: parameter-require-com-spec{init-value=30, parameter=Pos/Val}, required-interface=Pos
      KeSMSw6sLugThdRwLtStFrwdBkwdPosMax: parameter-require-com-spec{init-value=40, parameter=Pos/Val}, required-interface=Pos
      KeSMSw6sLugThdRwLtStFrwdBkwdPosMin: parameter-require-com-spec{init-value=20, parameter=Pos/Val}, required-interface=Pos
      KeSMSw6sLugThdRwRtStBkReclnUpwdDnwdPos: parameter-require-com-spec{init-value=0, parameter=Pos/Val}, required-interface=Pos
      KeSMSw6sLugThdRwRtStBkReclnUpwdDnwdPosMax: parameter-require-com-spec{init-value=0, parameter=Pos/Val}, required-interface=Pos
      KeSMSw6sLugThdRwRtStBkReclnUpwdDnwdPosMin: parameter-require-com-spec{init-value=0, parameter=Pos/Val}, required-interface=Pos
      KeSMSw6sLugThdRwRtStCshnFldUpwdDnwdPos: parameter-require-com-spec{init-value=4000, parameter=Pos/Val}, required-interface=Pos
      KeSMSw6sLugThdRwRtStCshnFldUpwdDnwdPosMax: parameter-require-com-spec{init-value=4000, parameter=Pos/Val}, required-interface=Pos
      KeSMSw6sLugThdRwRtStCshnFldUpwdDnwdPosMin: parameter-require-com-spec{init-value=4000, parameter=Pos/Val}, required-interface=Pos
      KeSMSw6sLugThdRwRtStFrwdBkwdPos: parameter-require-com-spec{init-value=0, parameter=Pos/Val}, required-interface=Pos
      KeSMSw6sLugThdRwRtStFrwdBkwdPosMax: parameter-require-com-spec{init-value=0, parameter=Pos/Val}, required-interface=Pos
      KeSMSw6sLugThdRwRtStFrwdBkwdPosMin: parameter-require-com-spec{init-value=0, parameter=Pos/Val}, required-interface=Pos
      KeSMSw6sRecoveryDrvStFtUpwdDnwdPos: parameter-require-com-spec{init-value=0, parameter=Pos/Val}, required-interface=Pos
      KeSMSw6sRecoveryDrvStFtUpwdDnwdPosMax: parameter-require-com-spec{init-value=0, parameter=Pos/Val}, required-interface=Pos
      KeSMSw6sRecoveryDrvStFtUpwdDnwdPosMin: parameter-require-com-spec{init-value=0, parameter=Pos/Val}, required-interface=Pos
      KeSMSw6sRecoveryMdSecRwLtStArmScrnPos: parameter-require-com-spec{init-value=4095, parameter=Pos/Val}, required-interface=Pos
      KeSMSw6sRecoveryMdSecRwLtStArmScrnPosMax: parameter-require-com-spec{init-value=4095, parameter=Pos/Val}, required-interface=Pos
      KeSMSw6sRecoveryMdSecRwLtStArmScrnPosMin: parameter-require-com-spec{init-value=4095, parameter=Pos/Val}, required-interface=Pos
      KeSMSw6sRecoveryMdSecRwLtStBkReclnUpwdDnwdPos: parameter-require-com-spec{init-value=1268, parameter=Pos/Val}, required-interface=Pos
      KeSMSw6sRecoveryMdSecRwLtStBkReclnUpwdDnwdPosMax: parameter-require-com-spec{init-value=1268, parameter=Pos/Val}, required-interface=Pos
      KeSMSw6sRecoveryMdSecRwLtStBkReclnUpwdDnwdPosMin: parameter-require-com-spec{init-value=0, parameter=Pos/Val}, required-interface=Pos
      KeSMSw6sRecoveryMdSecRwLtStFrwdBkwdPos: parameter-require-com-spec{init-value=30, parameter=Pos/Val}, required-interface=Pos
      KeSMSw6sRecoveryMdSecRwLtStFrwdBkwdPosMax: parameter-require-com-spec{init-value=40, parameter=Pos/Val}, required-interface=Pos
      KeSMSw6sRecoveryMdSecRwLtStFrwdBkwdPosMin: parameter-require-com-spec{init-value=20, parameter=Pos/Val}, required-interface=Pos
      KeSMSw6sRecoveryMdSecRwLtStHdrstUpwdDnwdPos: parameter-require-com-spec{init-value=30, parameter=Pos/Val}, required-interface=Pos
      KeSMSw6sRecoveryMdSecRwLtStHdrstUpwdDnwdPosMax: parameter-require-com-spec{init-value=40, parameter=Pos/Val}, required-interface=Pos
      KeSMSw6sRecoveryMdSecRwLtStHdrstUpwdDnwdPosMin: parameter-require-com-spec{init-value=20, parameter=Pos/Val}, required-interface=Pos
      KeSMSw6sRecoveryMdSecRwLtStLgrstUpwdDnwdPos: parameter-require-com-spec{init-value=0, parameter=Pos/Val}, required-interface=Pos
      KeSMSw6sRecoveryMdSecRwLtStLgrstUpwdDnwdPosMax: parameter-require-com-spec{init-value=0, parameter=Pos/Val}, required-interface=Pos
      KeSMSw6sRecoveryMdSecRwLtStLgrstUpwdDnwdPosMin: parameter-require-com-spec{init-value=0, parameter=Pos/Val}, required-interface=Pos
      KeSMSw6sRecoveryMdSecRwLtStLtwdRtwdPos: parameter-require-com-spec{init-value=30, parameter=Pos/Val}, required-interface=Pos
      KeSMSw6sRecoveryMdSecRwLtStLtwdRtwdPosMax: parameter-require-com-spec{init-value=40, parameter=Pos/Val}, required-interface=Pos
      KeSMSw6sRecoveryMdSecRwLtStLtwdRtwdPosMin: parameter-require-com-spec{init-value=20, parameter=Pos/Val}, required-interface=Pos
      KeSMSw6sRecoveryMdSecRwRtStArmScrnPos: parameter-require-com-spec{init-value=30, parameter=Pos/Val}, required-interface=Pos
      KeSMSw6sRecoveryMdSecRwRtStArmScrnPosMax: parameter-require-com-spec{init-value=40, parameter=Pos/Val}, required-interface=Pos
      KeSMSw6sRecoveryMdSecRwRtStArmScrnPosMin: parameter-require-com-spec{init-value=20, parameter=Pos/Val}, required-interface=Pos
      KeSMSw6sRecoveryMdSecRwRtStBkReclnUpwdDnwdPos: parameter-require-com-spec{init-value=1268, parameter=Pos/Val}, required-interface=Pos
      KeSMSw6sRecoveryMdSecRwRtStBkReclnUpwdDnwdPosMax: parameter-require-com-spec{init-value=1268, parameter=Pos/Val}, required-interface=Pos
      KeSMSw6sRecoveryMdSecRwRtStBkReclnUpwdDnwdPosMin: parameter-require-com-spec{init-value=0, parameter=Pos/Val}, required-interface=Pos
      KeSMSw6sRecoveryMdSecRwRtStFrwdBkwdPos: parameter-require-com-spec{init-value=30, parameter=Pos/Val}, required-interface=Pos
      KeSMSw6sRecoveryMdSecRwRtStFrwdBkwdPosMax: parameter-require-com-spec{init-value=40, parameter=Pos/Val}, required-interface=Pos
      KeSMSw6sRecoveryMdSecRwRtStFrwdBkwdPosMin: parameter-require-com-spec{init-value=20, parameter=Pos/Val}, required-interface=Pos
      KeSMSw6sRecoveryMdSecRwRtStHdrstUpwdDnwdPos: parameter-require-com-spec{init-value=30, parameter=Pos/Val}, required-interface=Pos
      KeSMSw6sRecoveryMdSecRwRtStHdrstUpwdDnwdPosMax: parameter-require-com-spec{init-value=40, parameter=Pos/Val}, required-interface=Pos
      KeSMSw6sRecoveryMdSecRwRtStHdrstUpwdDnwdPosMin: parameter-require-com-spec{init-value=20, parameter=Pos/Val}, required-interface=Pos
      KeSMSw6sRecoveryMdSecRwRtStLgrstUpwdDnwdPos: parameter-require-com-spec{init-value=0, parameter=Pos/Val}, required-interface=Pos
      KeSMSw6sRecoveryMdSecRwRtStLgrstUpwdDnwdPosMax: parameter-require-com-spec{init-value=0, parameter=Pos/Val}, required-interface=Pos
      KeSMSw6sRecoveryMdSecRwRtStLgrstUpwdDnwdPosMin: parameter-require-com-spec{init-value=0, parameter=Pos/Val}, required-interface=Pos
      KeSMSw6sRecoveryMdSecRwRtStLtwdRtwdPos: parameter-require-com-spec{init-value=30, parameter=Pos/Val}, required-interface=Pos
      KeSMSw6sRecoveryMdSecRwRtStLtwdRtwdPosMax: parameter-require-com-spec{init-value=40, parameter=Pos/Val}, required-interface=Pos
      KeSMSw6sRecoveryMdSecRwRtStLtwdRtwdPosMin: parameter-require-com-spec{init-value=20, parameter=Pos/Val}, required-interface=Pos
      KeSMSw6sRecoveryPassStStFtUpwdDnwdPos: parameter-require-com-spec{init-value=0, parameter=Pos/Val}, required-interface=Pos
      KeSMSw6sRecoveryPassStStFtUpwdDnwdPosMax: parameter-require-com-spec{init-value=0, parameter=Pos/Val}, required-interface=Pos
      KeSMSw6sRecoveryPassStStFtUpwdDnwdPosMin: parameter-require-com-spec{init-value=0, parameter=Pos/Val}, required-interface=Pos
      KeSMSw6sVIPMDDrvStFtUpwdDnwdPos: parameter-require-com-spec{init-value=0, parameter=Pos/Val}, required-interface=Pos
      KeSMSw6sVIPMDDrvStFtUpwdDnwdPosMax: parameter-require-com-spec{init-value=0, parameter=Pos/Val}, required-interface=Pos
      KeSMSw6sVIPMDDrvStFtUpwdDnwdPosMin: parameter-require-com-spec{init-value=0, parameter=Pos/Val}, required-interface=Pos
      KeSMSw6sVIPMDPassStStFtUpwdDnwdPos: parameter-require-com-spec{init-value=0, parameter=Pos/Val}, required-interface=Pos
      KeSMSw6sVIPMDPassStStFtUpwdDnwdPosMax: parameter-require-com-spec{init-value=0, parameter=Pos/Val}, required-interface=Pos
      KeSMSw6sVIPMDPassStStFtUpwdDnwdPosMin: parameter-require-com-spec{init-value=0, parameter=Pos/Val}, required-interface=Pos
      KeSMSw6sVIPSecRwLtStArmScrnPos: parameter-require-com-spec{init-value=30, parameter=Pos/Val}, required-interface=Pos
      KeSMSw6sVIPSecRwLtStArmScrnPosMax: parameter-require-com-spec{init-value=40, parameter=Pos/Val}, required-interface=Pos
      KeSMSw6sVIPSecRwLtStArmScrnPosMin: parameter-require-com-spec{init-value=20, parameter=Pos/Val}, required-interface=Pos
      KeSMSw6sVIPSecRwLtStBkReclnUpwdDnwdPos: parameter-require-com-spec{init-value=1960, parameter=Pos/Val}, required-interface=Pos
      KeSMSw6sVIPSecRwLtStBkReclnUpwdDnwdPosMax: parameter-require-com-spec{init-value=1960, parameter=Pos/Val}, required-interface=Pos
      KeSMSw6sVIPSecRwLtStBkReclnUpwdDnwdPosMin: parameter-require-com-spec{init-value=1960, parameter=Pos/Val}, required-interface=Pos
      KeSMSw6sVIPSecRwLtStFrwdBkwdPos: parameter-require-com-spec{init-value=2920, parameter=Pos/Val}, required-interface=Pos
      KeSMSw6sVIPSecRwLtStFrwdBkwdPosMax: parameter-require-com-spec{init-value=2920, parameter=Pos/Val}, required-interface=Pos
      KeSMSw6sVIPSecRwLtStFrwdBkwdPosMin: parameter-require-com-spec{init-value=2920, parameter=Pos/Val}, required-interface=Pos
      KeSMSw6sVIPSecRwLtStHdrstUpwdPos: parameter-require-com-spec{init-value=30, parameter=Pos/Val}, required-interface=Pos
      KeSMSw6sVIPSecRwLtStHdrstUpwdPosMax: parameter-require-com-spec{init-value=40, parameter=Pos/Val}, required-interface=Pos
      KeSMSw6sVIPSecRwLtStHdrstUpwdPosMin: parameter-require-com-spec{init-value=20, parameter=Pos/Val}, required-interface=Pos
      KeSMSw6sVIPSecRwLtStLgrstUpwdPos: parameter-require-com-spec{init-value=4000, parameter=Pos/Val}, required-interface=Pos
      KeSMSw6sVIPSecRwLtStLgrstUpwdPosMax: parameter-require-com-spec{init-value=4000, parameter=Pos/Val}, required-interface=Pos
      KeSMSw6sVIPSecRwLtStLgrstUpwdPosMin: parameter-require-com-spec{init-value=4000, parameter=Pos/Val}, required-interface=Pos
      KeSMSw6sVIPSecRwLtStLtwdRtwdPos: parameter-require-com-spec{init-value=4000, parameter=Pos/Val}, required-interface=Pos
      KeSMSw6sVIPSecRwLtStLtwdRtwdPosMax: parameter-require-com-spec{init-value=4000, parameter=Pos/Val}, required-interface=Pos
      KeSMSw6sVIPSecRwLtStLtwdRtwdPosMin: parameter-require-com-spec{init-value=4000, parameter=Pos/Val}, required-interface=Pos
      KeSMSw6sVIPSecRwRtStArmScrnPos: parameter-require-com-spec{init-value=30, parameter=Pos/Val}, required-interface=Pos
      KeSMSw6sVIPSecRwRtStArmScrnPosMax: parameter-require-com-spec{init-value=40, parameter=Pos/Val}, required-interface=Pos
      KeSMSw6sVIPSecRwRtStArmScrnPosMin: parameter-require-com-spec{init-value=20, parameter=Pos/Val}, required-interface=Pos
      KeSMSw6sVIPSecRwRtStBkReclnUpwdDnwdPos: parameter-require-com-spec{init-value=1960, parameter=Pos/Val}, required-interface=Pos
      KeSMSw6sVIPSecRwRtStBkReclnUpwdDnwdPosMax: parameter-require-com-spec{init-value=40, parameter=Pos/Val}, required-interface=Pos
      KeSMSw6sVIPSecRwRtStBkReclnUpwdDnwdPosMin: parameter-require-com-spec{init-value=1960, parameter=Pos/Val}, required-interface=Pos
      KeSMSw6sVIPSecRwRtStFrwdBkwdPos: parameter-require-com-spec{init-value=2920, parameter=Pos/Val}, required-interface=Pos
      KeSMSw6sVIPSecRwRtStFrwdBkwdPosMax: parameter-require-com-spec{init-value=2920, parameter=Pos/Val}, required-interface=Pos
      KeSMSw6sVIPSecRwRtStFrwdBkwdPosMin: parameter-require-com-spec{init-value=2920, parameter=Pos/Val}, required-interface=Pos
      KeSMSw6sVIPSecRwRtStHdrstUpwdPos: parameter-require-com-spec{init-value=30, parameter=Pos/Val}, required-interface=Pos
      KeSMSw6sVIPSecRwRtStHdrstUpwdPosMax: parameter-require-com-spec{init-value=40, parameter=Pos/Val}, required-interface=Pos
      KeSMSw6sVIPSecRwRtStHdrstUpwdPosMin: parameter-require-com-spec{init-value=20, parameter=Pos/Val}, required-interface=Pos
      KeSMSw6sVIPSecRwRtStLgrstUpwdPos: parameter-require-com-spec{init-value=4000, parameter=Pos/Val}, required-interface=Pos
      KeSMSw6sVIPSecRwRtStLgrstUpwdPosMax: parameter-require-com-spec{init-value=4000, parameter=Pos/Val}, required-interface=Pos
      KeSMSw6sVIPSecRwRtStLgrstUpwdPosMin: parameter-require-com-spec{init-value=20, parameter=Pos/Val}, required-interface=Pos
      KeSMSw6sVIPSecRwRtStLtwdRtwdPos: parameter-require-com-spec{init-value=0, parameter=Pos/Val}, required-interface=Pos
      KeSMSw6sVIPSecRwRtStLtwdRtwdPosMax: parameter-require-com-spec{init-value=40, parameter=Pos/Val}, required-interface=Pos
      KeSMSw6sVIPSecRwRtStLtwdRtwdPosMin: parameter-require-com-spec{init-value=0, parameter=Pos/Val}, required-interface=Pos
      KeSMSw6sVIPThdRwLtStBkReclnUpwdDnwdPos: parameter-require-com-spec{init-value=0, parameter=Pos/Val}, required-interface=Pos
      KeSMSw6sVIPThdRwLtStBkReclnUpwdDnwdPosMax: parameter-require-com-spec{init-value=0, parameter=Pos/Val}, required-interface=Pos
      KeSMSw6sVIPThdRwLtStBkReclnUpwdDnwdPosMin: parameter-require-com-spec{init-value=0, parameter=Pos/Val}, required-interface=Pos
      KeSMSw6sVIPThdRwLtStCshnFldUpwdDnwdPos: parameter-require-com-spec{init-value=4000, parameter=Pos/Val}, required-interface=Pos
      KeSMSw6sVIPThdRwLtStCshnFldUpwdDnwdPosMax: parameter-require-com-spec{init-value=4000, parameter=Pos/Val}, required-interface=Pos
      KeSMSw6sVIPThdRwLtStCshnFldUpwdDnwdPosMin: parameter-require-com-spec{init-value=4000, parameter=Pos/Val}, required-interface=Pos
      KeSMSw6sVIPThdRwLtStFrwdBkwdPos: parameter-require-com-spec{init-value=4000, parameter=Pos/Val}, required-interface=Pos
      KeSMSw6sVIPThdRwLtStFrwdBkwdPosMax: parameter-require-com-spec{init-value=4000, parameter=Pos/Val}, required-interface=Pos
      KeSMSw6sVIPThdRwLtStFrwdBkwdPosMin: parameter-require-com-spec{init-value=4000, parameter=Pos/Val}, required-interface=Pos
      KeSMSw6sVIPThdRwRtStBkReclnUpwdDnwdPos: parameter-require-com-spec{init-value=0, parameter=Pos/Val}, required-interface=Pos
      KeSMSw6sVIPThdRwRtStBkReclnUpwdDnwdPosMax: parameter-require-com-spec{init-value=0, parameter=Pos/Val}, required-interface=Pos
      KeSMSw6sVIPThdRwRtStBkReclnUpwdDnwdPosMin: parameter-require-com-spec{init-value=0, parameter=Pos/Val}, required-interface=Pos
      KeSMSw6sVIPThdRwRtStCshnFldUpwdDnwdPos: parameter-require-com-spec{init-value=4000, parameter=Pos/Val}, required-interface=Pos
      KeSMSw6sVIPThdRwRtStCshnFldUpwdDnwdPosMax: parameter-require-com-spec{init-value=40, parameter=Pos/Val}, required-interface=Pos
      KeSMSw6sVIPThdRwRtStCshnFldUpwdDnwdPosMin: parameter-require-com-spec{init-value=4000, parameter=Pos/Val}, required-interface=Pos
      KeSMSw6sVIPThdRwRtStFrwdBkwdPos: parameter-require-com-spec{init-value=4000, parameter=Pos/Val}, required-interface=Pos
      KeSMSw6sVIPThdRwRtStFrwdBkwdPosMax: parameter-require-com-spec{init-value=4000, parameter=Pos/Val}, required-interface=Pos
      KeSMSw6sVIPThdRwRtStFrwdBkwdPosMin: parameter-require-com-spec{init-value=4000, parameter=Pos/Val}, required-interface=Pos
      KeSMSwAcsEntryDrvStBkReclnUpwdDnwdPos: parameter-require-com-spec{init-value=1840, parameter=Pos/Val}, required-interface=Pos
      KeSMSwAcsEntryDrvStBkReclnUpwdDnwdPosMax: parameter-require-com-spec{init-value=1840, parameter=Pos/Val}, required-interface=Pos
      KeSMSwAcsEntryDrvStBkReclnUpwdDnwdPosMin: parameter-require-com-spec{init-value=0, parameter=Pos/Val}, required-interface=Pos
      KeSMSwAcsEntryDrvStFrwdBkwdPos: parameter-require-com-spec{init-value=2880, parameter=Pos/Val}, required-interface=Pos
      KeSMSwAcsEntryDrvStFrwdBkwdPosMax: parameter-require-com-spec{init-value=2880, parameter=Pos/Val}, required-interface=Pos
      KeSMSwAcsEntryDrvStFrwdBkwdPosMin: parameter-require-com-spec{init-value=0, parameter=Pos/Val}, required-interface=Pos
      KeSMSwAcsEntryDrvStFtUpwdDnwdPos: parameter-require-com-spec{init-value=0, parameter=Pos/Val}, required-interface=Pos
      KeSMSwAcsEntryDrvStFtUpwdDnwdPosMax: parameter-require-com-spec{init-value=0, parameter=Pos/Val}, required-interface=Pos
      KeSMSwAcsEntryDrvStFtUpwdDnwdPosMin: parameter-require-com-spec{init-value=0, parameter=Pos/Val}, required-interface=Pos
      KeSMSwAcsEntryPassStBkReclnUpwdDnwdPos: parameter-require-com-spec{init-value=1840, parameter=Pos/Val}, required-interface=Pos
      KeSMSwAcsEntryPassStBkReclnUpwdDnwdPosMax: parameter-require-com-spec{init-value=1840, parameter=Pos/Val}, required-interface=Pos
      KeSMSwAcsEntryPassStBkReclnUpwdDnwdPosMin: parameter-require-com-spec{init-value=0, parameter=Pos/Val}, required-interface=Pos
      KeSMSwAcsEntryPassStFrwdBkwdPos: parameter-require-com-spec{init-value=3000, parameter=Pos/Val}, required-interface=Pos
      KeSMSwAcsEntryPassStFrwdBkwdPosMax: parameter-require-com-spec{init-value=3167, parameter=Pos/Val}, required-interface=Pos
      KeSMSwAcsEntryPassStFrwdBkwdPosMin: parameter-require-com-spec{init-value=0, parameter=Pos/Val}, required-interface=Pos
      KeSMSwAcsEntryPassStFtUpwdDnwdPos: parameter-require-com-spec{init-value=0, parameter=Pos/Val}, required-interface=Pos
      KeSMSwAcsEntryPassStFtUpwdDnwdPosMiax: parameter-require-com-spec{init-value=0, parameter=Pos/Val}, required-interface=Pos
      KeSMSwAcsEntryPassStFtUpwdDnwdPosMin: parameter-require-com-spec{init-value=0, parameter=Pos/Val}, required-interface=Pos
      KeSMSwAcsEntrySecRwLtStArmScrnPos: parameter-require-com-spec{init-value=0, parameter=Pos/Val}, required-interface=Pos
      KeSMSwAcsEntrySecRwLtStArmScrnPosMax: parameter-require-com-spec{init-value=0, parameter=Pos/Val}, required-interface=Pos
      KeSMSwAcsEntrySecRwLtStArmScrnPosMin: parameter-require-com-spec{init-value=0, parameter=Pos/Val}, required-interface=Pos
      KeSMSwAcsEntrySecRwLtStBkReclnUpwdDnwdPos: parameter-require-com-spec{init-value=1280, parameter=Pos/Val}, required-interface=Pos
      KeSMSwAcsEntrySecRwLtStBkReclnUpwdDnwdPosMax: parameter-require-com-spec{init-value=1280, parameter=Pos/Val}, required-interface=Pos
      KeSMSwAcsEntrySecRwLtStBkReclnUpwdDnwdPosMin: parameter-require-com-spec{init-value=0, parameter=Pos/Val}, required-interface=Pos
      KeSMSwAcsEntrySecRwLtStFrwdBkwdPos: parameter-require-com-spec{init-value=727, parameter=Pos/Val}, required-interface=Pos
      KeSMSwAcsEntrySecRwLtStFrwdBkwdPosMax: parameter-require-com-spec{init-value=727, parameter=Pos/Val}, required-interface=Pos
      KeSMSwAcsEntrySecRwLtStFrwdBkwdPosMin: parameter-require-com-spec{init-value=727, parameter=Pos/Val}, required-interface=Pos
      KeSMSwAcsEntrySecRwLtStHdrstUpwdPos: parameter-require-com-spec{init-value=30, parameter=Pos/Val}, required-interface=Pos
      KeSMSwAcsEntrySecRwLtStHdrstUpwdPosMax: parameter-require-com-spec{init-value=4095, parameter=Pos/Val}, required-interface=Pos
      KeSMSwAcsEntrySecRwLtStHdrstUpwdPosMin: parameter-require-com-spec{init-value=4095, parameter=Pos/Val}, required-interface=Pos
      KeSMSwAcsEntrySecRwLtStLgrstUpwdPos: parameter-require-com-spec{init-value=4095, parameter=Pos/Val}, required-interface=Pos
      KeSMSwAcsEntrySecRwLtStLgrstUpwdPosMax: parameter-require-com-spec{init-value=40, parameter=Pos/Val}, required-interface=Pos
      KeSMSwAcsEntrySecRwLtStLgrstUpwdPosMin: parameter-require-com-spec{init-value=20, parameter=Pos/Val}, required-interface=Pos
      KeSMSwAcsEntrySecRwLtStLtwdRtwdPos: parameter-require-com-spec{init-value=0, parameter=Pos/Val}, required-interface=Pos
      KeSMSwAcsEntrySecRwLtStLtwdRtwdPosMax: parameter-require-com-spec{init-value=0, parameter=Pos/Val}, required-interface=Pos
      KeSMSwAcsEntrySecRwLtStLtwdRtwdPosMin: parameter-require-com-spec{init-value=0, parameter=Pos/Val}, required-interface=Pos
      KeSMSwAcsEntrySecRwRtStArmScrnPos: parameter-require-com-spec{init-value=0, parameter=Pos/Val}, required-interface=Pos
      KeSMSwAcsEntrySecRwRtStArmScrnPosMax: parameter-require-com-spec{init-value=0, parameter=Pos/Val}, required-interface=Pos
      KeSMSwAcsEntrySecRwRtStArmScrnPosMin: parameter-require-com-spec{init-value=0, parameter=Pos/Val}, required-interface=Pos
      KeSMSwAcsEntrySecRwRtStBkReclnUpwdDnwdPos: parameter-require-com-spec{init-value=1280, parameter=Pos/Val}, required-interface=Pos
      KeSMSwAcsEntrySecRwRtStBkReclnUpwdDnwdPosMax: parameter-require-com-spec{init-value=1280, parameter=Pos/Val}, required-interface=Pos
      KeSMSwAcsEntrySecRwRtStBkReclnUpwdDnwdPosMin: parameter-require-com-spec{init-value=0, parameter=Pos/Val}, required-interface=Pos
      KeSMSwAcsEntrySecRwRtStFrwdBkwdPos: parameter-require-com-spec{init-value=727, parameter=Pos/Val}, required-interface=Pos
      KeSMSwAcsEntrySecRwRtStFrwdBkwdPosMax: parameter-require-com-spec{init-value=727, parameter=Pos/Val}, required-interface=Pos
      KeSMSwAcsEntrySecRwRtStFrwdBkwdPosMin: parameter-require-com-spec{init-value=727, parameter=Pos/Val}, required-interface=Pos
      KeSMSwAcsEntrySecRwRtStHdrstUpwdPos: parameter-require-com-spec{init-value=4095, parameter=Pos/Val}, required-interface=Pos
      KeSMSwAcsEntrySecRwRtStHdrstUpwdPosMax: parameter-require-com-spec{init-value=4095, parameter=Pos/Val}, required-interface=Pos
      KeSMSwAcsEntrySecRwRtStHdrstUpwdPosMin: parameter-require-com-spec{init-value=4095, parameter=Pos/Val}, required-interface=Pos
      KeSMSwAcsEntrySecRwRtStLgrstUpwdPos: parameter-require-com-spec{init-value=0, parameter=Pos/Val}, required-interface=Pos
      KeSMSwAcsEntrySecRwRtStLgrstUpwdPosMax: parameter-require-com-spec{init-value=0, parameter=Pos/Val}, required-interface=Pos
      KeSMSwAcsEntrySecRwRtStLgrstUpwdPosMin: parameter-require-com-spec{init-value=0, parameter=Pos/Val}, required-interface=Pos
      KeSMSwAcsEntrySecRwRtStLtwdRtwdPos: parameter-require-com-spec{init-value=4000, parameter=Pos/Val}, required-interface=Pos
      KeSMSwAcsEntrySecRwRtStLtwdRtwdPosMax: parameter-require-com-spec{init-value=4000, parameter=Pos/Val}, required-interface=Pos
      KeSMSwAcsEntrySecRwRtStLtwdRtwdPosMin: parameter-require-com-spec{init-value=4000, parameter=Pos/Val}, required-interface=Pos
      KeSMSwAcsEntryThdRwLtStBkReclnUpwdDnwdPos: parameter-require-com-spec{init-value=2080, parameter=Pos/Val}, required-interface=Pos
      KeSMSwAcsEntryThdRwLtStBkReclnUpwdDnwdPosMax: parameter-require-com-spec{init-value=2095, parameter=Pos/Val}, required-interface=Pos
      KeSMSwAcsEntryThdRwLtStBkReclnUpwdDnwdPosMin: parameter-require-com-spec{init-value=0, parameter=Pos/Val}, required-interface=Pos
      KeSMSwAcsEntryThdRwLtStCshnFldUpwdDnwdPos: parameter-require-com-spec{init-value=0, parameter=Pos/Val}, required-interface=Pos
      KeSMSwAcsEntryThdRwLtStCshnFldUpwdDnwdPosMax: parameter-require-com-spec{init-value=0, parameter=Pos/Val}, required-interface=Pos
      KeSMSwAcsEntryThdRwLtStCshnFldUpwdDnwdPosMin: parameter-require-com-spec{init-value=0, parameter=Pos/Val}, required-interface=Pos
      KeSMSwAcsEntryThdRwLtStFrwdBkwdPos: parameter-require-com-spec{init-value=2760, parameter=Pos/Val}, required-interface=Pos
      KeSMSwAcsEntryThdRwLtStFrwdBkwdPosMax: parameter-require-com-spec{init-value=4000, parameter=Pos/Val}, required-interface=Pos
      KeSMSwAcsEntryThdRwLtStFrwdBkwdPosMin: parameter-require-com-spec{init-value=2760, parameter=Pos/Val}, required-interface=Pos
      KeSMSwAcsEntryThdRwRtStBkReclnUpwdDnwdPos: parameter-require-com-spec{init-value=2080, parameter=Pos/Val}, required-interface=Pos
      KeSMSwAcsEntryThdRwRtStBkReclnUpwdDnwdPosMax: parameter-require-com-spec{init-value=2095, parameter=Pos/Val}, required-interface=Pos
      KeSMSwAcsEntryThdRwRtStBkReclnUpwdDnwdPosMin: parameter-require-com-spec{init-value=2080, parameter=Pos/Val}, required-interface=Pos
      KeSMSwAcsEntryThdRwRtStCshnFldUpwdDnwdPos: parameter-require-com-spec{init-value=0, parameter=Pos/Val}, required-interface=Pos
      KeSMSwAcsEntryThdRwRtStCshnFldUpwdDnwdPosMax: parameter-require-com-spec{init-value=0, parameter=Pos/Val}, required-interface=Pos
      KeSMSwAcsEntryThdRwRtStCshnFldUpwdDnwdPosMin: parameter-require-com-spec{init-value=0, parameter=Pos/Val}, required-interface=Pos
      KeSMSwAcsEntryThdRwRtStFrwdBkwdPos: parameter-require-com-spec{init-value=2760, parameter=Pos/Val}, required-interface=Pos
      KeSMSwAcsEntryThdRwRtStFrwdBkwdPosMax: parameter-require-com-spec{init-value=4000, parameter=Pos/Val}, required-interface=Pos
      KeSMSwAcsEntryThdRwRtStFrwdBkwdPosMin: parameter-require-com-spec{init-value=2760, parameter=Pos/Val}, required-interface=Pos
      KeSMSwAcsExtDrvStBkReclnUpwdDnwdPos: parameter-require-com-spec{init-value=1840, parameter=Pos/Val}, required-interface=Pos
      KeSMSwAcsExtDrvStBkReclnUpwdDnwdPosMax: parameter-require-com-spec{init-value=1840, parameter=Pos/Val}, required-interface=Pos
      KeSMSwAcsExtDrvStBkReclnUpwdDnwdPosMin: parameter-require-com-spec{init-value=0, parameter=Pos/Val}, required-interface=Pos
      KeSMSwAcsExtDrvStFrwdBkwdPos: parameter-require-com-spec{init-value=2880, parameter=Pos/Val}, required-interface=Pos
      KeSMSwAcsExtDrvStFrwdBkwdPosMax: parameter-require-com-spec{init-value=2880, parameter=Pos/Val}, required-interface=Pos
      KeSMSwAcsExtDrvStFrwdBkwdPosMin: parameter-require-com-spec{init-value=0, parameter=Pos/Val}, required-interface=Pos
      KeSMSwAcsExtDrvStFtUpwdDnwdPos: parameter-require-com-spec{init-value=0, parameter=Pos/Val}, required-interface=Pos
      KeSMSwAcsExtDrvStFtUpwdDnwdPosMax: parameter-require-com-spec{init-value=0, parameter=Pos/Val}, required-interface=Pos
      KeSMSwAcsExtDrvStFtUpwdDnwdPosMin: parameter-require-com-spec{init-value=0, parameter=Pos/Val}, required-interface=Pos
      KeSMSwAcsExtPassStBkReclnUpwdDnwdPos: parameter-require-com-spec{init-value=1840, parameter=Pos/Val}, required-interface=Pos
      KeSMSwAcsExtPassStBkReclnUpwdDnwdPosMax: parameter-require-com-spec{init-value=1840, parameter=Pos/Val}, required-interface=Pos
      KeSMSwAcsExtPassStBkReclnUpwdDnwdPosMin: parameter-require-com-spec{init-value=0, parameter=Pos/Val}, required-interface=Pos
      KeSMSwAcsExtPassStFrwdBkwdPos: parameter-require-com-spec{init-value=3000, parameter=Pos/Val}, required-interface=Pos
      KeSMSwAcsExtPassStFrwdBkwdPosMax: parameter-require-com-spec{init-value=3167, parameter=Pos/Val}, required-interface=Pos
      KeSMSwAcsExtPassStFrwdBkwdPosMin: parameter-require-com-spec{init-value=0, parameter=Pos/Val}, required-interface=Pos
      KeSMSwAcsExtPassStFtUpwdDnwdPos: parameter-require-com-spec{init-value=0, parameter=Pos/Val}, required-interface=Pos
      KeSMSwAcsExtPassStFtUpwdDnwdPosMax: parameter-require-com-spec{init-value=0, parameter=Pos/Val}, required-interface=Pos
      KeSMSwAcsExtPassStFtUpwdDnwdPosMin: parameter-require-com-spec{init-value=0, parameter=Pos/Val}, required-interface=Pos
      KeSMSwAcsExtSecRwLtStArmScrnPos: parameter-require-com-spec{init-value=30, parameter=Pos/Val}, required-interface=Pos
      KeSMSwAcsExtSecRwLtStArmScrnPosMax: parameter-require-com-spec{init-value=40, parameter=Pos/Val}, required-interface=Pos
      KeSMSwAcsExtSecRwLtStArmScrnPosMin: parameter-require-com-spec{init-value=20, parameter=Pos/Val}, required-interface=Pos
      KeSMSwAcsExtSecRwLtStBkReclnUpwdDnwdPos: parameter-require-com-spec{init-value=1280, parameter=Pos/Val}, required-interface=Pos
      KeSMSwAcsExtSecRwLtStBkReclnUpwdDnwdPosMax: parameter-require-com-spec{init-value=1280, parameter=Pos/Val}, required-interface=Pos
      KeSMSwAcsExtSecRwLtStBkReclnUpwdDnwdPosMin: parameter-require-com-spec{init-value=0, parameter=Pos/Val}, required-interface=Pos
      KeSMSwAcsExtSecRwLtStFrwdBkwdPos: parameter-require-com-spec{init-value=727, parameter=Pos/Val}, required-interface=Pos
      KeSMSwAcsExtSecRwLtStFrwdBkwdPosMax: parameter-require-com-spec{init-value=727, parameter=Pos/Val}, required-interface=Pos
      KeSMSwAcsExtSecRwLtStFrwdBkwdPosMin: parameter-require-com-spec{init-value=727, parameter=Pos/Val}, required-interface=Pos
      KeSMSwAcsExtSecRwLtStLgrstUpwdDnwdPos: parameter-require-com-spec{init-value=0, parameter=Pos/Val}, required-interface=Pos
      KeSMSwAcsExtSecRwLtStLgrstUpwdDnwdPosMax: parameter-require-com-spec{init-value=0, parameter=Pos/Val}, required-interface=Pos
      KeSMSwAcsExtSecRwLtStLgrstUpwdDnwdPosMin: parameter-require-com-spec{init-value=0, parameter=Pos/Val}, required-interface=Pos
      KeSMSwAcsExtSecRwLtStLtwdRtwdPos: parameter-require-com-spec{init-value=0, parameter=Pos/Val}, required-interface=Pos
      KeSMSwAcsExtSecRwLtStLtwdRtwdPosMax: parameter-require-com-spec{init-value=0, parameter=Pos/Val}, required-interface=Pos
      KeSMSwAcsExtSecRwLtStLtwdRtwdPosMin: parameter-require-com-spec{init-value=0, parameter=Pos/Val}, required-interface=Pos
      KeSMSwAcsExtSecRwRtStArmScrnPos: parameter-require-com-spec{init-value=0, parameter=Pos/Val}, required-interface=Pos
      KeSMSwAcsExtSecRwRtStArmScrnPosMax: parameter-require-com-spec{init-value=0, parameter=Pos/Val}, required-interface=Pos
      KeSMSwAcsExtSecRwRtStArmScrnPosMin: parameter-require-com-spec{init-value=0, parameter=Pos/Val}, required-interface=Pos
      KeSMSwAcsExtSecRwRtStBkReclnUpwdDnwdPos: parameter-require-com-spec{init-value=1280, parameter=Pos/Val}, required-interface=Pos
      KeSMSwAcsExtSecRwRtStBkReclnUpwdDnwdPosMax: parameter-require-com-spec{init-value=1280, parameter=Pos/Val}, required-interface=Pos
      KeSMSwAcsExtSecRwRtStBkReclnUpwdDnwdPosMin: parameter-require-com-spec{init-value=0, parameter=Pos/Val}, required-interface=Pos
      KeSMSwAcsExtSecRwRtStFrwdBkwdPos: parameter-require-com-spec{init-value=727, parameter=Pos/Val}, required-interface=Pos
      KeSMSwAcsExtSecRwRtStFrwdBkwdPosMax: parameter-require-com-spec{init-value=727, parameter=Pos/Val}, required-interface=Pos
      KeSMSwAcsExtSecRwRtStFrwdBkwdPosMin: parameter-require-com-spec{init-value=727, parameter=Pos/Val}, required-interface=Pos
      KeSMSwAcsExtSecRwRtStLgrstUpwdDnwdPos: parameter-require-com-spec{init-value=0, parameter=Pos/Val}, required-interface=Pos
      KeSMSwAcsExtSecRwRtStLgrstUpwdDnwdPosMax: parameter-require-com-spec{init-value=0, parameter=Pos/Val}, required-interface=Pos
      KeSMSwAcsExtSecRwRtStLgrstUpwdDnwdPosMin: parameter-require-com-spec{init-value=0, parameter=Pos/Val}, required-interface=Pos
      KeSMSwAcsExtSecRwRtStLtwdRtwdPos: parameter-require-com-spec{init-value=4000, parameter=Pos/Val}, required-interface=Pos
      KeSMSwAcsExtSecRwRtStLtwdRtwdPosMax: parameter-require-com-spec{init-value=4000, parameter=Pos/Val}, required-interface=Pos
      KeSMSwAcsExtSecRwRtStLtwdRtwdPosMin: parameter-require-com-spec{init-value=4000, parameter=Pos/Val}, required-interface=Pos
      KeSMSwAcsExtThdRwLtStBkReclnUpwdDnwdPos: parameter-require-com-spec{init-value=30, parameter=Pos/Val}, required-interface=Pos
      KeSMSwAcsExtThdRwLtStBkReclnUpwdDnwdPosMax: parameter-require-com-spec{init-value=40, parameter=Pos/Val}, required-interface=Pos
      KeSMSwAcsExtThdRwLtStBkReclnUpwdDnwdPosMin: parameter-require-com-spec{init-value=20, parameter=Pos/Val}, required-interface=Pos
      KeSMSwAcsExtThdRwLtStCshnFldUpwdDnwdPos: parameter-require-com-spec{init-value=30, parameter=Pos/Val}, required-interface=Pos
      KeSMSwAcsExtThdRwLtStCshnFldUpwdDnwdPosMax: parameter-require-com-spec{init-value=40, parameter=Pos/Val}, required-interface=Pos
      KeSMSwAcsExtThdRwLtStCshnFldUpwdDnwdPosMin: parameter-require-com-spec{init-value=20, parameter=Pos/Val}, required-interface=Pos
      KeSMSwAcsExtThdRwLtStFrwdBkwdPos: parameter-require-com-spec{init-value=30, parameter=Pos/Val}, required-interface=Pos
      KeSMSwAcsExtThdRwLtStFrwdBkwdPosMax: parameter-require-com-spec{init-value=40, parameter=Pos/Val}, required-interface=Pos
      KeSMSwAcsExtThdRwLtStFrwdBkwdPosMin: parameter-require-com-spec{init-value=20, parameter=Pos/Val}, required-interface=Pos
      KeSMSwAcsExtThdRwRtStBkReclnUpwdDnwdPos: parameter-require-com-spec{init-value=30, parameter=Pos/Val}, required-interface=Pos
      KeSMSwAcsExtThdRwRtStBkReclnUpwdDnwdPosMax: parameter-require-com-spec{init-value=40, parameter=Pos/Val}, required-interface=Pos
      KeSMSwAcsExtThdRwRtStBkReclnUpwdDnwdPosMin: parameter-require-com-spec{init-value=20, parameter=Pos/Val}, required-interface=Pos
      KeSMSwAcsExtThdRwRtStCshnFldUpwdDnwdPos: parameter-require-com-spec{init-value=4000, parameter=Pos/Val}, required-interface=Pos
      KeSMSwAcsExtThdRwRtStCshnFldUpwdDnwdPosMax: parameter-require-com-spec{init-value=4000, parameter=Pos/Val}, required-interface=Pos
      KeSMSwAcsExtThdRwRtStCshnFldUpwdDnwdPosMin: parameter-require-com-spec{init-value=4000, parameter=Pos/Val}, required-interface=Pos
      KeSMSwAcsExtThdRwRtStFrwdBkwdPos: parameter-require-com-spec{init-value=0, parameter=Pos/Val}, required-interface=Pos
      KeSMSwAcsExtThdRwRtStFrwdBkwdPosMax: parameter-require-com-spec{init-value=0, parameter=Pos/Val}, required-interface=Pos
      KeSMSwAcsExtThdRwRtStFrwdBkwdPosMin: parameter-require-com-spec{init-value=0, parameter=Pos/Val}, required-interface=Pos
      KeSMSwFamilyLMdThdRwLtStFrwdBkwdPos: parameter-require-com-spec{init-value=0, parameter=Pos/Val}, required-interface=Pos
      KeSMSwFamilyLMdThdRwLtStFrwdBkwdPosMax: parameter-require-com-spec{init-value=0, parameter=Pos/Val}, required-interface=Pos
      KeSMSwFamilyLMdThdRwLtStFrwdBkwdPosMin: parameter-require-com-spec{init-value=0, parameter=Pos/Val}, required-interface=Pos
      KeSMSwFamilyMdSecRwLtStFrwdBkwdPos: parameter-require-com-spec{init-value=0, parameter=Pos/Val}, required-interface=Pos
      KeSMSwFamilyMdSecRwLtStFrwdBkwdPosMax: parameter-require-com-spec{init-value=0, parameter=Pos/Val}, required-interface=Pos
      KeSMSwFamilyMdSecRwLtStFrwdBkwdPosMin: parameter-require-com-spec{init-value=0, parameter=Pos/Val}, required-interface=Pos
      KeSMSwFamilyMdSecRwLtStLtwdRtwdPos: parameter-require-com-spec{init-value=0, parameter=Pos/Val}, required-interface=Pos
      KeSMSwFamilyMdSecRwLtStLtwdRtwdPosMax: parameter-require-com-spec{init-value=0, parameter=Pos/Val}, required-interface=Pos
      KeSMSwFamilyMdSecRwLtStLtwdRtwdPosMin: parameter-require-com-spec{init-value=0, parameter=Pos/Val}, required-interface=Pos
      KeSMSwFamilyMdSecRwRtStFrwdBkwdPos: parameter-require-com-spec{init-value=0, parameter=Pos/Val}, required-interface=Pos
      KeSMSwFamilyMdSecRwRtStFrwdBkwdPosMax: parameter-require-com-spec{init-value=0, parameter=Pos/Val}, required-interface=Pos
      KeSMSwFamilyMdSecRwRtStFrwdBkwdPosMin: parameter-require-com-spec{init-value=0, parameter=Pos/Val}, required-interface=Pos
      KeSMSwFamilyMdSecRwRtStLtwdRtwdPos: parameter-require-com-spec{init-value=0, parameter=Pos/Val}, required-interface=Pos
      KeSMSwFamilyMdSecRwRtStLtwdRtwdPosMax: parameter-require-com-spec{init-value=0, parameter=Pos/Val}, required-interface=Pos
      KeSMSwFamilyMdSecRwRtStLtwdRtwdPosMin: parameter-require-com-spec{init-value=0, parameter=Pos/Val}, required-interface=Pos
      KeSMSwFamilyMdThdRwLtStFrwdBkwdPos: parameter-require-com-spec{init-value=0, parameter=Pos/Val}, required-interface=Pos
      KeSMSwFamilyMdThdRwLtStFrwdBkwdPosMax: parameter-require-com-spec{init-value=0, parameter=Pos/Val}, required-interface=Pos
      KeSMSwFamilyMdThdRwLtStFrwdBkwdPosMin: parameter-require-com-spec{init-value=0, parameter=Pos/Val}, required-interface=Pos
      KeSMSwFamilyMdThdRwRtStFrwdBkwdPos: parameter-require-com-spec{init-value=0, parameter=Pos/Val}, required-interface=Pos
      KeSMSwFamilyMdThdRwRtStFrwdBkwdPosMax: parameter-require-com-spec{init-value=0, parameter=Pos/Val}, required-interface=Pos
      KeSMSwFamilyMdThdRwRtStFrwdBkwdPosMin: parameter-require-com-spec{init-value=0, parameter=Pos/Val}, required-interface=Pos
      KeSMSwFamilyRMdSecRwLtStFrwdBkwdPos: parameter-require-com-spec{init-value=0, parameter=Pos/Val}, required-interface=Pos
      KeSMSwFamilyRMdSecRwLtStFrwdBkwdPosMax: parameter-require-com-spec{init-value=0, parameter=Pos/Val}, required-interface=Pos
      KeSMSwFamilyRMdSecRwLtStFrwdBkwdPosMin: parameter-require-com-spec{init-value=0, parameter=Pos/Val}, required-interface=Pos
      KeSMSwFamilyRMdSecRwLtStLtwdRtwdPos: parameter-require-com-spec{init-value=0, parameter=Pos/Val}, required-interface=Pos
      KeSMSwFamilyRMdSecRwLtStLtwdRtwdPosMax: parameter-require-com-spec{init-value=0, parameter=Pos/Val}, required-interface=Pos
      KeSMSwFamilyRMdSecRwLtStLtwdRtwdPosMin: parameter-require-com-spec{init-value=0, parameter=Pos/Val}, required-interface=Pos
      KeSMSwFamilyRMdSecRwRtStFrwdBkwdPos: parameter-require-com-spec{init-value=0, parameter=Pos/Val}, required-interface=Pos
      KeSMSwFamilyRMdSecRwRtStFrwdBkwdPosMax: parameter-require-com-spec{init-value=0, parameter=Pos/Val}, required-interface=Pos
      KeSMSwFamilyRMdSecRwRtStFrwdBkwdPosMin: parameter-require-com-spec{init-value=0, parameter=Pos/Val}, required-interface=Pos
      KeSMSwFamilyRMdSecRwRtStLtwdRtwdPos: parameter-require-com-spec{init-value=0, parameter=Pos/Val}, required-interface=Pos
      KeSMSwFamilyRMdSecRwRtStLtwdRtwdPosMax: parameter-require-com-spec{init-value=0, parameter=Pos/Val}, required-interface=Pos
      KeSMSwFamilyRMdSecRwRtStLtwdRtwdPosMin: parameter-require-com-spec{init-value=0, parameter=Pos/Val}, required-interface=Pos
      KeSMSwFamilyRMdThdRwRtStFrwdBkwdPos: parameter-require-com-spec{init-value=0, parameter=Pos/Val}, required-interface=Pos
      KeSMSwFamilyRMdThdRwRtStFrwdBkwdPosMax: parameter-require-com-spec{init-value=0, parameter=Pos/Val}, required-interface=Pos
      KeSMSwFamilyRMdThdRwRtStFrwdBkwdPosMin: parameter-require-com-spec{init-value=0, parameter=Pos/Val}, required-interface=Pos
      KeSMSwIntimacyMdSecRwLtStLtwdRtwdPos: parameter-require-com-spec{init-value=0, parameter=Pos/Val}, required-interface=Pos
      KeSMSwIntimacyMdSecRwLtStLtwdRtwdPosMax: parameter-require-com-spec{init-value=0, parameter=Pos/Val}, required-interface=Pos
      KeSMSwIntimacyMdSecRwLtStLtwdRtwdPosMin: parameter-require-com-spec{init-value=0, parameter=Pos/Val}, required-interface=Pos
      KeSMSwIntimacyMdSecRwRtStLtwdRtwdPos: parameter-require-com-spec{init-value=0, parameter=Pos/Val}, required-interface=Pos
      KeSMSwIntimacyMdSecRwRtStLtwdRtwdPosMax: parameter-require-com-spec{init-value=0, parameter=Pos/Val}, required-interface=Pos
      KeSMSwIntimacyMdSecRwRtStLtwdRtwdPosMin: parameter-require-com-spec{init-value=0, parameter=Pos/Val}, required-interface=Pos
      KeSMSwIntimacyRMdSecRwLtStLtwdRtwdPos: parameter-require-com-spec{init-value=0, parameter=Pos/Val}, required-interface=Pos
      KeSMSwIntimacyRMdSecRwLtStLtwdRtwdPosMax: parameter-require-com-spec{init-value=0, parameter=Pos/Val}, required-interface=Pos
      KeSMSwIntimacyRMdSecRwLtStLtwdRtwdPosMin: parameter-require-com-spec{init-value=0, parameter=Pos/Val}, required-interface=Pos
      KeSMSwIntimacyRMdSecRwRtStLtwdRtwdPos: parameter-require-com-spec{init-value=0, parameter=Pos/Val}, required-interface=Pos
      KeSMSwIntimacyRMdSecRwRtStLtwdRtwdPosMax: parameter-require-com-spec{init-value=0, parameter=Pos/Val}, required-interface=Pos
      KeSMSwIntimacyRMdSecRwRtStLtwdRtwdPosMin: parameter-require-com-spec{init-value=0, parameter=Pos/Val}, required-interface=Pos
      KeSMSwLugThdRwLtStBkReclnUpwdDnwdPos: parameter-require-com-spec{init-value=0, parameter=Pos/Val}, required-interface=Pos
      KeSMSwLugThdRwLtStBkReclnUpwdDnwdPosMax: parameter-require-com-spec{init-value=0, parameter=Pos/Val}, required-interface=Pos
      KeSMSwLugThdRwLtStBkReclnUpwdDnwdPosMin: parameter-require-com-spec{init-value=0, parameter=Pos/Val}, required-interface=Pos
      KeSMSwLugThdRwLtStCshnFldUpwdDnwdPos: parameter-require-com-spec{init-value=30, parameter=Pos/Val}, required-interface=Pos
      KeSMSwLugThdRwLtStCshnFldUpwdDnwdPosMax: parameter-require-com-spec{init-value=40, parameter=Pos/Val}, required-interface=Pos
      KeSMSwLugThdRwLtStCshnFldUpwdDnwdPosMin: parameter-require-com-spec{init-value=20, parameter=Pos/Val}, required-interface=Pos
      KeSMSwLugThdRwLtStFrwdBkwdPos: parameter-require-com-spec{init-value=30, parameter=Pos/Val}, required-interface=Pos
      KeSMSwLugThdRwLtStFrwdBkwdPosMax: parameter-require-com-spec{init-value=40, parameter=Pos/Val}, required-interface=Pos
      KeSMSwLugThdRwLtStFrwdBkwdPosMin: parameter-require-com-spec{init-value=20, parameter=Pos/Val}, required-interface=Pos
      KeSMSwLugThdRwRtStBkReclnUpwdDnwdPos: parameter-require-com-spec{init-value=0, parameter=Pos/Val}, required-interface=Pos
      KeSMSwLugThdRwRtStBkReclnUpwdDnwdPosMax: parameter-require-com-spec{init-value=0, parameter=Pos/Val}, required-interface=Pos
      KeSMSwLugThdRwRtStBkReclnUpwdDnwdPosMin: parameter-require-com-spec{init-value=0, parameter=Pos/Val}, required-interface=Pos
      KeSMSwLugThdRwRtStCshnFldUpwdDnwdPos: parameter-require-com-spec{init-value=4000, parameter=Pos/Val}, required-interface=Pos
      KeSMSwLugThdRwRtStCshnFldUpwdDnwdPosMax: parameter-require-com-spec{init-value=4000, parameter=Pos/Val}, required-interface=Pos
      KeSMSwLugThdRwRtStCshnFldUpwdDnwdPosMin: parameter-require-com-spec{init-value=4000, parameter=Pos/Val}, required-interface=Pos
      KeSMSwLugThdRwRtStFrwdBkwdPos: parameter-require-com-spec{init-value=0, parameter=Pos/Val}, required-interface=Pos
      KeSMSwLugThdRwRtStFrwdBkwdPosMax: parameter-require-com-spec{init-value=0, parameter=Pos/Val}, required-interface=Pos
      KeSMSwLugThdRwRtStFrwdBkwdPosMin: parameter-require-com-spec{init-value=0, parameter=Pos/Val}, required-interface=Pos
      KeSMSwPosInvalidVal: parameter-require-com-spec{init-value=4095, parameter=Pos/Val}, required-interface=Pos
      KeSMSwRecoveryDrvStFtUpwdDnwdPos: parameter-require-com-spec{init-value=0, parameter=Pos/Val}, required-interface=Pos
      KeSMSwRecoveryDrvStFtUpwdDnwdPosMax: parameter-require-com-spec{init-value=0, parameter=Pos/Val}, required-interface=Pos
      KeSMSwRecoveryDrvStFtUpwdDnwdPosMin: parameter-require-com-spec{init-value=0, parameter=Pos/Val}, required-interface=Pos
      KeSMSwRecoveryMdSecRwLtStArmScrnPos: parameter-require-com-spec{init-value=4095, parameter=Pos/Val}, required-interface=Pos
      KeSMSwRecoveryMdSecRwLtStArmScrnPosMax: parameter-require-com-spec{init-value=4095, parameter=Pos/Val}, required-interface=Pos
      KeSMSwRecoveryMdSecRwLtStArmScrnPosMin: parameter-require-com-spec{init-value=4095, parameter=Pos/Val}, required-interface=Pos
      KeSMSwRecoveryMdSecRwLtStBkReclnUpwdDnwdPos: parameter-require-com-spec{init-value=1268, parameter=Pos/Val}, required-interface=Pos
      KeSMSwRecoveryMdSecRwLtStBkReclnUpwdDnwdPosMax: parameter-require-com-spec{init-value=1268, parameter=Pos/Val}, required-interface=Pos
      KeSMSwRecoveryMdSecRwLtStBkReclnUpwdDnwdPosMin: parameter-require-com-spec{init-value=0, parameter=Pos/Val}, required-interface=Pos
      KeSMSwRecoveryMdSecRwLtStFrwdBkwdPos: parameter-require-com-spec{init-value=30, parameter=Pos/Val}, required-interface=Pos
      KeSMSwRecoveryMdSecRwLtStFrwdBkwdPosMax: parameter-require-com-spec{init-value=40, parameter=Pos/Val}, required-interface=Pos
      KeSMSwRecoveryMdSecRwLtStFrwdBkwdPosMin: parameter-require-com-spec{init-value=20, parameter=Pos/Val}, required-interface=Pos
      KeSMSwRecoveryMdSecRwLtStHdrstUpwdDnwdPos: parameter-require-com-spec{init-value=30, parameter=Pos/Val}, required-interface=Pos
      KeSMSwRecoveryMdSecRwLtStHdrstUpwdDnwdPosMax: parameter-require-com-spec{init-value=40, parameter=Pos/Val}, required-interface=Pos
      KeSMSwRecoveryMdSecRwLtStHdrstUpwdDnwdPosMin: parameter-require-com-spec{init-value=20, parameter=Pos/Val}, required-interface=Pos
      KeSMSwRecoveryMdSecRwLtStLgrstUpwdDnwdPos: parameter-require-com-spec{init-value=0, parameter=Pos/Val}, required-interface=Pos
      KeSMSwRecoveryMdSecRwLtStLgrstUpwdDnwdPosMax: parameter-require-com-spec{init-value=0, parameter=Pos/Val}, required-interface=Pos
      KeSMSwRecoveryMdSecRwLtStLgrstUpwdDnwdPosMin: parameter-require-com-spec{init-value=0, parameter=Pos/Val}, required-interface=Pos
      KeSMSwRecoveryMdSecRwLtStLtwdRtwdPos: parameter-require-com-spec{init-value=30, parameter=Pos/Val}, required-interface=Pos
      KeSMSwRecoveryMdSecRwLtStLtwdRtwdPosMax: parameter-require-com-spec{init-value=40, parameter=Pos/Val}, required-interface=Pos
      KeSMSwRecoveryMdSecRwLtStLtwdRtwdPosMin: parameter-require-com-spec{init-value=20, parameter=Pos/Val}, required-interface=Pos
      KeSMSwRecoveryMdSecRwRtStArmScrnPos: parameter-require-com-spec{init-value=30, parameter=Pos/Val}, required-interface=Pos
      KeSMSwRecoveryMdSecRwRtStArmScrnPosMax: parameter-require-com-spec{init-value=40, parameter=Pos/Val}, required-interface=Pos
      KeSMSwRecoveryMdSecRwRtStArmScrnPosMin: parameter-require-com-spec{init-value=20, parameter=Pos/Val}, required-interface=Pos
      KeSMSwRecoveryMdSecRwRtStBkReclnUpwdDnwdPos: parameter-require-com-spec{init-value=1268, parameter=Pos/Val}, required-interface=Pos
      KeSMSwRecoveryMdSecRwRtStBkReclnUpwdDnwdPosMax: parameter-require-com-spec{init-value=1268, parameter=Pos/Val}, required-interface=Pos
      KeSMSwRecoveryMdSecRwRtStBkReclnUpwdDnwdPosMin: parameter-require-com-spec{init-value=0, parameter=Pos/Val}, required-interface=Pos
      KeSMSwRecoveryMdSecRwRtStFrwdBkwdPos: parameter-require-com-spec{init-value=30, parameter=Pos/Val}, required-interface=Pos
      KeSMSwRecoveryMdSecRwRtStFrwdBkwdPosMax: parameter-require-com-spec{init-value=40, parameter=Pos/Val}, required-interface=Pos
      KeSMSwRecoveryMdSecRwRtStFrwdBkwdPosMin: parameter-require-com-spec{init-value=20, parameter=Pos/Val}, required-interface=Pos
      KeSMSwRecoveryMdSecRwRtStHdrstUpwdDnwdPos: parameter-require-com-spec{init-value=30, parameter=Pos/Val}, required-interface=Pos
      KeSMSwRecoveryMdSecRwRtStHdrstUpwdDnwdPosMax: parameter-require-com-spec{init-value=40, parameter=Pos/Val}, required-interface=Pos
      KeSMSwRecoveryMdSecRwRtStHdrstUpwdDnwdPosMin: parameter-require-com-spec{init-value=20, parameter=Pos/Val}, required-interface=Pos
      KeSMSwRecoveryMdSecRwRtStLgrstUpwdDnwdPos: parameter-require-com-spec{init-value=0, parameter=Pos/Val}, required-interface=Pos
      KeSMSwRecoveryMdSecRwRtStLgrstUpwdDnwdPosMax: parameter-require-com-spec{init-value=0, parameter=Pos/Val}, required-interface=Pos
      KeSMSwRecoveryMdSecRwRtStLgrstUpwdDnwdPosMin: parameter-require-com-spec{init-value=0, parameter=Pos/Val}, required-interface=Pos
      KeSMSwRecoveryMdSecRwRtStLtwdRtwdPos: parameter-require-com-spec{init-value=30, parameter=Pos/Val}, required-interface=Pos
      KeSMSwRecoveryMdSecRwRtStLtwdRtwdPosMax: parameter-require-com-spec{init-value=40, parameter=Pos/Val}, required-interface=Pos
      KeSMSwRecoveryMdSecRwRtStLtwdRtwdPosMin: parameter-require-com-spec{init-value=20, parameter=Pos/Val}, required-interface=Pos
      KeSMSwRecoveryPassStStFtUpwdDnwdPos: parameter-require-com-spec{init-value=0, parameter=Pos/Val}, required-interface=Pos
      KeSMSwRecoveryPassStStFtUpwdDnwdPosMax: parameter-require-com-spec{init-value=0, parameter=Pos/Val}, required-interface=Pos
      KeSMSwRecoveryPassStStFtUpwdDnwdPosMin: parameter-require-com-spec{init-value=0, parameter=Pos/Val}, required-interface=Pos
      KeSMSwSecRwLtStEasyEntryCllsnPt: parameter-require-com-spec{init-value=20, parameter=Pos/Val}, required-interface=Pos
      KeSMSwSecRwLtStVIPCllsnPt: parameter-require-com-spec{init-value=20, parameter=Pos/Val}, required-interface=Pos
      KeSMSwSecRwRtStEasyEntryCllsnPt: parameter-require-com-spec{init-value=20, parameter=Pos/Val}, required-interface=Pos
      KeSMSwSecRwRtStVIPCllsnPt: parameter-require-com-spec{init-value=20, parameter=Pos/Val}, required-interface=Pos
      KeSMSwVIPMDDrvStFtUpwdDnwdPos: parameter-require-com-spec{init-value=0, parameter=Pos/Val}, required-interface=Pos
      KeSMSwVIPMDDrvStFtUpwdDnwdPosMax: parameter-require-com-spec{init-value=0, parameter=Pos/Val}, required-interface=Pos
      KeSMSwVIPMDDrvStFtUpwdDnwdPosMin: parameter-require-com-spec{init-value=0, parameter=Pos/Val}, required-interface=Pos
      KeSMSwVIPMDPassStStFtUpwdDnwdPos: parameter-require-com-spec{init-value=0, parameter=Pos/Val}, required-interface=Pos
      KeSMSwVIPMDPassStStFtUpwdDnwdPosMax: parameter-require-com-spec{init-value=0, parameter=Pos/Val}, required-interface=Pos
      KeSMSwVIPMDPassStStFtUpwdDnwdPosMin: parameter-require-com-spec{init-value=0, parameter=Pos/Val}, required-interface=Pos
      KeSMSwVIPSecRwLtStArmScrnPos: parameter-require-com-spec{init-value=30, parameter=Pos/Val}, required-interface=Pos
      KeSMSwVIPSecRwLtStArmScrnPosMax: parameter-require-com-spec{init-value=40, parameter=Pos/Val}, required-interface=Pos
      KeSMSwVIPSecRwLtStArmScrnPosMin: parameter-require-com-spec{init-value=20, parameter=Pos/Val}, required-interface=Pos
      KeSMSwVIPSecRwLtStBkReclnUpwdDnwdPos: parameter-require-com-spec{init-value=1960, parameter=Pos/Val}, required-interface=Pos
      KeSMSwVIPSecRwLtStBkReclnUpwdDnwdPosMax: parameter-require-com-spec{init-value=1960, parameter=Pos/Val}, required-interface=Pos
      KeSMSwVIPSecRwLtStBkReclnUpwdDnwdPosMin: parameter-require-com-spec{init-value=1960, parameter=Pos/Val}, required-interface=Pos
      KeSMSwVIPSecRwLtStFrwdBkwdPos: parameter-require-com-spec{init-value=2920, parameter=Pos/Val}, required-interface=Pos
      KeSMSwVIPSecRwLtStFrwdBkwdPosMax: parameter-require-com-spec{init-value=2920, parameter=Pos/Val}, required-interface=Pos
      KeSMSwVIPSecRwLtStFrwdBkwdPosMin: parameter-require-com-spec{init-value=2920, parameter=Pos/Val}, required-interface=Pos
      KeSMSwVIPSecRwLtStHdrstUpwdPos: parameter-require-com-spec{init-value=30, parameter=Pos/Val}, required-interface=Pos
      KeSMSwVIPSecRwLtStHdrstUpwdPosMax: parameter-require-com-spec{init-value=40, parameter=Pos/Val}, required-interface=Pos
      KeSMSwVIPSecRwLtStHdrstUpwdPosMin: parameter-require-com-spec{init-value=20, parameter=Pos/Val}, required-interface=Pos
      KeSMSwVIPSecRwLtStLgrstUpwdPos: parameter-require-com-spec{init-value=4000, parameter=Pos/Val}, required-interface=Pos
      KeSMSwVIPSecRwLtStLgrstUpwdPosMax: parameter-require-com-spec{init-value=4000, parameter=Pos/Val}, required-interface=Pos
      KeSMSwVIPSecRwLtStLgrstUpwdPosMin: parameter-require-com-spec{init-value=4000, parameter=Pos/Val}, required-interface=Pos
      KeSMSwVIPSecRwLtStLtwdRtwdPos: parameter-require-com-spec{init-value=4000, parameter=Pos/Val}, required-interface=Pos
      KeSMSwVIPSecRwLtStLtwdRtwdPosMax: parameter-require-com-spec{init-value=4000, parameter=Pos/Val}, required-interface=Pos
      KeSMSwVIPSecRwLtStLtwdRtwdPosMin: parameter-require-com-spec{init-value=4000, parameter=Pos/Val}, required-interface=Pos
      KeSMSwVIPSecRwRtStArmScrnPos: parameter-require-com-spec{init-value=30, parameter=Pos/Val}, required-interface=Pos
      KeSMSwVIPSecRwRtStArmScrnPosMax: parameter-require-com-spec{init-value=40, parameter=Pos/Val}, required-interface=Pos
      KeSMSwVIPSecRwRtStArmScrnPosMin: parameter-require-com-spec{init-value=20, parameter=Pos/Val}, required-interface=Pos
      KeSMSwVIPSecRwRtStBkReclnUpwdDnwdPos: parameter-require-com-spec{init-value=1960, parameter=Pos/Val}, required-interface=Pos
      KeSMSwVIPSecRwRtStBkReclnUpwdDnwdPosMax: parameter-require-com-spec{init-value=40, parameter=Pos/Val}, required-interface=Pos
      KeSMSwVIPSecRwRtStBkReclnUpwdDnwdPosMin: parameter-require-com-spec{init-value=1960, parameter=Pos/Val}, required-interface=Pos
      KeSMSwVIPSecRwRtStFrwdBkwdPos: parameter-require-com-spec{init-value=2920, parameter=Pos/Val}, required-interface=Pos
      KeSMSwVIPSecRwRtStFrwdBkwdPosMax: parameter-require-com-spec{init-value=2920, parameter=Pos/Val}, required-interface=Pos
      KeSMSwVIPSecRwRtStFrwdBkwdPosMin: parameter-require-com-spec{init-value=2920, parameter=Pos/Val}, required-interface=Pos
      KeSMSwVIPSecRwRtStHdrstUpwdPos: parameter-require-com-spec{init-value=30, parameter=Pos/Val}, required-interface=Pos
      KeSMSwVIPSecRwRtStHdrstUpwdPosMax: parameter-require-com-spec{init-value=40, parameter=Pos/Val}, required-interface=Pos
      KeSMSwVIPSecRwRtStHdrstUpwdPosMin: parameter-require-com-spec{init-value=20, parameter=Pos/Val}, required-interface=Pos
      KeSMSwVIPSecRwRtStLgrstUpwdPos: parameter-require-com-spec{init-value=4000, parameter=Pos/Val}, required-interface=Pos
      KeSMSwVIPSecRwRtStLgrstUpwdPosMax: parameter-require-com-spec{init-value=4000, parameter=Pos/Val}, required-interface=Pos
      KeSMSwVIPSecRwRtStLgrstUpwdPosMin: parameter-require-com-spec{init-value=20, parameter=Pos/Val}, required-interface=Pos
      KeSMSwVIPSecRwRtStLtwdRtwdPos: parameter-require-com-spec{init-value=0, parameter=Pos/Val}, required-interface=Pos
      KeSMSwVIPSecRwRtStLtwdRtwdPosMax: parameter-require-com-spec{init-value=40, parameter=Pos/Val}, required-interface=Pos
      KeSMSwVIPSecRwRtStLtwdRtwdPosMin: parameter-require-com-spec{init-value=0, parameter=Pos/Val}, required-interface=Pos
      KeSMSwVIPThdRwLtStBkReclnUpwdDnwdPos: parameter-require-com-spec{init-value=0, parameter=Pos/Val}, required-interface=Pos
      KeSMSwVIPThdRwLtStBkReclnUpwdDnwdPosMax: parameter-require-com-spec{init-value=0, parameter=Pos/Val}, required-interface=Pos
      KeSMSwVIPThdRwLtStBkReclnUpwdDnwdPosMin: parameter-require-com-spec{init-value=0, parameter=Pos/Val}, required-interface=Pos
      KeSMSwVIPThdRwLtStCshnFldUpwdDnwdPos: parameter-require-com-spec{init-value=4000, parameter=Pos/Val}, required-interface=Pos
      KeSMSwVIPThdRwLtStCshnFldUpwdDnwdPosMax: parameter-require-com-spec{init-value=4000, parameter=Pos/Val}, required-interface=Pos
      KeSMSwVIPThdRwLtStCshnFldUpwdDnwdPosMin: parameter-require-com-spec{init-value=4000, parameter=Pos/Val}, required-interface=Pos
      KeSMSwVIPThdRwLtStFrwdBkwdPos: parameter-require-com-spec{init-value=4000, parameter=Pos/Val}, required-interface=Pos
      KeSMSwVIPThdRwLtStFrwdBkwdPosMax: parameter-require-com-spec{init-value=4000, parameter=Pos/Val}, required-interface=Pos
      KeSMSwVIPThdRwLtStFrwdBkwdPosMin: parameter-require-com-spec{init-value=4000, parameter=Pos/Val}, required-interface=Pos
      KeSMSwVIPThdRwRtStBkReclnUpwdDnwdPos: parameter-require-com-spec{init-value=0, parameter=Pos/Val}, required-interface=Pos
      KeSMSwVIPThdRwRtStBkReclnUpwdDnwdPosMax: parameter-require-com-spec{init-value=0, parameter=Pos/Val}, required-interface=Pos
      KeSMSwVIPThdRwRtStBkReclnUpwdDnwdPosMin: parameter-require-com-spec{init-value=0, parameter=Pos/Val}, required-interface=Pos
      KeSMSwVIPThdRwRtStCshnFldUpwdDnwdPos: parameter-require-com-spec{init-value=4000, parameter=Pos/Val}, required-interface=Pos
      KeSMSwVIPThdRwRtStCshnFldUpwdDnwdPosMax: parameter-require-com-spec{init-value=40, parameter=Pos/Val}, required-interface=Pos
      KeSMSwVIPThdRwRtStCshnFldUpwdDnwdPosMin: parameter-require-com-spec{init-value=4000, parameter=Pos/Val}, required-interface=Pos
      KeSMSwVIPThdRwRtStFrwdBkwdPos: parameter-require-com-spec{init-value=4000, parameter=Pos/Val}, required-interface=Pos
      KeSMSwVIPThdRwRtStFrwdBkwdPosMax: parameter-require-com-spec{init-value=4000, parameter=Pos/Val}, required-interface=Pos
      KeSMSwVIPThdRwRtStFrwdBkwdPosMin: parameter-require-com-spec{init-value=4000, parameter=Pos/Val}, required-interface=Pos
      modestate32: nonqueued-receiver-com-spec{data-element=modestate32/Val, filter=data-filter-type=ALWAYS, init-value=0}, required-interface=modestate32
      PwrMdChked: nonqueued-receiver-com-spec{data-element=PowerMode/Val, filter=data-filter-type=ALWAYS, init-value=0}, required-interface=PowerMode
